VERSION ""

NS_ :

BS_:

BU_: VMM IMR BCS GSM EMS EPB SRS TEL ICM ACU VCU WCM TSCM Tester Test SCMRR SCMRL SCM SBM RCP PSDR PSDL PLGM PAS LCU IHU IBCM IAL HVSPRR HVSPRL HVSMR HVSM HVACF HUD GWM FRDCM FLDCM FCP FAPA ETC Diagnostic Messages AVAS AMP
VAL_TABLE_ VCU_VehDrvModNew 6 "reserved;" 5 "SPORT Mode;" 4 "Individual mode;" 3 "Comfort Mode;" 2 "ECO Mode;" 1 "reserved;" 0 "Invalid;" ;
VAL_TABLE_ VtSIg_VCU_EVPRepair 1 "EVP service" 0 "Normal" ;

BO_ 3221225472 VECTOR__INDEPENDENT_SIG_MSG: 0 Vector__XXX
 SG_ ACU_FCWSeatbeltPretensionWarnCfg : 0|2@0+ (1,0) [0|3] "" Vector__XXX
 SG_ ACU_FCWSeatVibrationWarnCfg : 0|2@0+ (1,0) [0|3] "" Vector__XXX
 SG_ ACU_FCWAcousticWarnCfg : 0|2@0+ (1,0) [0|3] "" Vector__XXX
 SG_ ACU_ACCStyleCfg : 0|2@0+ (1,0) [0|3] "" Vector__XXX
 SG_ ACU_BCMHornCfg : 0|2@0+ (1,0) [0|3] "" Vector__XXX
 SG_ ACU_BCMDTRLFuncCfg : 0|2@0+ (1,0) [0|3] "" Vector__XXX
 SG_ ACU_BCMRGearEnableRearWipeCfg : 0|2@0+ (1,0) [0|3] "" Vector__XXX
 SG_ ACU_BCMAutoLightSnsCfg : 0|3@0+ (1,0) [0|7] "" Vector__XXX
 SG_ ACU_BCMFollowMeHomeCfg : 0|2@0+ (1,0) [0|3] "" Vector__XXX
 SG_ ACU_BCMAutoUnlockCfg : 0|2@0+ (1,0) [0|3] "" Vector__XXX
 SG_ ACU_BCMRemoteUnlockCfg : 0|2@0+ (1,0) [0|3] "" Vector__XXX
 SG_ ACU_BCMFogLampTurnCfg : 0|2@0+ (1,0) [0|3] "" Vector__XXX
 SG_ ACU_BCMRemoteCtrlFDMRMCfg : 0|2@0+ (1,0) [0|3] "" Vector__XXX
 SG_ ACU_KickSnsCfg : 0|2@0+ (1,0) [0|3] "" Vector__XXX
 SG_ ACU_MaxTeleEngTimerCfg : 0|6@0+ (1,0) [0|30] "min" Vector__XXX
 SG_ ACU_PEPSOffCfg : 0|2@0+ (1,0) [0|3] "" Vector__XXX
 SG_ ACU_MaxTeleIGNOnTimerCfg : 0|6@0+ (1,0) [0|30] "min" Vector__XXX
 SG_ ACU_PEPSAPUCfg : 0|2@0+ (1,0) [0|3] "" Vector__XXX
 SG_ ACU_PEPSWALCfg : 0|2@0+ (1,0) [0|3] "" Vector__XXX
 SG_ ACU_ICMLanguageCfg : 0|2@0+ (1,0) [0|3] "" Vector__XXX
 SG_ ACU_ICMTimeModeCfg : 0|2@0+ (1,0) [0|3] "" Vector__XXX
 SG_ ACU_ICMWarnSoundVolCfg : 0|2@0+ (1,0) [0|3] "" Vector__XXX
 SG_ ACU_ICMSpdWarnCfg : 0|5@0+ (10,0) [0|200] "km/h" Vector__XXX
 SG_ ACU_PEPSSATOCfg : 0|2@0+ (1,0) [0|3] "" Vector__XXX
 SG_ ACU_PEPSWELCfg : 0|2@0+ (1,0) [0|3] "" Vector__XXX
 SG_ ACU_BCMOSRMAutoFoldCfg : 0|2@0+ (1,0) [0|3] "" Vector__XXX
 SG_ ACU_MSMKeyRecognitionCfg : 0|2@0+ (1,0) [0|3] "" Vector__XXX
 SG_ ACU_MSMWelcomeFuncCfg : 0|2@0+ (1,0) [0|3] "" Vector__XXX
 SG_ ACU_HVACFComfortCfg : 0|2@0+ (1,0) [0|3] "" Vector__XXX
 SG_ ACU_HVACFAirCirCfg : 0|2@0+ (1,0) [0|3] "" Vector__XXX
 SG_ ACU_HVACFACCfg : 0|2@0+ (1,0) [0|3] "" Vector__XXX
 SG_ ACU_LDW_WarnSnsCfg : 0|2@0+ (1,0) [0|3] "" Vector__XXX
 SG_ TEL_BTAvrcpPlayMode : 0|3@0+ (1,0) [0|7] "" Vector__XXX
 SG_ TEL_TelematicsRegisterSt : 0|3@0+ (1,0) [0|7] "" Vector__XXX
 SG_ TEL_BTAutoconectingSt : 0|1@0+ (1,0) [0|1] "" Vector__XXX
 SG_ TEL_BTPowerSt : 0|1@0+ (1,0) [0|1] "" Vector__XXX
 SG_ TEL_BTManualMode : 0|2@0+ (1,0) [0|3] "" Vector__XXX
 SG_ TEL_BTHisdel : 0|1@0+ (1,0) [0|1] "" Vector__XXX
 SG_ TEL_BTHandfreeSt : 0|1@0+ (1,0) [0|1] "" Vector__XXX
 SG_ TEL_BTAvrcpSt : 0|1@0+ (1,0) [0|1] "" Vector__XXX
 SG_ TEL_TelematicsModeActSt : 0|3@0+ (1,0) [0|7] "" Vector__XXX
 SG_ ACU_EVSwRq : 0|2@0+ (1,0) [0|3] "-" Vector__XXX
 SG_ BCS_2_Checksum : 0|8@0+ (1,0) [0|255] "" Vector__XXX
 SG_ BCS_2_MsgCounter : 0|4@0+ (1,0) [0|15] "" Vector__XXX
 SG_ BCM_BCAN_2_Checksum : 0|8@0+ (1,0) [0|255] "" Vector__XXX
 SG_ BCM_BCAN_2_MsgCounter : 0|4@0+ (1,0) [0|15] "" Vector__XXX
 SG_ ADAS_HWA_ILCWaitReasonLeft : 0|10@0+ (1,0) [0|1023] "" Vector__XXX
 SG_ ADAS_HWA_ILCWaitReasonRight : 0|10@0+ (1,0) [0|1023] "" Vector__XXX
 SG_ PAS_Mode : 0|3@0+ (1,0) [0|7] "-" Vector__XXX
 SG_ ICM_SetPedalLevelUp : 0|1@0+ (1,0) [0|1] "" Vector__XXX
 SG_ ICM_SetPedalLevelDown : 0|1@0+ (1,0) [0|1] "" Vector__XXX
 SG_ ACU_IFC_ZoneCode : 0|3@0+ (1,0) [0|7] "" Vector__XXX
 SG_ ACU_IFC_SpeedLimitUnit : 0|2@0+ (1,0) [0|3] "" Vector__XXX
 SG_ ACU_IFC_SpeedLimit : 0|8@0+ (1,0) [0|255] "km/h" Vector__XXX
 SG_ ACU_IFC_RoadType : 0|6@0+ (1,0) [0|63] "" Vector__XXX
 SG_ SRS_1_Checksum : 0|8@0+ (1,0) [0|255] "" Vector__XXX
 SG_ SRS_1_MsgCounter : 0|4@0+ (1,0) [0|15] "" Vector__XXX
 SG_ ICM_TripB : 0|14@0+ (0.1,0) [0|999.9] "km" Vector__XXX
 SG_ ICM_TripBVD : 0|1@0+ (1,0) [0|1] "" Vector__XXX
 SG_ ICM_TripA : 0|14@0+ (0.1,0) [0|999.9] "km" Vector__XXX
 SG_ ICM_TripAVD : 0|1@0+ (1,0) [0|1] "" Vector__XXX
 SG_ ICM_VehAverageSpd : 0|8@0+ (1,0) [0|254] "km/h" Vector__XXX
 SG_ VCU_AGSErr : 0|1@0+ (1,0) [0|1] "" Vector__XXX

BO_ 0 New_Message_209: 8 Vector__XXX
 SG_ New_Signal_2103 : 0|8@1+ (1,0) [0|0] "" Vector__XXX

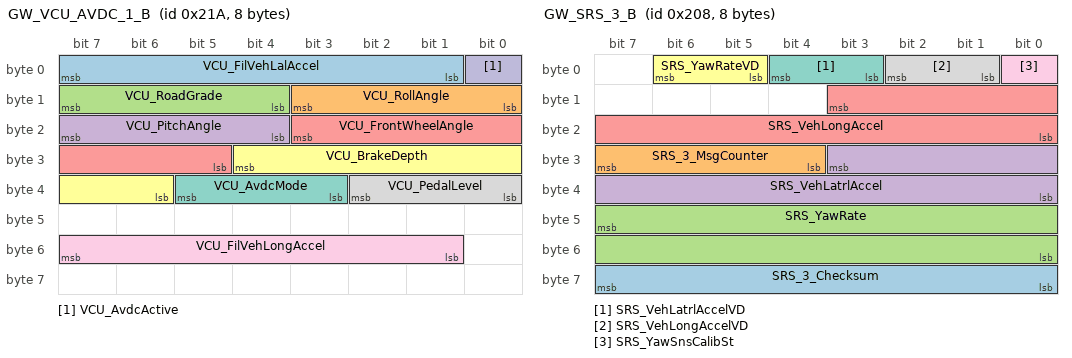
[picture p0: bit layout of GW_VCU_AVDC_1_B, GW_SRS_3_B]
BO_ 538 GW_VCU_AVDC_1_B: 8 GWM
 SG_ VCU_FilVehLalAccel : 7|7@0+ (0.15625,-10) [-10|9.84] "m/s2"  IHU
 SG_ VCU_RollAngle : 11|4@0+ (1,-8) [-5|5] "°"  IHU
 SG_ VCU_RoadGrade : 15|4@0+ (1,-8) [-8|7] "-"  IHU
 SG_ VCU_PitchAngle : 23|4@0+ (0.5,-4) [-3|3] "°"  IHU
 SG_ VCU_FrontWheelAngle : 19|7@0+ (1,-64) [-35|35] "°"  IHU
 SG_ VCU_BrakeDepth : 28|7@0+ (1,0) [0|100] ""  IHU
 SG_ VCU_AvdcMode : 37|3@0+ (1,0) [0|5] ""  IHU
 SG_ VCU_PedalLevel : 34|3@0+ (1,0) [1|5] ""  IHU
 SG_ VCU_FilVehLongAccel : 55|7@0+ (0.156,-10) [-10|9.84] ""  IHU
 SG_ VCU_AvdcActive : 0|1@0+ (1,0) [0|1] ""  IHU

BO_ 539 ICM_8_B: 8 IHU
 SG_ ICM_FuelTotalodometer : 19|20@0+ (1,0) [0|999999] ""  GWM
 SG_ ICM_EVTotalodometer : 7|20@0+ (1,0) [0|999999] ""  GWM

BO_ 880 GW_VCU_14_A_B: 8 GWM
 SG_ VCU_GasPedalActPstforMRR : 47|8@0+ (0.392,0) [0|99.96] ""  IHU
 SG_ VCU_GasPedalActPstforMRRVD : 27|1@0+ (1,0) [0|1] ""  IHU

BO_ 924 GW_IPS_OBC_1_B: 8 GWM
 SG_ IPS_OBCCC_St : 7|3@0+ (1,0) [0|7] ""  IHU

BO_ 520 GW_SRS_3_B: 8 GWM
 SG_ SRS_3_Checksum : 56|8@1- (1,0) [0|255] ""  IHU
 SG_ SRS_3_MsgCounter : 31|4@0+ (1,0) [0|15] ""  IHU
 SG_ SRS_YawRate : 47|16@0+ (0.01,-180) [-180|180] ""  IHU
 SG_ SRS_VehLatrlAccel : 27|12@0+ (0.001,-2) [-2|2] ""  IHU
 SG_ SRS_VehLongAccel : 11|12@0+ (0.001,-2) [-2|2] ""  IHU
 SG_ SRS_YawRateVD : 6|2@0+ (1,0) [0|3] ""  IHU
 SG_ SRS_VehLatrlAccelVD : 4|2@0+ (1,0) [0|3] ""  IHU
 SG_ SRS_VehLongAccelVD : 2|2@0+ (1,0) [0|3] ""  IHU
 SG_ SRS_YawSnsCalibSt : 0|1@0+ (1,0) [0|1] ""  IHU

BO_ 1536 GW_EMS_12_B: 8 GWM
 SG_ EMS_FrontWheelAngle : 19|7@0+ (1,-64) [-35|35] ""  IHU
 SG_ EMS_BrakeDepth : 28|7@0+ (1,0) [0|100] ""  IHU

BO_ 119 GW_TEL_16_B: 8 GWM
 SG_ TEL_ACU_VehSearchReq : 6|1@0+ (1,0) [0|1] ""  IHU

BO_ 1567 BCM_RLS_1_B: 8 IBCM
 SG_ RLS_RainfallLevel : 23|4@0+ (1,0) [0|15] ""  IHU

BO_ 412 GW_IFC_2_B: 8 GWM
 SG_ IFC_AssistParaSwitchReq : 54|1@0+ (1,0) [0|1] ""  IHU

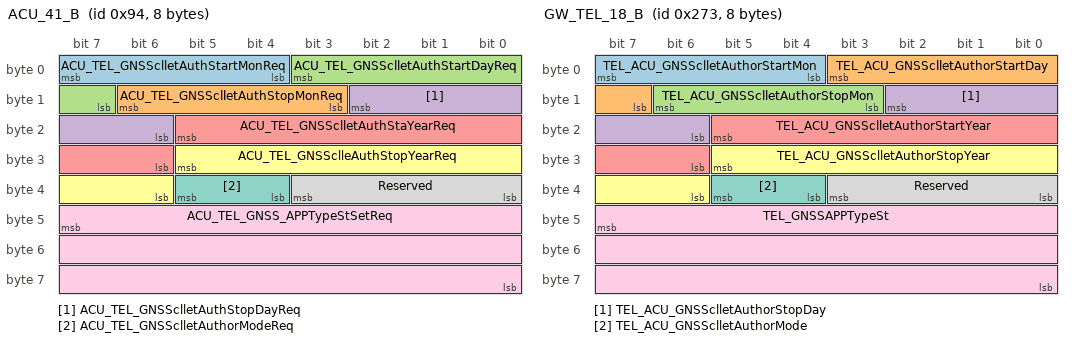
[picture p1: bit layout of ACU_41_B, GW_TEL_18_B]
BO_ 148 ACU_41_B: 8 IHU
 SG_ ACU_TEL_GNSSclletAuthStartMonReq : 7|4@0+ (1,0) [0|12] "" Vector__XXX
 SG_ ACU_TEL_GNSSclletAuthStopMonReq : 14|4@0+ (1,0) [0|12] "" Vector__XXX
 SG_ ACU_TEL_GNSSclletAuthStartDayReq : 3|5@0+ (1,0) [0|31] "" Vector__XXX
 SG_ ACU_TEL_GNSSclletAuthStopDayReq : 10|5@0+ (1,0) [0|31] "" Vector__XXX
 SG_ ACU_TEL_GNSSclletAuthStaYearReq : 21|8@0+ (1,2000) [2000|2255] "" Vector__XXX
 SG_ ACU_TEL_GNSSclleAuthStopYearReq : 29|8@0+ (1,2000) [2000|2255] "" Vector__XXX
 SG_ ACU_TEL_GNSSclletAuthorModeReq : 37|2@0+ (1,0) [0|3] "" Vector__XXX
 SG_ Reserved : 35|4@0+ (1,0) [0|15] "" Vector__XXX
 SG_ ACU_TEL_GNSS_APPTypeStSetReq : 47|24@0+ (1,0) [0|16777215] "" Vector__XXX

BO_ 627 GW_TEL_18_B: 8 GWM
 SG_ TEL_ACU_GNSSclletAuthorStartMon : 7|4@0+ (1,0) [0|12] ""  IHU
 SG_ TEL_ACU_GNSSclletAuthorStartDay : 3|5@0+ (1,0) [0|31] ""  IHU
 SG_ TEL_ACU_GNSSclletAuthorStopMon : 14|4@0+ (1,0) [0|12] ""  IHU
 SG_ TEL_ACU_GNSSclletAuthorStopDay : 10|5@0+ (1,0) [0|31] ""  IHU
 SG_ TEL_ACU_GNSSclletAuthorStartYear : 21|8@0+ (1,2000) [2000|2255] ""  IHU
 SG_ TEL_ACU_GNSSclletAuthorStopYear : 29|8@0+ (1,2000) [2000|2255] ""  IHU
 SG_ TEL_ACU_GNSSclletAuthorMode : 37|2@0+ (1,0) [0|3] ""  IHU
 SG_ Reserved : 35|4@0+ (1,0) [0|15] ""  IHU
 SG_ TEL_GNSSAPPTypeSt : 47|24@0+ (1,0) [0|16777215] ""  IHU

BO_ 886 GW_BCS_18_B: 8 GWM
 SG_ BCS_HDCFuncResp : 7|2@0+ (1,0) [0|3] ""  IHU
 SG_ BCS_ESPFuncResp : 5|2@0+ (1,0) [0|3] ""  IHU

BO_ 179 FAPA_2_B: 8 FAPA
 SG_ APA_VoiceReminder : 23|12@0+ (1,0) [0|4095] ""  IHU

BO_ 837 FAPA_PCS_1: 8 FAPA
 SG_ PCS_MirrorPageDownButton : 59|1@0+ (1,0) [0|1] ""  IHU
 SG_ PCS_ER_QuitReq : 58|1@0+ (1,0) [0|1] ""  IHU
 SG_ PCS_ER_EnterConfirm : 57|1@0+ (1,0) [0|1] ""  IHU
 SG_ PCS_ACU_DisplayReq : 56|1@0+ (1,0) [0|1] ""  IHU
 SG_ PCS_SoundReminderSt : 55|1@0+ (1,0) [0|1] ""  IHU
 SG_ PCS_HelpMenuSt : 54|1@0+ (1,0) [0|1] ""  IHU
 SG_ PCS_ReturnSt : 53|1@0+ (1,0) [0|1] ""  IHU
 SG_ PCS_RightBlindSpotViewSt : 52|1@0+ (1,0) [0|1] ""  IHU
 SG_ PCS_LeftBlindSpotViewSt : 51|1@0+ (1,0) [0|1] ""  IHU
 SG_ PCS_RVMButtonGroup : 50|3@0+ (1,0) [0|7] ""  IHU
 SG_ PCS_OperationSt : 41|2@0+ (1,0) [0|3] ""  IHU
 SG_ PCS_3DEnalbe : 39|1@0+ (1,0) [0|1] ""  IHU
 SG_ PCS_MODEnalbe : 38|1@0+ (1,0) [0|1] ""  IHU
 SG_ PCS_PASButtonPress : 37|1@0+ (1,0) [0|1] ""  IHU
 SG_ PCS_SteerIconInd : 36|3@0+ (1,0) [0|7] ""  IHU
 SG_ PCS_SteerWheelTurnDirInd : 33|2@0+ (1,0) [0|3] ""  IHU
 SG_ PCS_GuidOverlaySt : 31|2@0+ (1,0) [0|3] ""  IHU
 SG_ PCS_DriveDirInd : 29|2@0+ (1,0) [0|3] ""  IHU
 SG_ PCS_SystemType : 11|2@0+ (1,0) [0|3] ""  IHU
 SG_ PCS_VoiceReq : 27|4@0+ (1,0) [0|15] ""  IHU
 SG_ PCS_SingleViewInd : 23|4@0+ (1,0) [0|15] ""  IHU
 SG_ PCS_HMIIndex : 19|4@0+ (1,0) [0|15] ""  IHU
 SG_ PCS_EventRecordSt : 15|1@0+ (1,0) [0|1] ""  IHU
 SG_ PCS_CalibrateSt : 14|3@0+ (1,0) [0|7] ""  IHU
 SG_ PCS_VRSwitchFailSt : 1|1@0+ (1,0) [0|1] ""  IHU
 SG_ PCS_SystemSt : 0|1@0+ (1,0) [0|1] ""  IHU

BO_ 898 GW_BMS_7_B: 8 GWM
 SG_ BMS_BattSOE : 19|14@0+ (0.01,0) [0|163.83] "kWh"  IHU

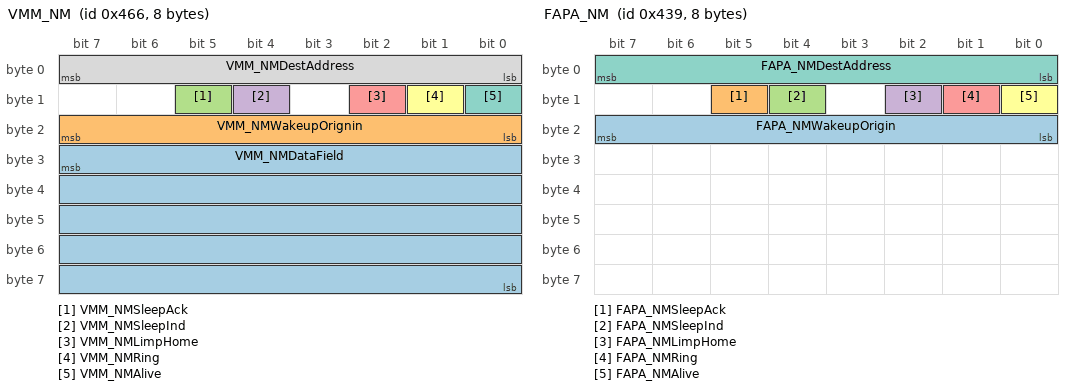
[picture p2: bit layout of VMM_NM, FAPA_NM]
BO_ 1126 VMM_NM: 8 VMM
 SG_ VMM_NMDataField : 31|40@0+ (1,0) [0|1] ""  IHU
 SG_ VMM_NMWakeupOrignin : 23|8@0+ (1,0) [0|255] ""  IHU
 SG_ VMM_NMSleepAck : 13|1@0+ (1,0) [0|1] ""  IHU
 SG_ VMM_NMSleepInd : 12|1@0+ (1,0) [0|1] ""  IHU
 SG_ VMM_NMLimpHome : 10|1@0+ (1,0) [0|1] ""  IHU
 SG_ VMM_NMRing : 9|1@0+ (1,0) [0|1] ""  IHU
 SG_ VMM_NMAlive : 8|1@0+ (1,0) [0|1] ""  IHU
 SG_ VMM_NMDestAddress : 7|8@0+ (1,0) [0|255] ""  IHU

BO_ 34 VMM_2_B: 8 VMM
 SG_ VMM_FailtureReasonSt : 2|3@0+ (1,0) [0|7] ""  IHU

BO_ 869 VMM_1_B: 8 VMM
 SG_ VMM_Crash_Flg : 53|1@0+ (1,0) [0|1] ""  IHU
 SG_ VMM_SysCfgst : 52|1@0+ (1,0) [0|1] ""  IHU
 SG_ VMM_WarningTpyCfgst : 51|1@0+ (1,0) [0|1] ""  IHU
 SG_ VMM_SnsCfgSt : 50|3@0+ (1,0) [0|7] ""  IHU
 SG_ VMM_WarningType : 17|2@0+ (1,0) [0|3] ""  IHU

BO_ 1081 FAPA_NM: 8 FAPA
 SG_ FAPA_NMWakeupOrigin : 23|8@0+ (1,0) [0|255] ""  IHU
 SG_ FAPA_NMSleepAck : 13|1@0+ (1,0) [0|1] ""  IHU
 SG_ FAPA_NMSleepInd : 12|1@0+ (1,0) [0|1] ""  IHU
 SG_ FAPA_NMLimpHome : 10|1@0+ (1,0) [0|1] ""  IHU
 SG_ FAPA_NMRing : 9|1@0+ (1,0) [0|1] ""  IHU
 SG_ FAPA_NMAlive : 8|1@0+ (1,0) [0|1] ""  IHU
 SG_ FAPA_NMDestAddress : 7|8@0+ (1,0) [0|255] ""  IHU

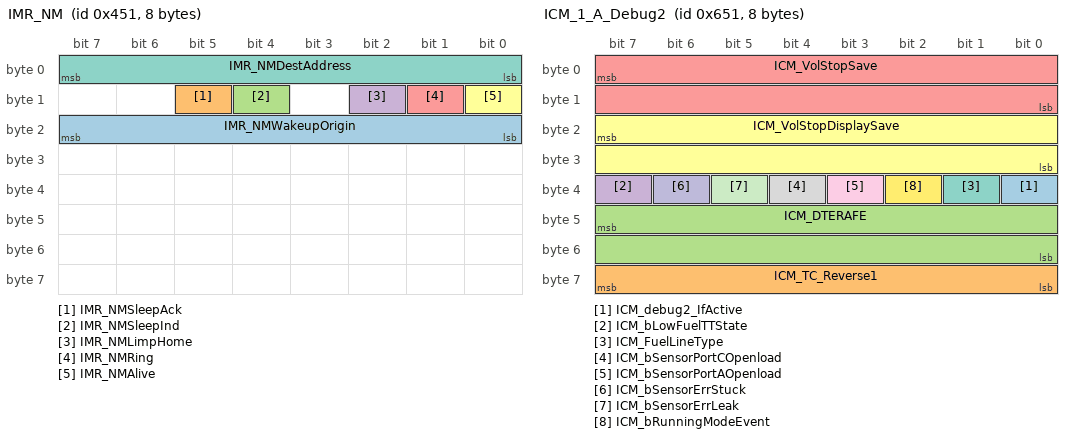
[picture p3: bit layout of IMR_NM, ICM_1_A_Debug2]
BO_ 1105 IMR_NM: 8 IMR
 SG_ IMR_NMWakeupOrigin : 23|8@0+ (1,0) [0|255] ""  IHU
 SG_ IMR_NMSleepAck : 13|1@0+ (1,0) [0|1] ""  IHU
 SG_ IMR_NMSleepInd : 12|1@0+ (1,0) [0|1] ""  IHU
 SG_ IMR_NMLimpHome : 10|1@0+ (1,0) [0|1] ""  IHU
 SG_ IMR_NMRing : 9|1@0+ (1,0) [0|1] ""  IHU
 SG_ IMR_NMAlive : 8|1@0+ (1,0) [0|1] ""  IHU
 SG_ IMR_NMDestAddress : 7|8@0+ (1,0) [0|22] ""  IHU

BO_ 648 GW_BCS_20_P_B: 8 GWM
 SG_ BCS_BrakeFluid_Warning : 45|2@0+ (1,0) [0|3] ""  IHU
 SG_ BCS_CST_Status : 40|2@0+ (1,0) [0|3] ""  IHU
 SG_ BCS_TwoFoot_DriveWarning : 41|1@0+ (1,0) [0|1] ""  IHU
 SG_ BCS_System_Status : 32|3@0+ (1,0) [0|7] ""  IHU
 SG_ BCS_FWA_warning : 34|2@0+ (1,0) [0|3] ""  IHU

BO_ 1617 ICM_1_A_Debug2: 8 IHU
 SG_ ICM_debug2_IfActive : 32|1@0+ (1,0) [0|1] "" Vector__XXX
 SG_ ICM_TC_Reverse1 : 63|8@0+ (1,0) [0|0] ""  Test,Tester
 SG_ ICM_DTERAFE : 47|16@0+ (0.1,0) [0|6553.5] "L/100km"  Test,Tester
 SG_ ICM_bLowFuelTTState : 39|1@0+ (1,0) [0|1] ""  Test,Tester
 SG_ ICM_VolStopSave : 7|16@0+ (0.001,0) [0|65.535] "L"  Test,Tester
 SG_ ICM_VolStopDisplaySave : 23|16@0+ (0.001,0) [0|65.535] "L"  Test,Tester
 SG_ ICM_FuelLineType : 33|1@0+ (1,0) [0|1] ""  Test,Tester
 SG_ ICM_bSensorPortCOpenload : 36|1@0+ (1,0) [0|1] ""  Test,Tester
 SG_ ICM_bSensorPortAOpenload : 35|1@0+ (1,0) [0|1] ""  Test,Tester
 SG_ ICM_bSensorErrStuck : 38|1@0+ (1,0) [0|1] ""  Test,Tester
 SG_ ICM_bSensorErrLeak : 37|1@0+ (1,0) [0|1] ""  Test,Tester
 SG_ ICM_bRunningModeEvent : 34|1@0+ (1,0) [0|1] ""  Test,Tester

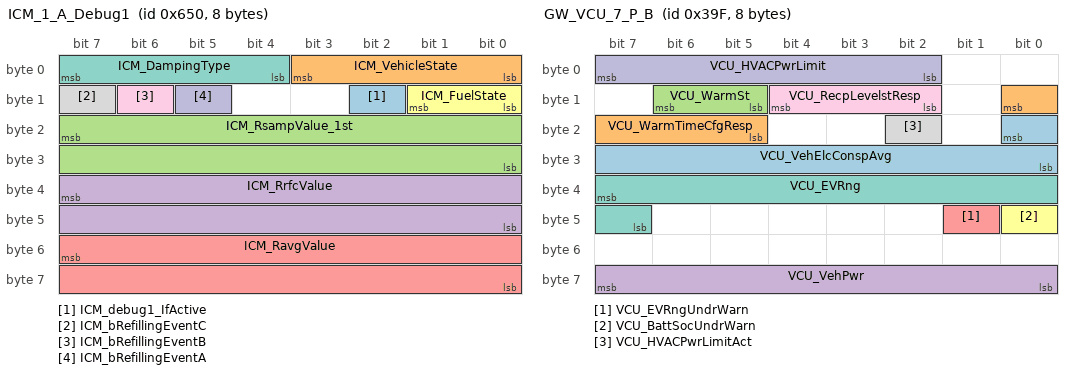
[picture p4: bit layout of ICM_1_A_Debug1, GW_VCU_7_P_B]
BO_ 1616 ICM_1_A_Debug1: 8 IHU
 SG_ ICM_debug1_IfActive : 10|1@0+ (1,0) [0|1] "" Vector__XXX
 SG_ ICM_VehicleState : 3|4@0+ (1,0) [0|15] ""  Test,Tester
 SG_ ICM_RsampValue_1st : 23|16@0+ (0.1,0) [0|6553.5] "ohm"  Test,Tester
 SG_ ICM_RrfcValue : 39|16@0+ (1,-50) [-50|65485] "ohm"  Test,Tester
 SG_ ICM_RavgValue : 55|16@0+ (0.1,0) [0|6553.5] ""  Test,Tester
 SG_ ICM_FuelState : 9|2@0+ (1,0) [0|3] ""  Test,Tester
 SG_ ICM_DampingType : 7|4@0+ (1,0) [0|15] ""  Test,Tester
 SG_ ICM_bRefillingEventC : 15|1@0+ (1,0) [0|1] ""  Test,Tester
 SG_ ICM_bRefillingEventB : 14|1@0+ (1,0) [0|1] ""  Test,Tester
 SG_ ICM_bRefillingEventA : 13|1@0+ (1,0) [0|1] ""  Test,Tester

BO_ 1733 ICM_1_A_Debug3: 8 IHU
 SG_ ICM_debug3_IfActive : 55|1@0+ (1,0) [0|1] "" Vector__XXX
 SG_ ICM_DTECalVal : 54|15@0+ (0.1,0) [0|3276.7] "km"  Test,Tester
 SG_ ICM_VolOfDisplay : 39|16@0+ (0.001,0) [0|65.535] "L"  Test,Tester
 SG_ ICM_VolOfCycleResult : 23|16@0+ (0.001,0) [0|65.535] "L"  Test,Tester
 SG_ ICM_VolOfAvgResult : 7|16@0+ (0.001,0) [0|65.535] "L"  Test,Tester

BO_ 1734 ICM_1_A_Debug4: 8 IHU
 SG_ ICM_debug4_IfActive : 55|1@0+ (1,0) [0|1] "" Vector__XXX
 SG_ ICM_TC_Reverse2 : 54|15@0+ (1,0) [0|32767] ""  Test,Tester
 SG_ ICM_FuelPulse : 23|32@0+ (0.001,0) [0|4294967.295] "ml"  Test,Tester
 SG_ ICM_DTEDispVal : 7|16@0+ (0.1,0) [0|6553.5] "km"  Test,Tester

BO_ 143 ACU_42_B: 8 IHU
 SG_ ACU_VMM_Sensitivity : 3|2@0+ (1,0) [0|3] "" Vector__XXX
 SG_ ACU_VMM_SysCfg : 1|2@0+ (1,0) [0|3] "" Vector__XXX

BO_ 1005 TEL_6: 8 TEL
 SG_ not_used : 9|50@0+ (1,0) [0|0] "" Vector__XXX
 SG_ TEL_BookChrgStartRemainingMin : 15|6@0+ (1,0) [0|59] ""  IHU
 SG_ TEL_BookChrgStartRemainingHour : 7|5@0+ (1,0) [0|23] ""  IHU
 SG_ TEL_BookChrgStartRemainingDay : 2|3@0+ (1,0) [0|6] ""  IHU

BO_ 1004 TEL_5: 8 TEL
 SG_ TBOX_ACU_BookChrgStopYear : 63|8@0+ (1,2000) [2000|2255] ""  IHU
 SG_ TBOX_ACU_BookChrgStartYear : 55|8@0+ (1,2000) [2000|2255] ""  IHU
 SG_ TBOX_ACU_RepeatBookChrgDay7 : 47|1@0+ (1,0) [0|1] ""  IHU
 SG_ TBOX_ACU_RepeatBookChrgDay6 : 46|1@0+ (1,0) [0|1] ""  IHU
 SG_ TBOX_ACU_RepeatBookChrgDay5 : 45|1@0+ (1,0) [0|1] ""  IHU
 SG_ TBOX_ACU_RepeatBookChrgDay4 : 44|1@0+ (1,0) [0|1] ""  IHU
 SG_ TBOX_ACU_RepeatBookChrgDay3 : 43|1@0+ (1,0) [0|1] ""  IHU
 SG_ TBOX_ACU_RepeatBookChrgDay2 : 42|1@0+ (1,0) [0|1] ""  IHU
 SG_ TBOX_ACU_RepeatBookChrgDay1 : 41|1@0+ (1,0) [0|1] ""  IHU
 SG_ TBOX_ACU_BookChrgMode : 40|1@0+ (1,0) [0|1] ""  IHU
 SG_ TBOX_ACU_BookChrgStopMin : 37|6@0+ (1,0) [0|59] ""  IHU
 SG_ TBOX_ACU_BookChrgStopHour : 26|5@0+ (1,0) [0|23] ""  IHU
 SG_ TBOX_ACU_BookChrgStopDay : 31|5@0+ (1,0) [0|31] ""  IHU
 SG_ TBOX_ACU_BookChrgStopMon : 19|4@0+ (1,0) [0|12] ""  IHU
 SG_ TBOX_ACU_BookChrgStartMin : 9|6@0+ (1,0) [0|59] ""  IHU
 SG_ TBOX_ACU_BookChrgStartHour : 14|5@0+ (1,0) [0|23] ""  IHU
 SG_ TBOX_ACU_BookChrgStartDay : 3|5@0+ (1,0) [0|31] ""  IHU
 SG_ TBOX_ACU_BookChrgStartMon : 7|4@0+ (1,0) [0|12] ""  IHU

BO_ 74 ACU_14_B: 8 IHU
 SG_ ACU_TBOX_BookChrgStopYear : 63|8@0+ (1,2000) [2000|2255] "" Vector__XXX
 SG_ ACU_TBOX_BookChrgStartYear : 55|8@0+ (1,2000) [2000|2255] "" Vector__XXX
 SG_ ACU_TBOX_RepeatBookChrgDay7 : 47|1@0+ (1,0) [0|1] "" Vector__XXX
 SG_ ACU_TBOX_RepeatBookChrgDay6 : 46|1@0+ (1,0) [0|1] "" Vector__XXX
 SG_ ACU_TBOX_RepeatBookChrgDay5 : 45|1@0+ (1,0) [0|1] "" Vector__XXX
 SG_ ACU_TBOX_RepeatBookChrgDay4 : 44|1@0+ (1,0) [0|1] "" Vector__XXX
 SG_ ACU_TBOX_RepeatBookChrgDay3 : 43|1@0+ (1,0) [0|1] "" Vector__XXX
 SG_ ACU_TBOX_RepeatBookChrgDay2 : 42|1@0+ (1,0) [0|1] "" Vector__XXX
 SG_ ACU_TBOX_RepeatBookChrgDay1 : 41|1@0+ (1,0) [0|1] "" Vector__XXX
 SG_ ACU_TBOX_BookChrgMode : 40|1@0+ (1,0) [0|1] "" Vector__XXX
 SG_ ACU_TBOX_BookChrgStoptMin : 37|6@0+ (1,0) [0|59] "" Vector__XXX
 SG_ ACU_TBOX_BookChrgStartHour : 14|5@0+ (1,0) [0|23] "" Vector__XXX
 SG_ ACU_TBOX_BookChrgStopHour : 26|5@0+ (1,0) [0|23] "" Vector__XXX
 SG_ ACU_TBOX_BookChrgStopDay : 31|5@0+ (1,0) [0|31] "" Vector__XXX
 SG_ ACU_TBOX_BookChrgStartMin : 9|6@0+ (1,0) [0|59] "" Vector__XXX
 SG_ ACU_TBOX_BookChrgStopMon : 19|4@0+ (1,0) [0|12] "" Vector__XXX
 SG_ ACU_TBOX_BookChrgStartDay : 3|5@0+ (1,0) [0|31] "" Vector__XXX
 SG_ ACU_TBOX_BookChrgStartMon : 7|4@0+ (1,0) [0|12] "" Vector__XXX

BO_ 832 GW_EMS_3_B: 8 GWM
 SG_ EMS_GPFLightSt : 55|2@0+ (1,0) [0|3] ""  IHU
 SG_ EMS_GasPedalActPstVD : 5|1@0+ (1,0) [0|1] ""  IHU
 SG_ EMS_GasPedalActPst : 31|8@0+ (0.392,0) [0|100] ""  IHU
 SG_ EMS_FuleCapAjarSt : 3|1@0+ (1,0) [0|1] ""  IHU
 SG_ EMS_FuelPressureReleaseStDis : 2|3@0+ (1,0) [0|7] ""  IHU

BO_ 350 IMR_1_B: 8 IMR
 SG_ IMR_screenreminder : 37|1@0+ (1,0) [0|1] ""  IHU
 SG_ IMR_WarmTimer : 21|6@0+ (1,0) [0|1] ""  IHU
 SG_ IMR_Mode : 2|2@0+ (1,0) [0|1] ""  IHU
 SG_ IMR_Error : 3|1@0+ (1,0) [0|1] ""  IHU

BO_ 927 GW_VCU_7_P_B: 8 GWM
 SG_ VCU_VehElcConspAvg : 16|9@0+ (0.2,-51) [-51|51] "kWh/100km"  IHU
 SG_ VCU_WarmTimeCfgResp : 8|4@0+ (1,0) [0|15] ""  IHU
 SG_ VCU_WarmSt : 14|2@0+ (1,0) [0|3] ""  IHU
 SG_ VCU_VehPwr : 63|8@0+ (2,-200) [-200|300] ""  ICM,IHU,HVACF
 SG_ VCU_EVRngUndrWarn : 41|1@0+ (1,0) [0|1] ""  ICM,IHU
 SG_ VCU_BattSocUndrWarn : 40|1@0+ (1,0) [0|1] ""  ICM,IHU,HVACF,TEL
 SG_ VCU_EVRng : 39|9@0+ (1,0) [0|511] ""  ICM,IHU
 SG_ VCU_HVACPwrLimitAct : 18|1@0+ (1,0) [0|1] ""  ICM,IHU,HVACF,TEL
 SG_ VCU_RecpLevelstResp : 12|3@0+ (1,0) [0|7] ""  TEL,ICM,IHU,ACU
 SG_ VCU_HVACPwrLimit : 7|6@0+ (200,0) [0|12600] ""  HVACF,TEL,ICM,IHU

BO_ 912 GW_VCU_24_P_B: 8 GWM
 SG_ VCU_VehDrvModNew : 34|3@0+ (1,0) [0|7] "-"  ICM,IHU
 SG_ VCU_PedalMapSt : 36|2@0+ (1,0) [0|3] ""  IHU,ICM
 SG_ VCU_ICM_ClntFillingFault : 37|1@0+ (1,0) [0|1] "" Vector__XXX
 SG_ VCU_DrvChgDchgDsp : 5|2@0+ (1,0) [0|3] ""  ICM,IHU

BO_ 779 GW_VCU_20_P_B: 8 GWM
 SG_ VCU_DerateFault : 51|1@0+ (1,0) [0|1] ""  IHU
 SG_ VCU_SysFault : 52|1@0+ (1,0) [0|1] ""  IHU

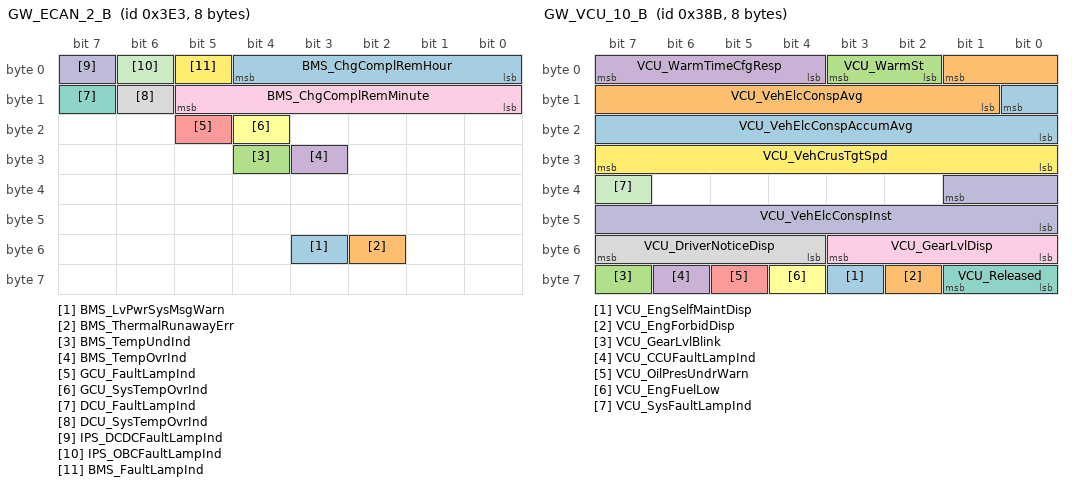
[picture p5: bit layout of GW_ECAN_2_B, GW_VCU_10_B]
BO_ 995 GW_ECAN_2_B: 8 GWM
 SG_ BMS_LvPwrSysMsgWarn : 51|1@0+ (1,0) [0|1] ""  ICM,IHU
 SG_ BMS_ThermalRunawayErr : 50|1@0+ (1,0) [0|1] ""  ICM,IHU
 SG_ BMS_TempUndInd : 28|1@0+ (1,0) [0|1] ""  ICM,IHU
 SG_ BMS_TempOvrInd : 27|1@0+ (1,0) [0|1] ""  ICM,IHU
 SG_ GCU_FaultLampInd : 21|1@0+ (1,0) [0|1] ""  ICM,IHU
 SG_ GCU_SysTempOvrInd : 20|1@0+ (1,0) [0|1] ""  ICM,IHU
 SG_ DCU_FaultLampInd : 15|1@0+ (1,0) [0|1] ""  ICM,IHU
 SG_ DCU_SysTempOvrInd : 14|1@0+ (1,0) [0|1] ""  IHU,ICM
 SG_ BMS_ChgComplRemMinute : 13|6@0+ (1,0) [0|59] ""  ICM,IHU
 SG_ IPS_DCDCFaultLampInd : 7|1@0+ (1,0) [0|1] ""  ICM,IHU
 SG_ IPS_OBCFaultLampInd : 6|1@0+ (1,0) [0|1] ""  ICM,IHU
 SG_ BMS_FaultLampInd : 5|1@0+ (1,0) [0|1] ""  ICM,IHU
 SG_ BMS_ChgComplRemHour : 4|5@0+ (1,0) [0|23] ""  ICM,IHU

BO_ 811 GW_VCU_41_E_B: 8 GWM
 SG_ VCU_DischgSetInfo : 19|2@0+ (1,0) [0|3] ""  ICM,IHU
 SG_ VCU_ChgSetInfo : 12|3@0+ (1,0) [0|7] ""  ICM,IHU
 SG_ VCU_VehChgDischgSt : 7|8@0+ (1,0) [0|255] ""  ICM,IHU

BO_ 907 GW_VCU_10_B: 8 GWM
 SG_ VCU_EngSelfMaintDisp : 59|1@0+ (1,0) [0|1] ""  IHU
 SG_ VCU_EngForbidDisp : 58|1@0+ (1,0) [0|1] ""  IHU
 SG_ VCU_GearLvlBlink : 63|1@0+ (1,0) [0|1] ""  GSM,ICM,IHU
 SG_ VCU_CCUFaultLampInd : 62|1@0+ (1,0) [0|1] ""  ICM,IHU
 SG_ VCU_OilPresUndrWarn : 61|1@0+ (1,0) [0|1] ""  ICM,IHU
 SG_ VCU_EngFuelLow : 60|1@0+ (1,0) [0|1] ""  ICM,IHU,EMS
 SG_ VCU_Released : 57|2@0+ (1,0) [0|3] ""  EMS,ICM,IHU,IBCM,TEL
 SG_ VCU_DriverNoticeDisp : 55|4@0+ (1,0) [0|15] ""  ICM,IHU
 SG_ VCU_GearLvlDisp : 51|4@0+ (1,0) [0|15] ""  GSM,ICM,IHU,HVACF,FLDCM,FRDCM,PLGM,TEL
 SG_ VCU_VehElcConspInst : 33|10@0+ (0.1,0) [0|102.3] ""  ICM,IHU
 SG_ VCU_SysFaultLampInd : 39|1@0+ (1,0) [0|1] ""  ICM,IHU
 SG_ VCU_VehCrusTgtSpd : 31|8@0+ (1,0) [0|255] ""  ICM,IHU
 SG_ VCU_VehElcConspAccumAvg : 8|9@0+ (0.2,-51) [-51|51] ""  ICM,IHU
 SG_ VCU_VehElcConspAvg : 1|9@0+ (0.2,-51) [-51|51.1] ""  ICM,IHU
 SG_ VCU_WarmSt : 3|2@0+ (1,0) [0|3] ""  IHU,ACU
 SG_ VCU_WarmTimeCfgResp : 7|4@0+ (1,0) [0|15] ""  IHU,ACU

BO_ 848 GW_VCU_1_B: 8 GWM
 SG_ VCU_WarmEngStartDisp : 23|1@0+ (1,0) [0|1] ""  IHU
 SG_ VCU_PrecResHotMsg : 53|2@0+ (1,0) [0|3] ""  IHU
 SG_ VCU_ChgTimeDspType : 58|3@0+ (1,0) [0|7] ""  IHU
 SG_ VCU_PlgConnSt : 63|1@0+ (1,0) [0|1] ""  IHU
 SG_ VCU_EVPRepair : 37|1@0+ (1,0) [0|1] ""  IHU
 SG_ VCU_ARBWarnNotice : 20|1@0+ (1,0) [0|1] ""  IHU
 SG_ VCU_EVButtonNoticeDisp : 34|1@0+ (1,0) [0|1] ""  IHU
 SG_ VCU_PGearErrNotice : 5|2@0+ (1,0) [0|3] ""  IHU
 SG_ VCU_BuzReq : 21|1@0+ (1,0) [0|1] ""  IHU
 SG_ VCU_DerateLampSt : 62|2@0+ (1,0) [0|3] ""  IHU
 SG_ VCU_EVSt : 51|1@0+ (1,0) [0|1] ""  IHU
 SG_ VCU_VehAvailDriveStMsgWarn : 60|1@0+ (1,0) [0|1] ""  IHU
 SG_ VCU_ThermalMsgWarn : 59|1@0+ (1,0) [0|1] ""  ICM,IHU,ACU,TEL
 SG_ VCU_VehRdySt_Rddy : 38|1@0+ (1,0) [0|1] ""  ACU,ICM,IHU,AVAS
 SG_ VCU_VehRdySt : 22|1@0+ (1,0) [0|1] ""  GSM,EMS,BCS,EPB,ICM,IHU,AVAS,ACU,TEL
 SG_ VCU_ElcVcuuPumpErr : 15|1@0+ (1,0) [0|1] ""  ICM,IHU,AVAS,ACU,TEL
 SG_ VCU_FaultLampInd : 14|2@0+ (1,0) [0|3] ""  ICM,IHU,AVAS,ACU,TEL
 SG_ VCU_VehCrusSt : 7|2@0+ (1,0) [0|3] ""  SRS,AVAS,TEL,ICM,IHU,ACU,GWM
 SG_ VCU_ElcSysFault : 3|4@0+ (1,0) [0|15] ""  AVAS,TEL,HVACF,ICM,IHU,ACU
 SG_ VCU_OperatingMode : 50|3@0+ (1,0) [0|7] ""  IHU
 SG_ VCU_BMS_BattSocDisp : 31|8@0+ (0.3937,0) [0|100] ""  IHU,ACU
 SG_ VCU_VehDrvMod : 18|3@0+ (1,0) [0|7] ""  IHU,ACU
 SG_ VCU_PwrFlowMode : 12|5@0+ (1,0) [0|31] ""  IHU,ACU

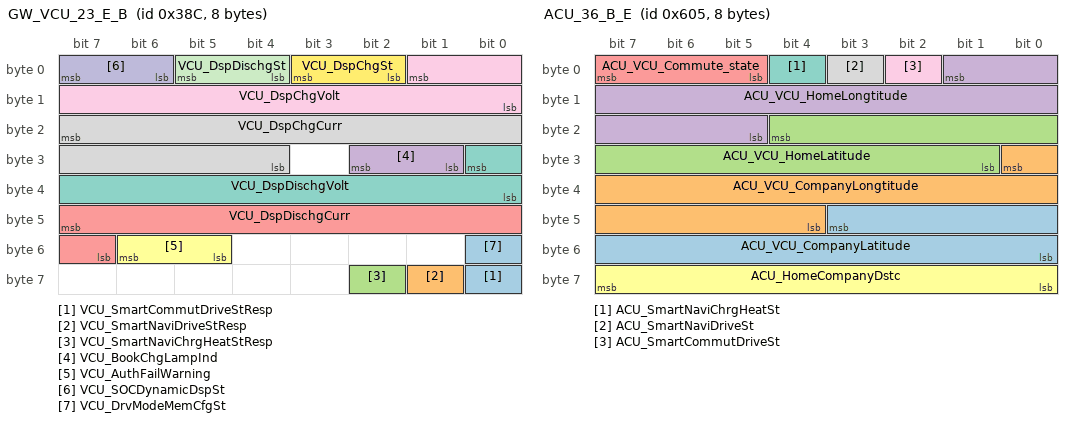
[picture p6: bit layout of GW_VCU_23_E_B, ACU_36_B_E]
BO_ 908 GW_VCU_23_E_B: 8 GWM
 SG_ VCU_SmartCommutDriveStResp : 56|1@0+ (1,0) [0|1] ""  IHU
 SG_ VCU_SmartNaviDriveStResp : 57|1@0+ (1,0) [0|1] ""  IHU
 SG_ VCU_SmartNaviChrgHeatStResp : 58|1@0+ (1,0) [0|1] ""  IHU
 SG_ VCU_BookChgLampInd : 26|2@0+ (1,0) [0|3] ""  IHU
 SG_ VCU_DspDischgCurr : 47|9@0+ (0.1,0) [0|51.1] ""  IHU,ICM
 SG_ VCU_AuthFailWarning : 54|2@0+ (1,0) [0|3] ""  TEL,ICM,IHU
 SG_ VCU_DspDischgVolt : 24|9@0+ (1,0) [0|511] ""  IHU,ICM
 SG_ VCU_DspChgCurr : 23|12@0+ (0.1,0) [0|409.5] ""  IHU,ICM
 SG_ VCU_DspChgVolt : 1|10@0+ (1,0) [0|1023] ""  IHU,ICM
 SG_ VCU_SOCDynamicDspSt : 7|2@0+ (1,0) [0|3] ""  ICM,IHU
 SG_ VCU_DspDischgSt : 5|2@0+ (1,0) [0|3] ""  ICM,IHU
 SG_ VCU_DspChgSt : 3|2@0+ (1,0) [0|3] ""  ICM,IHU
 SG_ VCU_DrvModeMemCfgSt : 48|1@0+ (1,0) [0|1] ""  IHU,ACU

BO_ 1541 ACU_36_B_E: 8 IHU
 SG_ ACU_VCU_CompanyLatitude : 43|12@0+ (0.015,0) [0|61.425] ""  GWM
 SG_ ACU_VCU_CompanyLongtitude : 24|13@0+ (0.015,20) [20|142.865] ""  GWM
 SG_ ACU_VCU_HomeLatitude : 20|12@0+ (0.015,0) [0|61.425] ""  GWM
 SG_ ACU_VCU_HomeLongtitude : 1|13@0+ (0.015,20) [20|142.865] ""  GWM
 SG_ ACU_VCU_Commute_state : 7|3@0+ (1,0) [0|7] ""  GWM
 SG_ ACU_HomeCompanyDstc : 63|8@0+ (1,0) [0|255] ""  GWM
 SG_ ACU_SmartNaviChrgHeatSt : 4|1@0+ (1,0) [0|1] ""  GWM
 SG_ ACU_SmartNaviDriveSt : 3|1@0+ (1,0) [0|1] ""  GWM
 SG_ ACU_SmartCommutDriveSt : 2|1@0+ (1,0) [0|1] ""  GWM

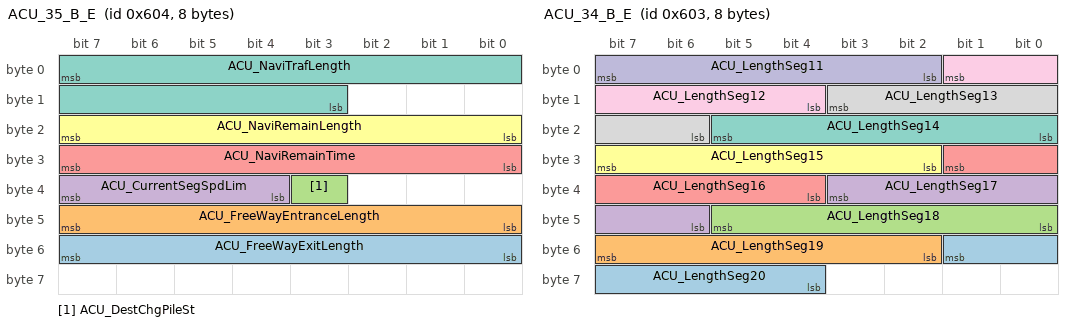
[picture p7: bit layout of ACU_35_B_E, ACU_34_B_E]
BO_ 1540 ACU_35_B_E: 8 IHU
 SG_ ACU_FreeWayExitLength : 55|8@0+ (1,0) [0|25.5] "" Vector__XXX
 SG_ ACU_FreeWayEntranceLength : 47|8@0+ (1,0) [0|25.5] ""  VCU,GWM
 SG_ ACU_DestChgPileSt : 35|1@0+ (1,0) [0|1] ""  VCU,GWM
 SG_ ACU_CurrentSegSpdLim : 39|4@0+ (1,0) [0|12] ""  GWM,VCU
 SG_ ACU_NaviRemainTime : 31|8@0+ (1,0) [0|255] ""  GWM,VCU
 SG_ ACU_NaviRemainLength : 23|8@0+ (1,0) [0|255] ""  VCU,GWM
 SG_ ACU_NaviTrafLength : 7|13@0+ (1,0) [0|8000] ""  GWM,VCU

BO_ 1539 ACU_34_B_E: 8 IHU
 SG_ ACU_LengthSeg20 : 49|6@0+ (0.5,0) [0|31.5] ""  VCU,GWM
 SG_ ACU_LengthSeg19 : 55|6@0+ (0.5,0) [0|31.5] ""  VCU,GWM
 SG_ ACU_LengthSeg18 : 45|6@0+ (0.5,0) [0|31.5] ""  GWM,VCU
 SG_ ACU_LengthSeg17 : 35|6@0+ (0.5,0) [0|31.5] ""  VCU,GWM
 SG_ ACU_LengthSeg16 : 25|6@0+ (0.5,0) [0|31.5] ""  VCU,GWM
 SG_ ACU_LengthSeg15 : 31|6@0+ (0.5,0) [0|31.5] ""  GWM,VCU
 SG_ ACU_LengthSeg14 : 21|6@0+ (0.5,0) [0|31.5] ""  VCU,GWM
 SG_ ACU_LengthSeg13 : 11|6@0+ (0.5,0) [0|31.5] ""  VCU,GWM
 SG_ ACU_LengthSeg12 : 1|6@0+ (0.5,0) [0|31.5] ""  VCU,GWM
 SG_ ACU_LengthSeg11 : 7|6@0+ (0.5,0) [0|31.5] ""  VCU,GWM

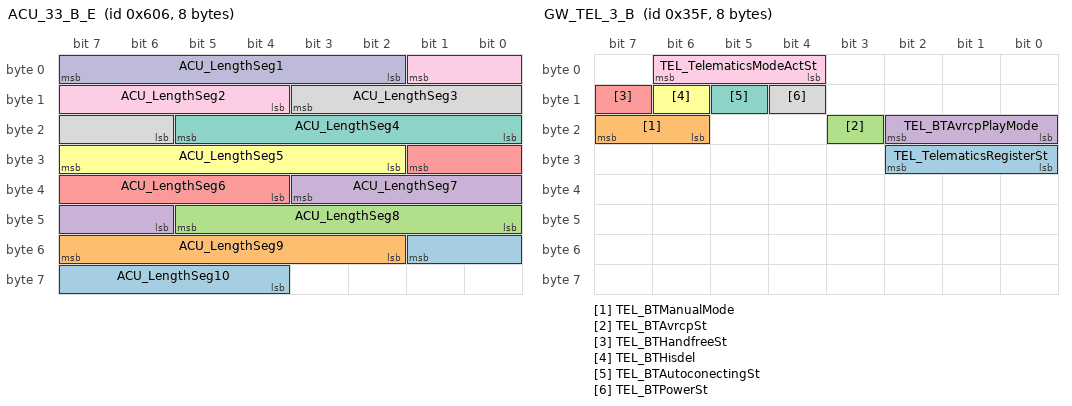
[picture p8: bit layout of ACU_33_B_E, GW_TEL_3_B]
BO_ 1542 ACU_33_B_E: 8 IHU
 SG_ ACU_LengthSeg10 : 49|6@0+ (0.5,0) [0|31.5] ""  VCU,GWM
 SG_ ACU_LengthSeg9 : 55|6@0+ (0.5,0) [0|31.5] ""  VCU,GWM
 SG_ ACU_LengthSeg8 : 45|6@0+ (0.5,0) [0|31.5] ""  GWM,VCU
 SG_ ACU_LengthSeg7 : 35|6@0+ (0.5,0) [0|31.5] ""  VCU,GWM
 SG_ ACU_LengthSeg6 : 25|6@0+ (0.5,0) [0|31.5] ""  VCU,GWM
 SG_ ACU_LengthSeg5 : 31|6@0+ (0.5,0) [0|31.5] ""  VCU,GWM
 SG_ ACU_LengthSeg4 : 21|6@0+ (0.5,0) [0|31.5] ""  VCU,GWM
 SG_ ACU_LengthSeg3 : 11|6@0+ (0.5,0) [0|31.5] ""  GWM,VCU
 SG_ ACU_LengthSeg2 : 1|6@0+ (0.5,0) [0|31.5] ""  GWM,VCU
 SG_ ACU_LengthSeg1 : 7|6@0+ (0.5,0) [0|31.5] ""  VCU,GWM

BO_ 1537 ACU_32_B_E: 8 IHU
 SG_ ACU_TrafficSeg20 : 62|3@0+ (1,0) [0|7] ""  VCU,GWM
 SG_ ACU_TrafficSeg19 : 49|3@0+ (1,0) [0|7] ""  VCU,GWM
 SG_ ACU_TrafficSeg18 : 52|3@0+ (1,0) [0|7] ""  VCU,GWM
 SG_ ACU_TrafficSeg17 : 55|3@0+ (1,0) [0|7] ""  VCU,GWM
 SG_ ACU_TrafficSeg16 : 42|3@0+ (1,0) [0|7] ""  VCU,GWM
 SG_ ACU_TrafficSeg15 : 45|3@0+ (1,0) [0|7] ""  VCU,GWM
 SG_ ACU_TrafficSeg14 : 32|3@0+ (1,0) [0|7] ""  VCU,GWM
 SG_ ACU_TrafficSeg13 : 35|3@0+ (1,0) [0|7] ""  VCU,GWM
 SG_ ACU_TrafficSeg12 : 38|3@0+ (1,0) [0|7] ""  VCU,GWM
 SG_ ACU_TrafficSeg11 : 25|3@0+ (1,0) [0|7] ""  VCU,GWM
 SG_ ACU_TrafficSeg10 : 28|3@0+ (1,0) [0|7] ""  VCU,GWM
 SG_ ACU_TrafficSeg9 : 31|3@0+ (1,0) [0|7] ""  VCU,GWM
 SG_ ACU_TrafficSeg8 : 18|3@0+ (1,0) [0|7] ""  VCU,GWM
 SG_ ACU_TrafficSeg7 : 21|3@0+ (1,0) [0|7] ""  VCU,GWM
 SG_ ACU_TrafficSeg6 : 8|3@0+ (1,0) [0|7] ""  VCU,GWM
 SG_ ACU_TrafficSeg5 : 11|3@0+ (1,0) [0|7] ""  VCU,GWM
 SG_ ACU_TrafficSeg4 : 14|3@0+ (1,0) [0|7] ""  VCU,GWM
 SG_ ACU_TrafficSeg3 : 1|3@0+ (1,0) [0|7] ""  VCU,GWM
 SG_ ACU_TrafficSeg2 : 4|3@0+ (1,0) [0|7] ""  VCU,GWM
 SG_ ACU_TrafficSeg1 : 7|3@0+ (1,0) [0|7] ""  VCU,GWM

BO_ 863 GW_TEL_3_B: 8 GWM
 SG_ TEL_TelematicsRegisterSt : 26|3@0+ (1,0) [0|7] ""  IHU
 SG_ TEL_BTManualMode : 23|2@0+ (1,0) [0|3] ""  IHU
 SG_ TEL_BTAvrcpSt : 19|1@0+ (1,0) [0|1] ""  IHU
 SG_ TEL_BTAvrcpPlayMode : 18|3@0+ (1,0) [0|7] ""  IHU
 SG_ TEL_BTHandfreeSt : 15|1@0+ (1,0) [0|1] ""  IHU
 SG_ TEL_BTHisdel : 14|1@0+ (1,0) [0|1] ""  IHU
 SG_ TEL_BTAutoconectingSt : 13|1@0+ (1,0) [0|1] ""  IHU
 SG_ TEL_BTPowerSt : 12|1@0+ (1,0) [0|1] ""  IHU
 SG_ TEL_TelematicsModeActSt : 6|3@0+ (1,0) [0|7] ""  IHU

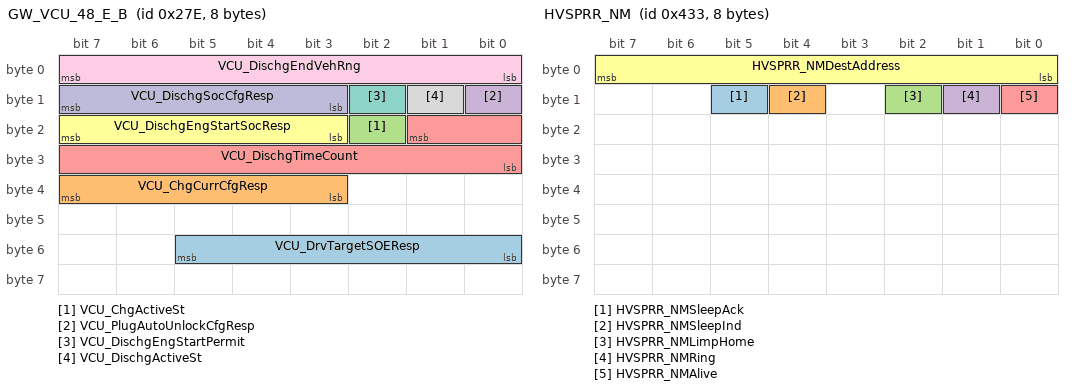
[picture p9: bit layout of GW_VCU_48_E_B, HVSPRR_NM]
BO_ 638 GW_VCU_48_E_B: 8 GWM
 SG_ VCU_DrvTargetSOEResp : 53|6@0+ (1,0) [0|63] ""  IHU,ACU
 SG_ VCU_ChgCurrCfgResp : 39|5@0+ (2,0) [0|32] "A"  IHU,GWM
 SG_ VCU_ChgActiveSt : 18|1@0+ (1,0) [0|1] ""  IHU,GWM
 SG_ VCU_PlugAutoUnlockCfgResp : 8|1@0+ (1,0) [0|1] ""  IHU,GWM
 SG_ VCU_DischgTimeCount : 17|10@0+ (1,0) [0|720] "min"  IHU,GWM
 SG_ VCU_DischgEngStartSocResp : 23|5@0+ (5,0) [0|100] "%"  IHU,GWM
 SG_ VCU_DischgEngStartPermit : 10|1@0+ (1,0) [0|1] ""  IHU,GWM
 SG_ VCU_DischgActiveSt : 9|1@0+ (1,0) [0|1] ""  IHU,GWM
 SG_ VCU_DischgEndVehRng : 7|8@0+ (1,0) [0|200] "km"  IHU,GWM
 SG_ VCU_DischgSocCfgResp : 15|5@0+ (5,0) [0|100] "%"  IHU,GWM

BO_ 1075 HVSPRR_NM: 8 HVSPRR
 SG_ HVSPRR_NMSleepAck : 13|1@0+ (1,0) [0|1] ""  Tester,PSDR,PSDL,AMP,HUD,PLGM,TSCM,IBCM,HVACF,IAL,RCP,FCP,HVSM,IHU,SBM,ETC
 SG_ HVSPRR_NMSleepInd : 12|1@0+ (1,0) [0|1] ""  Tester,PSDR,PSDL,AMP,HUD,PLGM,TSCM,IBCM,HVACF,IAL,RCP,FCP,HVSM,IHU,SBM,ETC
 SG_ HVSPRR_NMLimpHome : 10|1@0+ (1,0) [0|1] ""  Tester,PSDR,PSDL,AMP,HUD,PLGM,TSCM,IBCM,HVACF,IAL,RCP,FCP,HVSM,IHU,SBM,ETC
 SG_ HVSPRR_NMRing : 9|1@0+ (1,0) [0|1] ""  Tester,PSDR,PSDL,AMP,HUD,PLGM,TSCM,IBCM,HVACF,IAL,RCP,FCP,HVSM,IHU,SBM,ETC
 SG_ HVSPRR_NMAlive : 8|1@0+ (1,0) [0|1] ""  Tester,PSDR,PSDL,AMP,HUD,PLGM,TSCM,IBCM,HVACF,IAL,RCP,FCP,HVSM,IHU,SBM,ETC
 SG_ HVSPRR_NMDestAddress : 7|8@0+ (1,0) [0|255] ""  Tester,PSDR,PSDL,AMP,HUD,PLGM,TSCM,IBCM,HVACF,IAL,RCP,FCP,HVSM,IHU,SBM,ETC

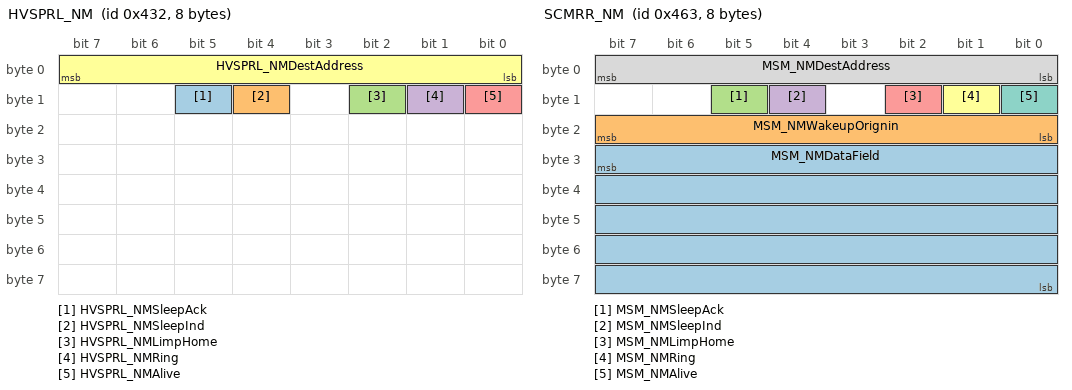
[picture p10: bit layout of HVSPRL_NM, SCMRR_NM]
BO_ 1074 HVSPRL_NM: 8 HVSPRL
 SG_ HVSPRL_NMSleepAck : 13|1@0+ (1,0) [0|1] ""  Tester,PSDR,PSDL,AMP,HUD,PLGM,TSCM,IBCM,HVACF,IAL,RCP,FCP,HVSM,IHU,SBM,ETC
 SG_ HVSPRL_NMSleepInd : 12|1@0+ (1,0) [0|1] ""  Tester,PSDR,PSDL,AMP,HUD,PLGM,TSCM,IBCM,HVACF,IAL,RCP,FCP,HVSM,IHU,SBM,ETC
 SG_ HVSPRL_NMLimpHome : 10|1@0+ (1,0) [0|1] ""  Tester,PSDR,PSDL,AMP,HUD,PLGM,TSCM,IBCM,HVACF,IAL,RCP,FCP,HVSM,IHU,SBM,ETC
 SG_ HVSPRL_NMRing : 9|1@0+ (1,0) [0|1] ""  Tester,PSDR,PSDL,AMP,HUD,PLGM,TSCM,IBCM,HVACF,IAL,RCP,FCP,HVSM,IHU,SBM,ETC
 SG_ HVSPRL_NMAlive : 8|1@0+ (1,0) [0|1] ""  Tester,PSDR,PSDL,AMP,HUD,PLGM,TSCM,IBCM,HVACF,IAL,RCP,FCP,HVSM,IHU,SBM,ETC
 SG_ HVSPRL_NMDestAddress : 7|8@0+ (1,0) [0|255] ""  Tester,PSDR,PSDL,AMP,HUD,PLGM,TSCM,IBCM,HVACF,IAL,RCP,FCP,HVSM,IHU,SBM,ETC

BO_ 558 HVSPRR_1: 8 HVSPRR
 SG_ HVSPRR_RR_Freezepemissions_FuncC : 33|2@0+ (1,0) [0|3] ""  SCMRR,IBCM,IHU
 SG_ HVSPRR_RRSPABUttonSt : 23|2@0+ (1,0) [0|1] ""  SCMRR,IBCM,IHU

BO_ 557 HVSPRL_1: 8 HVSPRL
 SG_ HVSPRL_RL_Freezepemissions_FuncC : 33|2@0+ (1,0) [0|3] ""  SCMRL,IBCM,IHU
 SG_ HVSPRL_RLSPABUttonSt : 23|2@0+ (1,0) [0|1] ""  SCMRL,IBCM,IHU

BO_ 1123 SCMRR_NM: 8 SCMRR
 SG_ MSM_NMDataField : 31|40@0+ (1,0) [0|0] ""  Tester,PSDR,PSDL,AMP,LCU,HUD,PLGM,FLDCM,FRDCM,SCM,TSCM,IBCM,HVACF,IAL,FCP,HVSM,IHU,SBM,WCM,ETC
 SG_ MSM_NMWakeupOrignin : 23|8@0+ (1,0) [0|255] ""  Tester,PSDR,PSDL,AMP,LCU,HUD,PLGM,FLDCM,FRDCM,SCM,TSCM,IBCM,HVACF,IAL,FCP,HVSM,IHU,SBM,WCM,ETC
 SG_ MSM_NMSleepAck : 13|1@0+ (1,0) [0|1] ""  Tester,PSDR,PSDL,AMP,LCU,HUD,PLGM,FLDCM,FRDCM,SCM,TSCM,IBCM,HVACF,IAL,FCP,HVSM,IHU,SBM,WCM,ETC
 SG_ MSM_NMSleepInd : 12|1@0+ (1,0) [0|1] ""  Tester,PSDR,PSDL,AMP,LCU,HUD,PLGM,FLDCM,FRDCM,SCM,TSCM,IBCM,HVACF,IAL,FCP,HVSM,IHU,SBM,WCM,ETC
 SG_ MSM_NMLimpHome : 10|1@0+ (1,0) [0|1] ""  Tester,PSDR,PSDL,AMP,LCU,HUD,PLGM,FLDCM,FRDCM,SCM,TSCM,IBCM,HVACF,IAL,FCP,HVSM,IHU,SBM,WCM,ETC
 SG_ MSM_NMRing : 9|1@0+ (1,0) [0|1] ""  Tester,PSDR,PSDL,AMP,LCU,HUD,PLGM,FLDCM,FRDCM,SCM,TSCM,IBCM,HVACF,IAL,FCP,HVSM,IHU,SBM,WCM,ETC
 SG_ MSM_NMAlive : 8|1@0+ (1,0) [0|1] ""  Tester,PSDR,PSDL,AMP,LCU,HUD,PLGM,FLDCM,FRDCM,SCM,TSCM,IBCM,HVACF,IAL,FCP,HVSM,IHU,SBM,WCM,ETC
 SG_ MSM_NMDestAddress : 7|8@0+ (1,0) [0|255] ""  Tester,PSDR,PSDL,AMP,LCU,HUD,PLGM,FLDCM,FRDCM,SCM,TSCM,IBCM,HVACF,IAL,FCP,HVSM,IHU,SBM,WCM,ETC

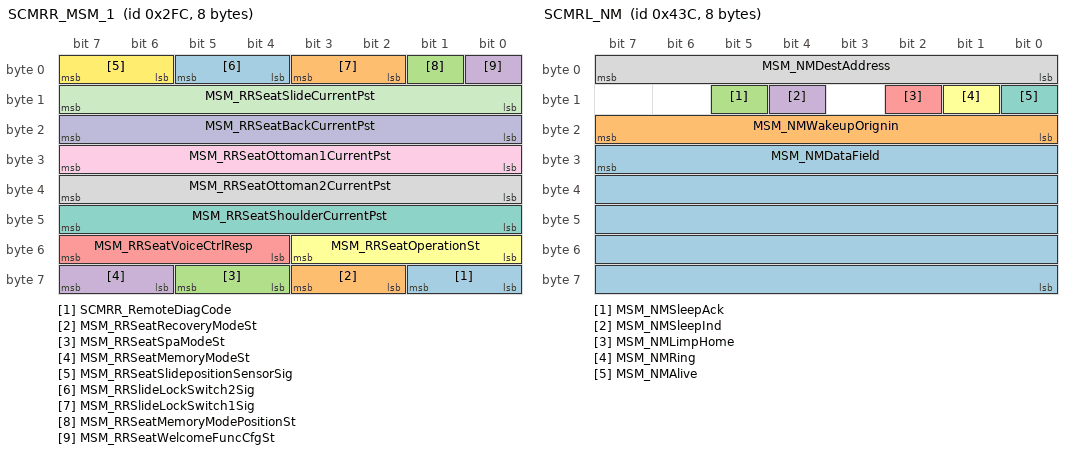
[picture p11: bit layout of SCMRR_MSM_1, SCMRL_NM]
BO_ 764 SCMRR_MSM_1: 8 SCMRR
 SG_ SCMRR_RemoteDiagCode : 57|2@0+ (1,0) [0|3] ""  IHU
 SG_ MSM_RRSeatRecoveryModeSt : 59|2@0+ (1,0) [0|3] ""  HVSPRR,IHU
 SG_ MSM_RRSeatSpaModeSt : 61|2@0+ (1,0) [0|3] ""  IHU
 SG_ MSM_RRSeatMemoryModeSt : 63|2@0+ (1,0) [0|3] ""  HVSPRR,IHU
 SG_ MSM_RRSeatVoiceCtrlResp : 55|4@0+ (1,0) [0|15] ""  IHU
 SG_ MSM_RRSeatOperationSt : 51|4@0+ (1,0) [0|15] ""  IHU
 SG_ MSM_RRSeatShoulderCurrentPst : 47|8@0+ (1,0) [0|0] "%"  IHU
 SG_ MSM_RRSeatOttoman2CurrentPst : 39|8@0+ (1,0) [0|0] "%"  IHU
 SG_ MSM_RRSeatOttoman1CurrentPst : 31|8@0+ (1,0) [0|0] "%"  IHU
 SG_ MSM_RRSeatBackCurrentPst : 23|8@0+ (1,0) [0|0] "%"  IHU
 SG_ MSM_RRSeatSlideCurrentPst : 15|8@0+ (1,0) [0|0] "%"  IHU
 SG_ MSM_RRSeatSlidepositionSensorSig : 7|2@0+ (1,0) [0|3] ""  IHU
 SG_ MSM_RRSlideLockSwitch2Sig : 5|2@0+ (1,0) [0|3] ""  IHU
 SG_ MSM_RRSlideLockSwitch1Sig : 3|2@0+ (1,0) [0|3] ""  IHU
 SG_ MSM_RRSeatMemoryModePositionSt : 1|1@0+ (1,0) [0|1] ""  HVSPRR,IHU
 SG_ MSM_RRSeatWelcomeFuncCfgSt : 0|1@0+ (1,0) [0|1] ""  IHU

BO_ 1084 SCMRL_NM: 8 SCMRL
 SG_ MSM_NMDataField : 31|40@0+ (1,0) [0|0] ""  Tester,PSDR,PSDL,AMP,LCU,HUD,PLGM,FLDCM,FRDCM,SCM,TSCM,IBCM,HVACF,IAL,FCP,HVSM,IHU,SBM,WCM,ETC
 SG_ MSM_NMWakeupOrignin : 23|8@0+ (1,0) [0|255] ""  Tester,PSDR,PSDL,AMP,LCU,HUD,PLGM,FLDCM,FRDCM,SCM,TSCM,IBCM,HVACF,IAL,FCP,HVSM,IHU,SBM,WCM,ETC
 SG_ MSM_NMSleepAck : 13|1@0+ (1,0) [0|1] ""  Tester,PSDR,PSDL,AMP,LCU,HUD,PLGM,FLDCM,FRDCM,SCM,TSCM,IBCM,HVACF,IAL,FCP,HVSM,IHU,SBM,WCM,ETC
 SG_ MSM_NMSleepInd : 12|1@0+ (1,0) [0|1] ""  Tester,PSDR,PSDL,AMP,LCU,HUD,PLGM,FLDCM,FRDCM,SCM,TSCM,IBCM,HVACF,IAL,FCP,HVSM,IHU,SBM,WCM,ETC
 SG_ MSM_NMLimpHome : 10|1@0+ (1,0) [0|1] ""  Tester,PSDR,PSDL,AMP,LCU,HUD,PLGM,FLDCM,FRDCM,SCM,TSCM,IBCM,HVACF,IAL,FCP,HVSM,IHU,SBM,WCM,ETC
 SG_ MSM_NMRing : 9|1@0+ (1,0) [0|1] ""  Tester,PSDR,PSDL,AMP,LCU,HUD,PLGM,FLDCM,FRDCM,SCM,TSCM,IBCM,HVACF,IAL,FCP,HVSM,IHU,SBM,WCM,ETC
 SG_ MSM_NMAlive : 8|1@0+ (1,0) [0|1] ""  Tester,PSDR,PSDL,AMP,LCU,HUD,PLGM,FLDCM,FRDCM,SCM,TSCM,IBCM,HVACF,IAL,FCP,HVSM,IHU,SBM,WCM,ETC
 SG_ MSM_NMDestAddress : 7|8@0+ (1,0) [0|255] ""  Tester,PSDR,PSDL,AMP,LCU,HUD,PLGM,FLDCM,FRDCM,SCM,TSCM,IBCM,HVACF,IAL,FCP,HVSM,IHU,SBM,WCM,ETC

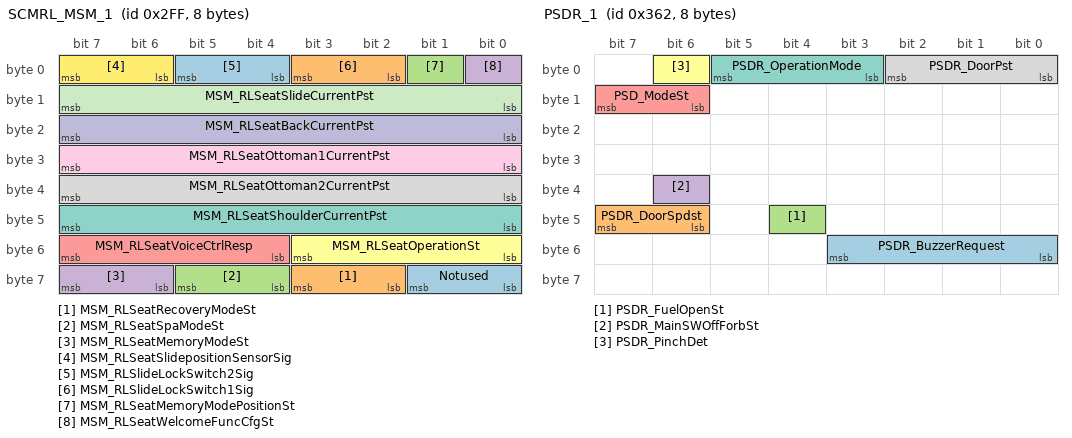
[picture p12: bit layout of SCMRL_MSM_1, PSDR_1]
BO_ 767 SCMRL_MSM_1: 8 SCMRL
 SG_ Notused : 57|2@0+ (1,0) [0|0] ""  IHU
 SG_ MSM_RLSeatRecoveryModeSt : 59|2@0+ (1,0) [0|3] ""  HVSPRL,IHU
 SG_ MSM_RLSeatSpaModeSt : 61|2@0+ (1,0) [0|3] ""  IHU
 SG_ MSM_RLSeatMemoryModeSt : 63|2@0+ (1,0) [0|3] ""  HVSPRL,IHU
 SG_ MSM_RLSeatVoiceCtrlResp : 55|4@0+ (1,0) [0|15] ""  IHU
 SG_ MSM_RLSeatOperationSt : 51|4@0+ (1,0) [0|15] ""  IHU
 SG_ MSM_RLSeatShoulderCurrentPst : 47|8@0+ (1,0) [0|255] "%"  IHU
 SG_ MSM_RLSeatOttoman2CurrentPst : 39|8@0+ (1,0) [0|255] "%"  IHU
 SG_ MSM_RLSeatOttoman1CurrentPst : 31|8@0+ (1,0) [0|255] "%"  IHU
 SG_ MSM_RLSeatBackCurrentPst : 23|8@0+ (1,0) [0|255] "%"  IHU
 SG_ MSM_RLSeatSlideCurrentPst : 15|8@0+ (1,0) [0|255] "%"  IHU
 SG_ MSM_RLSeatSlidepositionSensorSig : 7|2@0+ (1,0) [0|3] ""  IHU
 SG_ MSM_RLSlideLockSwitch2Sig : 5|2@0+ (1,0) [0|3] ""  IHU
 SG_ MSM_RLSlideLockSwitch1Sig : 3|2@0+ (1,0) [0|3] ""  IHU
 SG_ MSM_RLSeatMemoryModePositionSt : 1|1@0+ (1,0) [0|1] ""  HVSPRL,IHU
 SG_ MSM_RLSeatWelcomeFuncCfgSt : 0|1@0+ (1,0) [0|1] ""  IHU

BO_ 866 PSDR_1: 8 PSDR
 SG_ PSDR_BuzzerRequest : 51|4@0+ (1,0) [0|15] ""  IHU
 SG_ PSDR_DoorSpdst : 47|2@0+ (1,0) [0|3] ""  IHU
 SG_ PSDR_FuelOpenSt : 44|1@0+ (1,0) [0|1] ""  IHU
 SG_ PSDR_MainSWOffForbSt : 38|1@0+ (1,0) [0|1] ""  IHU
 SG_ PSD_ModeSt : 15|2@0+ (1,0) [0|3] ""  IHU
 SG_ PSDR_PinchDet : 6|1@0+ (1,0) [0|1] ""  IHU
 SG_ PSDR_OperationMode : 5|3@0+ (1,0) [0|7] ""  IHU
 SG_ PSDR_DoorPst : 2|3@0+ (1,0) [0|7] ""  IHU

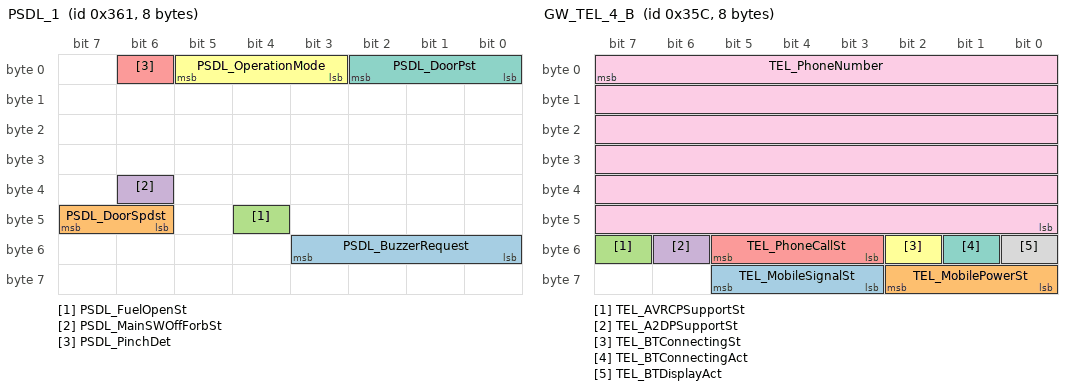
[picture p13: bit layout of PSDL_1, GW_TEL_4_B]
BO_ 865 PSDL_1: 8 PSDL
 SG_ PSDL_BuzzerRequest : 51|4@0+ (1,0) [0|15] ""  IHU
 SG_ PSDL_DoorSpdst : 47|2@0+ (1,0) [0|3] ""  IHU
 SG_ PSDL_FuelOpenSt : 44|1@0+ (1,0) [0|1] ""  IHU
 SG_ PSDL_MainSWOffForbSt : 38|1@0+ (1,0) [0|1] ""  IHU
 SG_ PSDL_PinchDet : 6|1@0+ (1,0) [0|1] ""  IHU
 SG_ PSDL_OperationMode : 5|3@0+ (1,0) [0|7] ""  IHU
 SG_ PSDL_DoorPst : 2|3@0+ (1,0) [0|7] ""  IHU

BO_ 1003 AVAS_2: 8 AVAS
 SG_ AVAS_ActivatedSt : 6|1@0+ (1,0) [0|1] ""  IHU

BO_ 118 GW_TEL_10_B: 8 GWM
 SG_ TEL_ModuleResetSt : 9|2@0+ (1,0) [0|3] ""  IHU
 SG_ TEL_ResetFailReason : 7|8@0+ (1,0) [0|255] ""  IHU

BO_ 860 GW_TEL_4_B: 8 GWM
 SG_ TEL_MobileSignalSt : 61|3@0+ (1,0) [0|7] ""  IHU
 SG_ TEL_MobilePowerSt : 58|3@0+ (1,0) [0|7] ""  IHU
 SG_ TEL_AVRCPSupportSt : 55|1@0+ (1,0) [0|1] ""  IHU
 SG_ TEL_A2DPSupportSt : 54|1@0+ (1,0) [0|1] ""  IHU
 SG_ TEL_PhoneCallSt : 53|3@0+ (1,0) [0|7] ""  IHU
 SG_ TEL_BTConnectingSt : 50|1@0+ (1,0) [0|1] ""  IHU
 SG_ TEL_BTConnectingAct : 49|1@0+ (1,0) [0|1] ""  IHU
 SG_ TEL_BTDisplayAct : 48|1@0+ (1,0) [0|1] ""  IHU
 SG_ TEL_PhoneNumber : 7|48@0+ (1,0) [0|0] ""  IHU

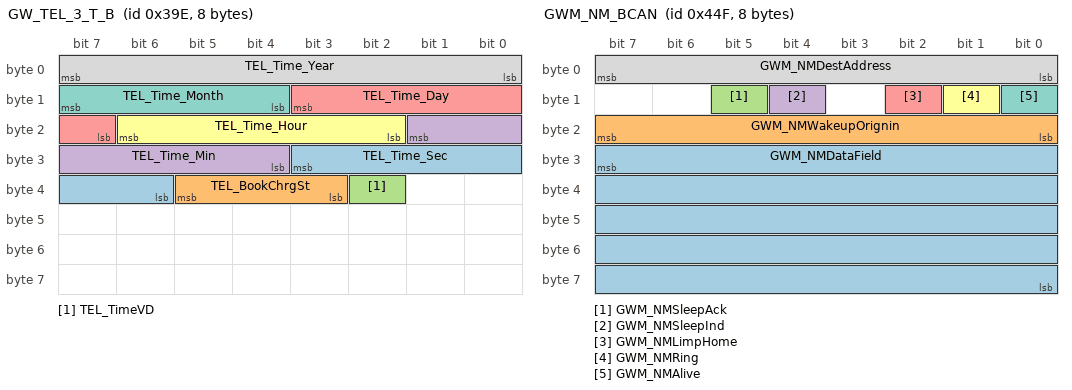
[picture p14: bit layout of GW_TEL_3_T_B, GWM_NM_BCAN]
BO_ 926 GW_TEL_3_T_B: 8 GWM
 SG_ TEL_Time_Sec : 27|6@0+ (1,0) [0|59] "s"  IHU
 SG_ TEL_BookChrgSt : 37|3@0+ (1,0) [0|7] "-"  IHU
 SG_ TEL_TimeVD : 34|1@0+ (1,0) [0|1] ""  IHU
 SG_ TEL_Time_Min : 17|6@0+ (1,0) [0|59] "min"  IHU
 SG_ TEL_Time_Day : 11|5@0+ (1,0) [1|31] "d"  IHU
 SG_ TEL_Time_Hour : 22|5@0+ (1,0) [0|23] "h"  IHU
 SG_ TEL_Time_Month : 15|4@0+ (1,0) [1|12] "m"  IHU
 SG_ TEL_Time_Year : 7|8@0+ (1,2000) [2000|2255] "y"  IHU

BO_ 160 GW_TEL_1_A_B: 8 GWM
 SG_ TEL_PCS_EventRecordCtrlReq : 3|2@0+ (1,0) [0|3] ""  IHU
 SG_ TEL_PCS_CtrlReq : 1|2@0+ (1,0) [0|3] ""  IHU

BO_ 1103 GWM_NM_BCAN: 8 GWM
 SG_ GWM_NMDataField : 31|40@0+ (1,0) [0|0] ""  PSDR,PSDL,AMP,LCU,HUD,PLGM,FLDCM,FRDCM,SCM,TSCM,IBCM,HVACF,IAL,RCP,FCP,HVSM,IHU,SBM,WCM,ETC,GWM
 SG_ GWM_NMWakeupOrignin : 23|8@0+ (1,0) [0|255] ""  PSDR,PSDL,AMP,LCU,HUD,PLGM,FLDCM,FRDCM,SCM,TSCM,IBCM,HVACF,IAL,RCP,FCP,HVSM,IHU,SBM,WCM,ETC,GWM
 SG_ GWM_NMSleepAck : 13|1@0+ (1,0) [0|1] ""  PSDR,PSDL,AMP,LCU,HUD,PLGM,FLDCM,FRDCM,SCM,TSCM,IBCM,HVACF,IAL,RCP,FCP,HVSM,IHU,SBM,WCM,ETC,GWM
 SG_ GWM_NMSleepInd : 12|1@0+ (1,0) [0|1] ""  PSDR,PSDL,AMP,LCU,HUD,PLGM,FLDCM,FRDCM,SCM,TSCM,IBCM,HVACF,IAL,RCP,FCP,HVSM,IHU,SBM,WCM,ETC,GWM
 SG_ GWM_NMLimpHome : 10|1@0+ (1,0) [0|1] ""  PSDR,PSDL,AMP,LCU,HUD,PLGM,FLDCM,FRDCM,SCM,TSCM,IBCM,HVACF,IAL,RCP,FCP,HVSM,IHU,SBM,WCM,ETC,GWM
 SG_ GWM_NMRing : 9|1@0+ (1,0) [0|1] ""  PSDR,PSDL,AMP,LCU,HUD,PLGM,FLDCM,FRDCM,SCM,TSCM,IBCM,HVACF,IAL,RCP,FCP,HVSM,IHU,SBM,WCM,ETC,GWM
 SG_ GWM_NMAlive : 8|1@0+ (1,0) [0|1] ""  PSDR,PSDL,AMP,LCU,HUD,PLGM,FLDCM,FRDCM,SCM,TSCM,IBCM,HVACF,IAL,RCP,FCP,HVSM,IHU,SBM,WCM,ETC,GWM
 SG_ GWM_NMDestAddress : 7|8@0+ (1,0) [0|255] ""  PSDR,PSDL,AMP,LCU,HUD,PLGM,FLDCM,FRDCM,SCM,TSCM,IBCM,HVACF,IAL,RCP,FCP,HVSM,IHU,SBM,WCM,ETC,GWM

BO_ 802 GW_3_B: 8 GWM
 SG_ GW_VehicleModeBroadcast : 13|4@0+ (1,0) [0|15] ""  IHU

BO_ 968 GW_1_B: 8 GWM
 SG_ GW_TransportationMode : 63|1@0+ (1,0) [0|1] ""  IBCM,IHU
 SG_ GW_LowBatPreWarning : 7|3@0+ (1,0) [0|7] ""  IBCM,HVACF,IHU

BO_ 854 GW_GSM_1_B: 4 GWM
 SG_ GSM_WarnInfo : 15|4@0+ (1,0) [0|15] ""  IHU
 SG_ GSM_GearShiftLeverPstReq : 11|4@0+ (1,0) [0|15] ""  HUD,IBCM,IHU,PAS,FAPA
 SG_ GSM_DriveModeRespFail : 3|4@0+ (1,0) [0|15] ""  IHU

BO_ 786 GW_IFC_MRR_1_B: 8 GWM
 SG_ ADAS_AcceComfUpperValue : 63|8@0+ (0.05,-7) [-7|5.75] "m/s2"  IHU,PAS
 SG_ MRR_PEBSObjType : 55|4@0+ (1,0) [0|15] ""  IHU,PAS
 SG_ MRR_ACCQuitSound : 46|1@0+ (1,0) [0|1] ""  IHU,PAS
 SG_ MRR_ISLACC_St : 45|1@0+ (1,0) [0|1] ""  IHU,PAS
 SG_ MRR_FCWWarnDistance : 44|2@0+ (1,0) [0|3] ""  IHU
 SG_ MRR_AEBInterventionSt : 42|1@0+ (1,0) [0|1] ""  IHU,PAS
 SG_ MRR_AEBOffSt : 41|1@0+ (1,0) [0|1] ""  IHU,PAS
 SG_ MRR_AEBFaultSt : 40|1@0+ (1,0) [0|1] ""  IHU,PAS
 SG_ MRR_AEB_PEDPFaultSt : 39|1@0+ (1,0) [0|1] ""  IHU
 SG_ MRR_FCWLatentWarn : 38|2@0+ (1,0) [0|3] ""  HUD,IHU
 SG_ MRR_FCWPreWarn : 36|2@0+ (1,0) [0|3] ""  HUD,IHU
 SG_ MRR_FCWInterventionSt : 34|1@0+ (1,0) [0|1] ""  IHU,PAS
 SG_ MRR_FCWFaultSt : 33|1@0+ (1,0) [0|1] ""  HUD,IHU,PAS
 SG_ MRR_FCWOffSt : 32|1@0+ (1,0) [0|1] ""  HUD,IHU,PAS
 SG_ MRR_TargetSpd : 16|9@0+ (0.5,0) [0|255.5] "km/h"  HUD,IHU,PAS
 SG_ MRR_TauGapSet : 22|3@0+ (1,0) [0|7] ""  HUD,IHU,PAS
 SG_ MRR_TargetDistanceSt : 19|3@0+ (1,0) [0|7] ""  IHU,PAS
 SG_ MRR_ObjectCapturedSt : 15|1@0+ (1,0) [0|1] ""  HUD,IHU,PAS
 SG_ MRR_ACCTakeOverReq : 14|1@0+ (1,0) [0|1] ""  HUD,IHU,PAS
 SG_ MRR_ACCFuncCancel : 13|2@0+ (1,0) [0|3] ""  IHU,PAS
 SG_ MRR_ACCGoNotifier : 11|1@0+ (1,0) [0|1] ""  IHU,PAS
 SG_ MRR_ACCActiveSt : 10|1@0+ (1,0) [0|1] ""  IHU,PAS
 SG_ MRR_ACCFaultSt : 9|2@0+ (1,0) [0|3] ""  IHU,PAS
 SG_ MRR_ACCTextInfo : 7|5@0+ (1,0) [0|31] ""  HUD,IHU,PAS
 SG_ MRR_ACCMode : 2|3@0+ (1,0) [0|7] ""  HUD,IHU,PAS

BO_ 861 GW_TMM_1_B: 8 GWM
 SG_ TMM_ThermalWarning : 16|1@0+ (1,0) [0|1] ""  IHU
 SG_ TMM_CouplingThermalFailSafe : 5|1@0+ (1,0) [0|1] ""  IHU
 SG_ TMM_DiagnosticLampReq : 4|1@0+ (1,0) [0|1] ""  IHU
 SG_ TMM_SysOperatingMode : 3|4@0+ (1,0) [0|15] ""  IHU

BO_ 840 GW_EPS_1_B: 2 GWM
 SG_ EPS_FunctionStyleSt : 2|2@0+ (1,0) [0|3] ""  IHU
 SG_ EPS_WarnLamp : 0|1@0+ (1,0) [0|1] ""  IHU

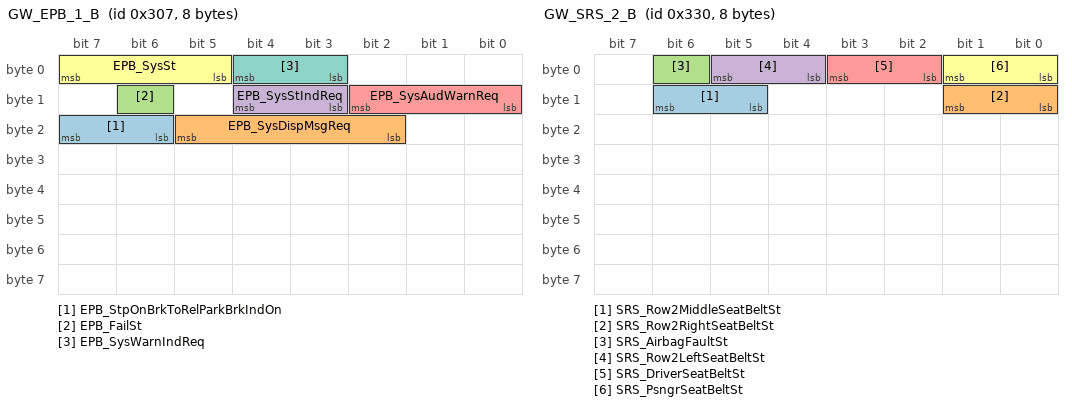
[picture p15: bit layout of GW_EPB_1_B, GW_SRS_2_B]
BO_ 775 GW_EPB_1_B: 8 GWM
 SG_ EPB_StpOnBrkToRelParkBrkIndOn : 23|2@0+ (1,0) [0|2] "-"  IHU
 SG_ EPB_SysDispMsgReq : 21|4@0+ (1,0) [0|15] ""  IHU
 SG_ EPB_FailSt : 14|1@0+ (1,0) [0|1] ""  IHU
 SG_ EPB_SysStIndReq : 12|2@0+ (1,0) [0|3] ""  IHU,SBM
 SG_ EPB_SysAudWarnReq : 10|3@0+ (1,0) [0|7] ""  IHU,PAS,FAPA
 SG_ EPB_SysSt : 7|3@0+ (1,0) [0|2] ""  IHU,SBM
 SG_ EPB_SysWarnIndReq : 4|2@0+ (1,0) [0|3] ""  IHU

BO_ 816 GW_SRS_2_B: 8 GWM
 SG_ SRS_Row2MiddleSeatBeltSt : 14|2@0+ (1,0) [0|3] ""  IHU
 SG_ SRS_Row2RightSeatBeltSt : 9|2@0+ (1,0) [0|3] ""  IHU
 SG_ SRS_AirbagFaultSt : 6|1@0+ (1,0) [0|1] ""  IHU
 SG_ SRS_Row2LeftSeatBeltSt : 5|2@0+ (1,0) [0|3] ""  IHU
 SG_ SRS_DriverSeatBeltSt : 3|2@0+ (1,0) [0|3] ""  IHU,PAS,FAPA
 SG_ SRS_PsngrSeatBeltSt : 1|2@0+ (1,0) [0|3] ""  IHU

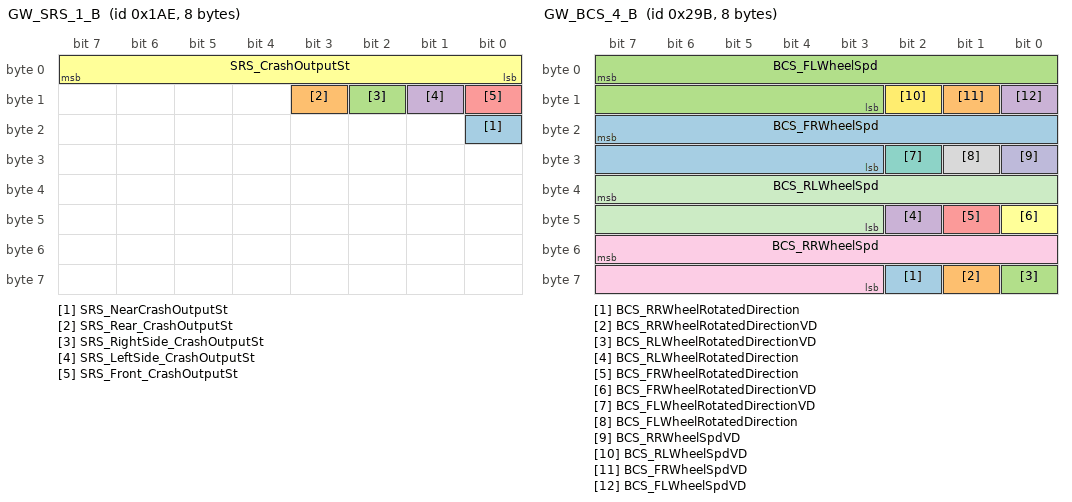
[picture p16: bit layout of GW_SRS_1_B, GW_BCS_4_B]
BO_ 430 GW_SRS_1_B: 8 GWM
 SG_ SRS_NearCrashOutputSt : 16|1@0+ (1,0) [0|1] ""  IHU
 SG_ SRS_Rear_CrashOutputSt : 11|1@0+ (1,0) [0|1] ""  IHU
 SG_ SRS_RightSide_CrashOutputSt : 10|1@0+ (1,0) [0|1] ""  IHU
 SG_ SRS_LeftSide_CrashOutputSt : 9|1@0+ (1,0) [0|1] ""  IHU
 SG_ SRS_Front_CrashOutputSt : 8|1@0+ (1,0) [0|1] ""  IHU
 SG_ SRS_CrashOutputSt : 7|8@0+ (1,0) [0|160] ""  SCMRR,SCMRL,FLDCM,FRDCM,SCM,IBCM,IHU

BO_ 829 GW_SAS_1_B: 8 GWM
 SG_ SAS_SteeringAngle : 31|16@0+ (0.1,-780) [-780|779.9] "deg"  LCU,HUD,IBCM,IAL,IHU,PAS,FAPA
 SG_ SAS_SteeringAngleSpd : 23|8@0+ (4,0) [0|1016] "deg/sec"  HUD,IHU
 SG_ SAS_TrimmingStatus : 10|1@0+ (1,0) [0|1] ""  IHU
 SG_ SAS_CalibratedSt : 9|1@0+ (1,0) [0|1] ""  IHU,PAS,FAPA
 SG_ SAS_SteeringAngleVD : 8|1@0+ (1,0) [0|1] ""  LCU,HUD,IBCM,IAL,IHU,PAS,FAPA

BO_ 667 GW_BCS_4_B: 8 GWM
 SG_ BCS_RRWheelRotatedDirection : 58|1@0+ (1,0) [0|1] ""  IHU
 SG_ BCS_RRWheelRotatedDirectionVD : 57|1@0+ (1,0) [0|1] ""  IHU
 SG_ BCS_RLWheelRotatedDirectionVD : 56|1@0+ (1,0) [0|1] ""  IHU
 SG_ BCS_RLWheelRotatedDirection : 42|1@0+ (1,0) [0|1] ""  IHU
 SG_ BCS_FRWheelRotatedDirection : 41|1@0+ (1,0) [0|1] ""  IHU
 SG_ BCS_FRWheelRotatedDirectionVD : 40|1@0+ (1,0) [0|1] ""  IHU
 SG_ BCS_FLWheelRotatedDirectionVD : 26|1@0+ (1,0) [0|1] ""  IHU
 SG_ BCS_FLWheelRotatedDirection : 25|1@0+ (1,0) [0|1] ""  IHU
 SG_ BCS_RRWheelSpd : 55|13@0+ (0.05625,0) [0|240] "km/h"  IHU
 SG_ BCS_RRWheelSpdVD : 24|1@0+ (1,0) [0|1] ""  IHU
 SG_ BCS_RLWheelSpd : 39|13@0+ (0.05625,0) [0|240] "km/h"  IHU
 SG_ BCS_RLWheelSpdVD : 10|1@0+ (1,0) [0|1] ""  IHU
 SG_ BCS_FRWheelSpd : 23|13@0+ (0.05625,0) [0|240] "km/h"  IHU
 SG_ BCS_FRWheelSpdVD : 9|1@0+ (1,0) [0|1] ""  IHU
 SG_ BCS_FLWheelSpd : 7|13@0+ (0.05625,0) [0|240] "km/h"  IHU
 SG_ BCS_FLWheelSpdVD : 8|1@0+ (1,0) [0|1] ""  IHU

BO_ 838 GW_BCS_3_B: 8 GWM
 SG_ BCS_HBBSt : 58|2@0+ (1,0) [0|3] ""  IHU
 SG_ BCS_CDDAvailable : 47|1@0+ (1,0) [0|1] ""  IHU
 SG_ BCS_CDDActive : 46|1@0+ (1,0) [0|1] ""  IHU
 SG_ BCS_AWBAvailable : 45|1@0+ (1,0) [0|1] ""  IHU
 SG_ BCS_AWBActive : 44|1@0+ (1,0) [0|1] ""  IHU
 SG_ BCS_AEBAvailable : 43|1@0+ (1,0) [0|1] ""  IHU
 SG_ BCS_AEBActive : 42|1@0+ (1,0) [0|1] ""  IHU
 SG_ BCS_ABPAvailable : 41|1@0+ (1,0) [0|1] ""  IHU
 SG_ BCS_ABPActive : 40|1@0+ (1,0) [0|1] ""  IHU
 SG_ BCS_AVHAvailable : 15|1@0+ (1,0) [0|1] ""  IHU
 SG_ BCS_AVHStandby : 14|1@0+ (1,0) [0|1] ""  IHU
 SG_ BCS_AVHSt : 13|1@0+ (1,0) [0|1] ""  IHU
 SG_ BCS_HDCErrSt : 11|1@0+ (1,0) [0|1] ""  IHU
 SG_ BCS_HHCErrSt : 10|1@0+ (1,0) [0|1] ""  IHU
 SG_ BCS_ABAavailable : 9|1@0+ (1,0) [0|1] ""  IHU
 SG_ BCS_ABAactive : 8|1@0+ (1,0) [0|1] ""  IHU
 SG_ BCS_HDCCtrlSt : 7|2@0+ (1,0) [0|3] ""  IHU
 SG_ BCS_VDCOff : 5|1@0+ (1,0) [0|1] ""  IHU
 SG_ BCS_TCSOff : 4|1@0+ (1,0) [0|1] ""  IHU
 SG_ BCS_BrakeOverHeat : 1|1@0+ (1,0) [0|1] ""  IHU

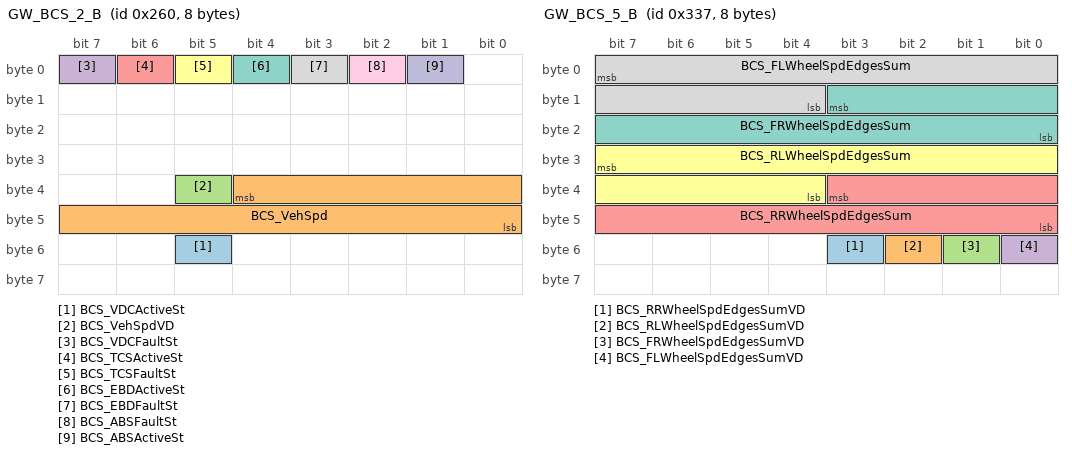
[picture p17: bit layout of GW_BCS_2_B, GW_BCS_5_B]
BO_ 608 GW_BCS_2_B: 8 GWM
 SG_ BCS_VDCActiveSt : 53|1@0+ (1,0) [0|1] ""  IHU,PAS,FAPA
 SG_ BCS_VehSpd : 36|13@0+ (0.05625,0) [0|240] "km/h"  PSDR,PSDL,AMP,LCU,HUD,PLGM,FLDCM,FRDCM,SCM,TSCM,IBCM,HVACF,IAL,FCP,IHU,SBM,ETC,PAS,FAPA
 SG_ BCS_VehSpdVD : 37|1@0+ (1,0) [0|1] ""  PSDR,PSDL,AMP,LCU,HUD,PLGM,FLDCM,FRDCM,SCM,TSCM,IBCM,HVACF,IAL,FCP,IHU,SBM,ETC,PAS,FAPA
 SG_ BCS_VDCFaultSt : 7|1@0+ (1,0) [0|1] ""  IHU,PAS,FAPA
 SG_ BCS_TCSActiveSt : 6|1@0+ (1,0) [0|1] ""  IHU,PAS,FAPA
 SG_ BCS_TCSFaultSt : 5|1@0+ (1,0) [0|1] ""  IHU,PAS,FAPA
 SG_ BCS_EBDActiveSt : 4|1@0+ (1,0) [0|1] ""  IHU,PAS,FAPA
 SG_ BCS_EBDFaultSt : 3|1@0+ (1,0) [0|1] ""  IHU,PAS,FAPA
 SG_ BCS_ABSFaultSt : 2|1@0+ (1,0) [0|1] ""  IHU,PAS,FAPA
 SG_ BCS_ABSActiveSt : 1|1@0+ (1,0) [0|1] ""  IHU,PAS,FAPA

BO_ 823 GW_BCS_5_B: 8 GWM
 SG_ BCS_RRWheelSpdEdgesSumVD : 51|1@0+ (1,0) [0|1] ""  HUD,IBCM,IHU,PAS,FAPA
 SG_ BCS_RLWheelSpdEdgesSumVD : 50|1@0+ (1,0) [0|1] ""  HUD,IBCM,IHU,PAS,FAPA
 SG_ BCS_FRWheelSpdEdgesSumVD : 49|1@0+ (1,0) [0|1] ""  HUD,IBCM,IHU,PAS,FAPA
 SG_ BCS_FLWheelSpdEdgesSumVD : 48|1@0+ (1,0) [0|1] ""  HUD,IBCM,IHU,PAS,FAPA
 SG_ BCS_RRWheelSpdEdgesSum : 35|12@0+ (1,0) [0|4095] ""  HUD,IBCM,IHU,PAS,FAPA
 SG_ BCS_RLWheelSpdEdgesSum : 31|12@0+ (1,0) [0|4095] ""  HUD,IBCM,IHU,PAS,FAPA
 SG_ BCS_FRWheelSpdEdgesSum : 11|12@0+ (1,0) [0|4095] ""  HUD,IBCM,IHU,PAS,FAPA
 SG_ BCS_FLWheelSpdEdgesSum : 7|12@0+ (1,0) [0|4095] ""  HUD,IBCM,IHU,PAS,FAPA

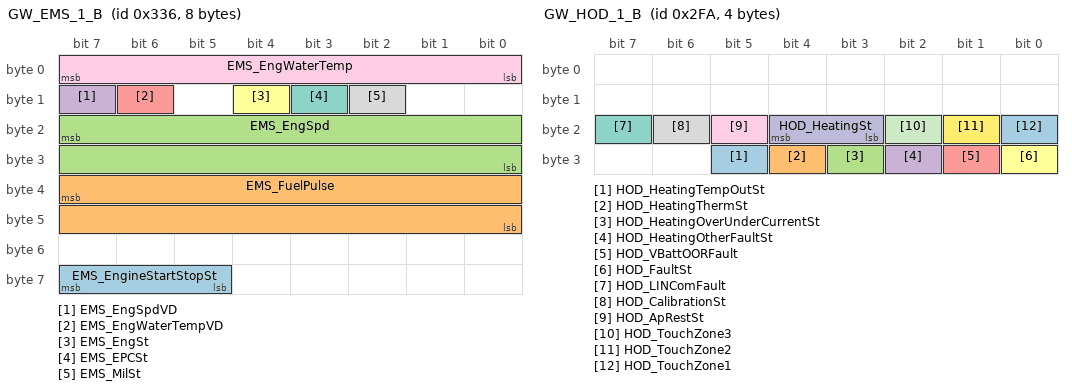
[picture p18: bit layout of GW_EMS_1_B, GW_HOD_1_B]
BO_ 822 GW_EMS_1_B: 8 GWM
 SG_ EMS_EngineStartStopSt : 63|3@0+ (1,0) [0|7] ""  IHU
 SG_ EMS_FuelPulse : 39|16@0+ (1,0) [0|65535] "μl"  IHU
 SG_ EMS_EngSpd : 23|16@0+ (1,0) [0|10240] "rpm"  IBCM,HVACF,IHU
 SG_ EMS_EngSpdVD : 15|1@0+ (1,0) [0|1] ""  IBCM,HVACF,IHU
 SG_ EMS_EngWaterTempVD : 14|1@0+ (1,0) [0|1] ""  HVACF,IHU
 SG_ EMS_EngSt : 12|1@0+ (1,0) [0|1] ""  LCU,IBCM,IHU,PAS,FAPA
 SG_ EMS_EPCSt : 11|1@0+ (1,0) [0|1] ""  IHU
 SG_ EMS_MilSt : 10|1@0+ (1,0) [0|1] ""  IHU
 SG_ EMS_EngWaterTemp : 7|8@0+ (1,-40) [-40|214] "°C"  HVACF,IHU

BO_ 785 GW_BSD_1_B: 8 GWM
 SG_ RRR_RCWWarnType : 4|2@0+ (1,0) [0|3] ""  IHU
 SG_ RLR_AudioWarnRL : 63|2@0+ (1,0) [0|3] ""  IHU
 SG_ RLR_AudioWarnFL : 61|2@0+ (1,0) [0|3] ""  IHU
 SG_ RRR_RCTAAssistType : 59|2@0+ (1,0) [0|3] ""  IHU
 SG_ RLR_RCTAWarnLeft : 55|2@0+ (1,0) [0|3] ""  IHU,FAPA
 SG_ RLR_LCAWarnLeft : 53|2@0+ (1,0) [0|3] ""  IHU
 SG_ RRR_AudioWarnRR : 51|2@0+ (1,0) [0|3] ""  IHU
 SG_ RRR_AudioWarnFR : 49|2@0+ (1,0) [0|3] ""  IHU
 SG_ RRR_RCWWarn : 47|2@0+ (1,0) [0|3] ""  IBCM,IHU
 SG_ RRR_RCWSt : 45|2@0+ (1,0) [0|3] ""  IHU
 SG_ RRR_RCTAWarnRight : 43|2@0+ (1,0) [0|3] ""  IHU,FAPA
 SG_ RRR_LCAWarnRight : 41|2@0+ (1,0) [0|3] ""  IHU
 SG_ RLR_VibrWarnL : 39|1@0+ (1,0) [0|1] ""  SCM,IHU
 SG_ RRR_LCASt : 38|2@0+ (1,0) [0|3] ""  FLDCM,FRDCM,IHU
 SG_ RRR_RCTASt : 36|2@0+ (1,0) [0|3] ""  IHU
 SG_ RRR_DOWSt : 34|2@0+ (1,0) [0|3] ""  IHU
 SG_ RLR_ExMirLedWarnL : 31|2@0+ (1,0) [0|3] ""  FLDCM,FRDCM,IBCM,IAL,IHU
 SG_ RLR_IALWarnRL : 29|2@0+ (1,0) [0|3] ""  IBCM,IAL,IHU
 SG_ RLR_IALWarnFL : 27|2@0+ (1,0) [0|3] ""  IBCM,IAL,IHU
 SG_ RRR_ExMirLedWarnR : 25|2@0+ (1,0) [0|3] ""  IBCM,IAL,IHU
 SG_ RRR_VibrWarnR : 23|1@0+ (1,0) [0|1] ""  SCM,IHU
 SG_ RRR_IALWarnRR : 22|2@0+ (1,0) [0|3] ""  IBCM,IAL,IHU
 SG_ RRR_IALWarnFR : 20|2@0+ (1,0) [0|3] ""  IBCM,IAL,IHU
 SG_ RRR_MRRSt : 18|3@0+ (1,0) [0|7] ""  IBCM,IAL,IHU
 SG_ RRR_ClusterLamp : 2|3@0+ (1,0) [0|7] ""  IHU

BO_ 439 GW_PCU_1_B: 8 GWM
 SG_ PCU_RejectHeatProtectINH_OH : 26|1@0+ (1,0) [0|1] "-"  IHU
 SG_ PCU_UnlockFault : 12|1@0+ (1,0) [0|1] ""  IHU
 SG_ PCU_LockFault : 11|1@0+ (1,0) [0|1] ""  IHU
 SG_ PCU_LampRequest : 3|1@0+ (1,0) [0|1] ""  IHU

BO_ 762 GW_HOD_1_B: 4 GWM
 SG_ HOD_HeatingTempOutSt : 29|1@0+ (1,0) [0|1] ""  IHU
 SG_ HOD_HeatingThermSt : 28|1@0+ (1,0) [0|1] ""  IHU
 SG_ HOD_HeatingOverUnderCurrentSt : 27|1@0+ (1,0) [0|1] ""  IHU
 SG_ HOD_HeatingOtherFaultSt : 26|1@0+ (1,0) [0|1] ""  IHU
 SG_ HOD_VBattOORFault : 25|1@0+ (1,0) [0|1] ""  IHU
 SG_ HOD_FaultSt : 24|1@0+ (1,0) [0|1] ""  IHU
 SG_ HOD_LINComFault : 23|1@0+ (1,0) [0|1] ""  IHU
 SG_ HOD_CalibrationSt : 22|1@0+ (1,0) [0|1] ""  IHU
 SG_ HOD_ApRestSt : 21|1@0+ (1,0) [0|1] ""  IHU
 SG_ HOD_HeatingSt : 20|2@0+ (1,0) [0|3] ""  IHU
 SG_ HOD_TouchZone3 : 18|1@0+ (1,0) [0|1] ""  IHU
 SG_ HOD_TouchZone2 : 17|1@0+ (1,0) [0|1] ""  IHU
 SG_ HOD_TouchZone1 : 16|1@0+ (1,0) [0|1] ""  IHU

BO_ 728 GW_CDC_1_B: 8 GWM
 SG_ CDC_ProhibitChangingMode : 4|1@0+ (1,0) [0|1] ""  IHU
 SG_ CDC_WarningLampReq : 3|1@0+ (1,0) [0|1] ""  IHU
 SG_ CDC_CurrentDamperMode : 2|3@0+ (1,0) [0|7] ""  IHU

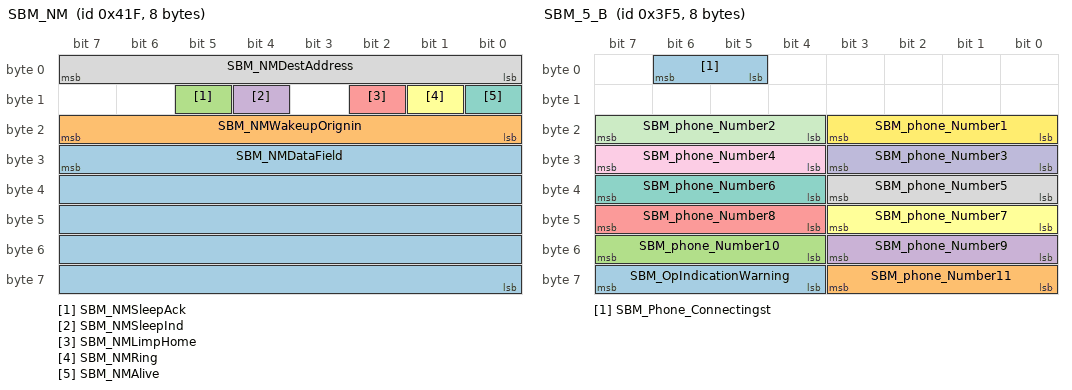
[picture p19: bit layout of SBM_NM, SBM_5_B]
BO_ 1055 SBM_NM: 8 SBM
 SG_ SBM_NMDataField : 31|40@0+ (1,0) [0|0] ""  Tester,PSDR,PSDL,AMP,LCU,HUD,PLGM,FLDCM,FRDCM,SCM,TSCM,IBCM,HVACF,IAL,RCP,FCP,HVSM,IHU,WCM,ETC,GWM
 SG_ SBM_NMWakeupOrignin : 23|8@0+ (1,0) [0|255] ""  Tester,PSDR,PSDL,AMP,LCU,HUD,PLGM,FLDCM,FRDCM,SCM,TSCM,IBCM,HVACF,IAL,RCP,FCP,HVSM,IHU,WCM,ETC,GWM
 SG_ SBM_NMSleepAck : 13|1@0+ (1,0) [0|1] ""  Tester,PSDR,PSDL,AMP,LCU,HUD,PLGM,FLDCM,FRDCM,SCM,TSCM,IBCM,HVACF,IAL,RCP,FCP,HVSM,IHU,WCM,ETC,GWM
 SG_ SBM_NMSleepInd : 12|1@0+ (1,0) [0|1] ""  Tester,PSDR,PSDL,AMP,LCU,HUD,PLGM,FLDCM,FRDCM,SCM,TSCM,IBCM,HVACF,IAL,RCP,FCP,HVSM,IHU,WCM,ETC,GWM
 SG_ SBM_NMLimpHome : 10|1@0+ (1,0) [0|1] ""  Tester,PSDR,PSDL,AMP,LCU,HUD,PLGM,FLDCM,FRDCM,SCM,TSCM,IBCM,HVACF,IAL,RCP,FCP,HVSM,IHU,WCM,ETC,GWM
 SG_ SBM_NMRing : 9|1@0+ (1,0) [0|1] ""  Tester,PSDR,PSDL,AMP,LCU,HUD,PLGM,FLDCM,FRDCM,SCM,TSCM,IBCM,HVACF,IAL,RCP,FCP,HVSM,IHU,WCM,ETC,GWM
 SG_ SBM_NMAlive : 8|1@0+ (1,0) [0|1] ""  Tester,PSDR,PSDL,AMP,LCU,HUD,PLGM,FLDCM,FRDCM,SCM,TSCM,IBCM,HVACF,IAL,RCP,FCP,HVSM,IHU,WCM,ETC,GWM
 SG_ SBM_NMDestAddress : 7|8@0+ (1,0) [0|255] ""  Tester,PSDR,PSDL,AMP,LCU,HUD,PLGM,FLDCM,FRDCM,SCM,TSCM,IBCM,HVACF,IAL,RCP,FCP,HVSM,IHU,WCM,ETC,GWM

BO_ 781 SBM_9_B: 8 SBM
 SG_ SBM_WelcomeToken4 : 31|8@0+ (1,0) [0|255] ""  IHU
 SG_ SBM_WelcomeToken3 : 23|8@0+ (1,0) [0|255] ""  IHU
 SG_ SBM_WelcomeToken2 : 15|8@0+ (1,0) [0|255] ""  IHU
 SG_ SBM_WelcomeToken1 : 7|8@0+ (1,0) [0|255] ""  IHU

BO_ 1013 SBM_5_B: 8 SBM
 SG_ SBM_OpIndicationWarning : 63|4@0+ (1,0) [0|1] ""  IBCM,IHU,GWM
 SG_ SBM_phone_Number11 : 59|4@0+ (1,0) [0|15] ""  IHU,GWM
 SG_ SBM_phone_Number10 : 55|4@0+ (1,0) [0|15] ""  IHU,GWM
 SG_ SBM_phone_Number9 : 51|4@0+ (1,0) [0|15] ""  IHU,GWM
 SG_ SBM_phone_Number8 : 47|4@0+ (1,0) [0|15] ""  IHU,GWM
 SG_ SBM_phone_Number7 : 43|4@0+ (1,0) [0|15] ""  IHU,GWM
 SG_ SBM_phone_Number6 : 39|4@0+ (1,0) [0|15] ""  IHU,GWM
 SG_ SBM_phone_Number5 : 35|4@0+ (1,0) [0|15] ""  IHU,GWM
 SG_ SBM_phone_Number4 : 31|4@0+ (1,0) [0|15] ""  IHU,GWM
 SG_ SBM_phone_Number3 : 27|4@0+ (1,0) [0|15] ""  IHU,GWM
 SG_ SBM_phone_Number2 : 23|4@0+ (1,0) [0|15] ""  IHU,GWM
 SG_ SBM_phone_Number1 : 19|4@0+ (1,0) [0|15] ""  IHU,GWM
 SG_ SBM_Phone_Connectingst : 6|2@0+ (1,0) [0|3] ""  IBCM,IHU,FAPA,GWM

BO_ 1001 SBM_2_B: 8 SBM
 SG_ SBM_fatigueDringWarning : 23|2@0+ (1,0) [0|3] ""  IHU

CM_ BO_ 3221225472 "This is a message for not used signals, created by Vector CANdb++ DBC OLE DB Provider.";
CM_ SG_ 3221225472 ACU_FCWSeatbeltPretensionWarnCfg "Configurates FCW(Front Collision Warning) seatbelt pretension warning";
CM_ SG_ 3221225472 ACU_FCWSeatVibrationWarnCfg "Configurates FCW(Front Collision Warning) seat vibration warning";
CM_ SG_ 3221225472 ACU_FCWAcousticWarnCfg "Configurates FCW(Front Collision Warning) acoustic warning";
CM_ SG_ 3221225472 ACU_ACCStyleCfg "Configurates ACC(Adapt Crusie Control) style";
CM_ SG_ 3221225472 ACU_BCMHornCfg "Configurates BCM horn active on lock and unlock";
CM_ SG_ 3221225472 ACU_BCMDTRLFuncCfg "Configurates BCM day time running lamp function";
CM_ SG_ 3221225472 ACU_BCMRGearEnableRearWipeCfg "Configurates reverse gear enable rear wiping";
CM_ SG_ 3221225472 ACU_BCMAutoLightSnsCfg "Configurates sensibility of auto light";
CM_ SG_ 3221225472 ACU_BCMFollowMeHomeCfg "Configurates follow me home function";
CM_ SG_ 3221225472 ACU_BCMAutoUnlockCfg "Configurates auto unlock doors";
CM_ SG_ 3221225472 ACU_BCMRemoteUnlockCfg "Configurates remote unlock doors";
CM_ SG_ 3221225472 ACU_BCMFogLampTurnCfg "Configurates fog lamp auxiliary lighting when turning";
CM_ SG_ 3221225472 ACU_BCMRemoteCtrlFDMRMCfg "Configurates remote control driver door window and sun roof";
CM_ SG_ 3221225472 ACU_KickSnsCfg "Configurates kick sensor (sensor to open trunk)";
CM_ SG_ 3221225472 ACU_MaxTeleEngTimerCfg "Configurates max telematics engine running time";
CM_ SG_ 3221225472 ACU_PEPSOffCfg "Configurates PEPS Off function";
CM_ SG_ 3221225472 ACU_MaxTeleIGNOnTimerCfg "Configurates max telematics IGN ON time";
CM_ SG_ 3221225472 ACU_PEPSAPUCfg "Configurates PEPS APU(APU(approach unlock)function";
CM_ SG_ 3221225472 ACU_PEPSWALCfg "Configurates PEPS WAL((Walk Away Lock) function";
CM_ SG_ 3221225472 ACU_ICMLanguageCfg "Configurates ICM language";
CM_ SG_ 3221225472 ACU_ICMTimeModeCfg "Configurates ICM time mode";
CM_ SG_ 3221225472 ACU_ICMWarnSoundVolCfg "Configurates warning sound volume";
CM_ SG_ 3221225472 ACU_ICMSpdWarnCfg "Configurates speed warning";
CM_ SG_ 3221225472 ACU_PEPSSATOCfg "Configurates PEPS SATO(Sensorless Automatic Trunk Open) function";
CM_ SG_ 3221225472 ACU_PEPSWELCfg "Configurates PEPS WEL(Welcome light) Automatic Trunk Open) function";
CM_ SG_ 3221225472 ACU_BCMOSRMAutoFoldCfg "Configurates BCM outside rear view mirror auto folding function";
CM_ SG_ 3221225472 ACU_MSMKeyRecognitionCfg "Configurates MSM key recognition";
CM_ SG_ 3221225472 ACU_MSMWelcomeFuncCfg "Configurates MSM welcome function";
CM_ SG_ 3221225472 ACU_HVACFComfortCfg "Configurates Comfort curve";
CM_ SG_ 3221225472 ACU_HVACFAirCirCfg "Configurates the air circulation control mode when HVACF  in auto mode";
CM_ SG_ 3221225472 ACU_HVACFACCfg "Configurates the compressor control mode when HVACF in auto mode";
CM_ SG_ 3221225472 ACU_LDW_WarnSnsCfg "Configurates LDW warning sensibility";
CM_ SG_ 3221225472 TEL_BTAvrcpPlayMode "Bluetooth AVRCP playing mode";
CM_ SG_ 3221225472 TEL_TelematicsRegisterSt "Telematics register status";
CM_ SG_ 3221225472 TEL_BTAutoconectingSt "Bluetooth autoconnecting active state";
CM_ SG_ 3221225472 TEL_BTPowerSt "Bluetooth power state";
CM_ SG_ 3221225472 TEL_BTManualMode "Bluetooth manual mode";
CM_ SG_ 3221225472 TEL_BTHisdel "Delete Bluetooth pairing record";
CM_ SG_ 3221225472 TEL_BTHandfreeSt "Bluetooth handfree state";
CM_ SG_ 3221225472 TEL_BTAvrcpSt "Bluetooth AVRCP state";
CM_ SG_ 3221225472 TEL_TelematicsModeActSt "Telematics mode active status";
CM_ SG_ 3221225472 ACU_EVSwRq "EV Switch request";
CM_ SG_ 3221225472 BCS_2_MsgCounter "The MessageCounter is a 0 ~ 15 counter, increased of one unit on every message transmission";
CM_ SG_ 3221225472 BCM_BCAN_2_Checksum "Checksum = (byte0 +byte1 …+ byte6) XOR 0xFF";
CM_ SG_ 3221225472 BCM_BCAN_2_MsgCounter "The message counter is a 0-15 counter, increased of one unit on every message transmission";
CM_ SG_ 3221225472 ADAS_HWA_ILCWaitReasonLeft "left ILC lane change waiting reason";
CM_ SG_ 3221225472 ADAS_HWA_ILCWaitReasonRight "right ILC lane change waiting reason";
CM_ SG_ 3221225472 PAS_Mode "Mode";
CM_ SG_ 3221225472 ICM_SetPedalLevelUp "Set Pedal Level up";
CM_ SG_ 3221225472 ICM_SetPedalLevelDown "Set Pedal Level down";
CM_ SG_ 3221225472 ACU_IFC_ZoneCode "Zone code";
CM_ SG_ 3221225472 ACU_IFC_SpeedLimitUnit "Speed limit unit";
CM_ SG_ 3221225472 ACU_IFC_SpeedLimit "Limit speed";
CM_ SG_ 3221225472 ACU_IFC_RoadType "Road type";
CM_ SG_ 3221225472 SRS_1_Checksum "Checksum of the crash output status";
CM_ SG_ 3221225472 SRS_1_MsgCounter "Message counter";
CM_ SG_ 3221225472 ICM_TripB "Trip odometer second";
CM_ SG_ 3221225472 ICM_TripBVD "ICM_TripB valid value";
CM_ SG_ 3221225472 ICM_TripA "Trip odometer one";
CM_ SG_ 3221225472 ICM_TripAVD "ICM_TripA valid value";
CM_ SG_ 3221225472 ICM_VehAverageSpd "Vehicle average speed";
CM_ SG_ 863 TEL_TelematicsRegisterSt "Telematics register status";
CM_ SG_ 863 TEL_BTManualMode "Bluetooth manual mode";
CM_ SG_ 863 TEL_BTAvrcpSt "Bluetooth AVRCP state";
CM_ SG_ 863 TEL_BTAvrcpPlayMode "Bluetooth AVRCP playing mode";
CM_ SG_ 863 TEL_BTHandfreeSt "Bluetooth handfree state";
CM_ SG_ 863 TEL_BTHisdel "Delete Bluetooth pairing record";
CM_ SG_ 863 TEL_BTAutoconectingSt "Bluetooth autoconnecting active state";
CM_ SG_ 863 TEL_BTPowerSt "Bluetooth power state";
CM_ SG_ 863 TEL_TelematicsModeActSt "Telematics mode active status";
CM_ BO_ 638 "新增";
CM_ SG_ 638 VCU_DischgTimeCount "discharge once time count";
CM_ SG_ 638 VCU_DischgEngStartSocResp "Engine start SOC point configuration response in discharge";
CM_ SG_ 638 VCU_DischgEngStartPermit "Engine start permission state in discharge";
CM_ SG_ 638 VCU_DischgActiveSt "Discharge active status";
CM_ SG_ 638 VCU_DischgEndVehRng "equivalent vehicle drive range of the set discharge ending SOC";
CM_ SG_ 638 VCU_DischgSocCfgResp "discharge ending SOC point configuration response";
CM_ SG_ 558 HVSPRR_RR_Freezepemissions_FuncC "HVSPR_RL Function configuration command Freeze";
CM_ SG_ 558 HVSPRR_RRSPABUttonSt "Right SPA";
CM_ SG_ 557 HVSPRL_RL_Freezepemissions_FuncC "HVSPRL_RL Function configuration command Freeze";
CM_ SG_ 557 HVSPRL_RLSPABUttonSt "Left SPA";
CM_ SG_ 1123 MSM_NMWakeupOrignin "Origin of the wake up";
CM_ SG_ 1123 MSM_NMDestAddress "NM destination address";
CM_ SG_ 764 MSM_RRSeatRecoveryModeSt "Rear Right Seat Recovery mode Status";
CM_ SG_ 764 MSM_RRSeatSpaModeSt "Rear Right Seat SPA mode Status";
CM_ SG_ 764 MSM_RRSeatMemoryModeSt "Rear Right Seat Memory mode Status";
CM_ SG_ 764 MSM_RRSeatVoiceCtrlResp "Rear Right Seat Voice control response";
CM_ SG_ 764 MSM_RRSeatOperationSt "Rear Right Seat Operation status";
CM_ SG_ 764 MSM_RRSeatShoulderCurrentPst "Rear Right Seat Shoulder Current  Position Percentage";
CM_ SG_ 764 MSM_RRSeatOttoman2CurrentPst "Rear Right Seat Ottoman2 Current  Position Percentage";
CM_ SG_ 764 MSM_RRSeatOttoman1CurrentPst "Rear Right Seat Ottoman1 Current  Position Percentage";
CM_ SG_ 764 MSM_RRSeatBackCurrentPst "Rear Right Seat Back Current  Position Percentage";
CM_ SG_ 764 MSM_RRSeatSlideCurrentPst "Rear Right Seat Slide Current  Position Percentage";
CM_ SG_ 764 MSM_RRSeatSlidepositionSensorSig "Rear Right Seat Slide Position Sensor Switch SIgnal";
CM_ SG_ 764 MSM_RRSlideLockSwitch2Sig "Rear Right Seat slide Lock Switch2 signal";
CM_ SG_ 764 MSM_RRSlideLockSwitch1Sig "Rear Right Seat slide Lock Switch1 signal";
CM_ SG_ 764 MSM_RRSeatMemoryModePositionSt "Rear Right Seat Momery mode position stored status feedback to ACU";
CM_ SG_ 764 MSM_RRSeatWelcomeFuncCfgSt "Rear Right Seat Welcome Function Configuration Status";
CM_ SG_ 1084 MSM_NMWakeupOrignin "Origin of the wake up";
CM_ SG_ 1084 MSM_NMDestAddress "NM destination address";
CM_ SG_ 767 MSM_RLSeatRecoveryModeSt "Rear Left Seat Recovery mode Status";
CM_ SG_ 767 MSM_RLSeatSpaModeSt "Rear Left Seat SPA mode Status";
CM_ SG_ 767 MSM_RLSeatMemoryModeSt "Rear Left Seat Memory mode Status";
CM_ SG_ 767 MSM_RLSeatVoiceCtrlResp "Rear Right Seat Voice control response";
CM_ SG_ 767 MSM_RLSeatOperationSt "Rear Left Seat Operation status";
CM_ SG_ 767 MSM_RLSeatShoulderCurrentPst "Rear Left Seat Shoulder Current  Position Percentage";
CM_ SG_ 767 MSM_RLSeatOttoman2CurrentPst "Rear Left Seat Ottoman2 Current  Position Percentage";
CM_ SG_ 767 MSM_RLSeatOttoman1CurrentPst "Rear Left Seat Ottoman1 Current  Position Percentage";
CM_ SG_ 767 MSM_RLSeatBackCurrentPst "Rear Left Seat Back Current  Position Percentage";
CM_ SG_ 767 MSM_RLSeatSlideCurrentPst "Rear Left Seat Slide Current  Position Percentage";
CM_ SG_ 767 MSM_RLSeatSlidepositionSensorSig "Rear Left Seat Slide Position Sensor Switch SIgnal";
CM_ SG_ 767 MSM_RLSlideLockSwitch2Sig "Rear Left Seat slide Lock Switch2 signal";
CM_ SG_ 767 MSM_RLSlideLockSwitch1Sig "Rear Left Seat slide Lock Switch1 signal";
CM_ SG_ 767 MSM_RLSeatMemoryModePositionSt "Rear Left Seat Momery mode position stored status feedback to ACU";
CM_ SG_ 767 MSM_RLSeatWelcomeFuncCfgSt "Rear Left Seat Welcome Function Configuration Status";
CM_ SG_ 866 PSDR_BuzzerRequest "Buzzer Request";
CM_ SG_ 866 PSDR_DoorSpdst "Power Sliding Door Speed state";
CM_ SG_ 866 PSDR_FuelOpenSt "Fuel Open forbidden Open/Close.";
CM_ SG_ 866 PSDR_MainSWOffForbSt "Main SW OFF forbidden Open/Close.";
CM_ SG_ 866 PSD_ModeSt "Mode state of PSD";
CM_ SG_ 866 PSDR_PinchDet "Right Power Sliding Door pinch detect";
CM_ SG_ 866 PSDR_OperationMode "Right Power Sliding Door Operation Mode";
CM_ SG_ 866 PSDR_DoorPst "Right Power Sliding Door  position";
CM_ SG_ 865 PSDL_BuzzerRequest "Buzzer Request";
CM_ SG_ 865 PSDL_DoorSpdst "Power Sliding Door Speed state";
CM_ SG_ 865 PSDL_FuelOpenSt "Fuel Open forbidden Open/Close.";
CM_ SG_ 865 PSDL_MainSWOffForbSt "Main SW OFF forbidden Open/Close.";
CM_ SG_ 865 PSDL_PinchDet "Left Power Sliding Door pinch detect";
CM_ SG_ 865 PSDL_OperationMode "Left Power Sliding Door Operation Mode";
CM_ SG_ 865 PSDL_DoorPst "Left Power Sliding Door  position";
CM_ SG_ 1003 AVAS_ActivatedSt "AVAS activated status";
CM_ SG_ 118 TEL_ModuleResetSt "TBOX Module Reset Status";
CM_ SG_ 118 TEL_ResetFailReason "TBOX  Reset Fail Reason";
CM_ SG_ 860 TEL_MobileSignalSt "Mobile signal state";
CM_ SG_ 860 TEL_MobilePowerSt "Mobile power state";
CM_ SG_ 860 TEL_AVRCPSupportSt "BT AVRCP protocol support status of mobile";
CM_ SG_ 860 TEL_A2DPSupportSt "BT A2DP protocol support status of mobile";
CM_ SG_ 860 TEL_PhoneCallSt "The phone call status of Ecall or Bcall or bluetooth";
CM_ SG_ 860 TEL_BTConnectingSt "Bluetooth connect status";
CM_ SG_ 860 TEL_BTConnectingAct "Bluetooth conneting active state";
CM_ SG_ 860 TEL_BTDisplayAct "Bluetooth icon display active";
CM_ SG_ 860 TEL_PhoneNumber "Phone number";
CM_ SG_ 926 TEL_Time_Sec "Second number";
CM_ SG_ 926 TEL_BookChrgSt "Book charge state";
CM_ SG_ 926 TEL_TimeVD "TEL time valid value";
CM_ SG_ 926 TEL_Time_Min "Minute number";
CM_ SG_ 926 TEL_Time_Day "Day number";
CM_ SG_ 926 TEL_Time_Hour "Hour number";
CM_ SG_ 926 TEL_Time_Month "Month number";
CM_ SG_ 926 TEL_Time_Year "Year number";
CM_ SG_ 160 TEL_PCS_EventRecordCtrlReq "Remote wakeup PCS's event record function";
CM_ SG_ 160 TEL_PCS_CtrlReq "Remote wakeup PCS";
CM_ SG_ 1103 GWM_NMWakeupOrignin "Origin of the wake up";
CM_ SG_ 1103 GWM_NMDestAddress "NM Destination Address";
CM_ SG_ 802 GW_VehicleModeBroadcast "Broadcast Vehicle Mode";
CM_ SG_ 968 GW_LowBatPreWarning "Low battery warning level";
CM_ SG_ 854 GSM_WarnInfo "GSM warn information to ICM";
CM_ SG_ 854 GSM_GearShiftLeverPstReq "Gear shift lever postion request";
CM_ SG_ 854 GSM_DriveModeRespFail "Indicaties the GSM can not response to the selected dive mode";
CM_ SG_ 786 ADAS_AcceComfUpperValue "this signal indicates the upper taget acceleration";
CM_ SG_ 786 MRR_PEBSObjType "The type of SDF target object when PEBS(includled FCW/FCW-Peds or AEB/AEB-Peds )is active.";
CM_ SG_ 786 MRR_ACCQuitSound "ACC  quit sound remind";
CM_ SG_ 786 MRR_ISLACC_St "This signal indicates if the ISLACC is enable";
CM_ SG_ 786 MRR_FCWWarnDistance "FCW Warning distance";
CM_ SG_ 786 MRR_AEBInterventionSt "This signal indicates if the AEB(Auto Emerrgency Braking) intervents";
CM_ SG_ 786 MRR_AEBOffSt "This signal indicates if the AEB(Auto Emerrgency Braking) is deactivated";
CM_ SG_ 786 MRR_AEBFaultSt "This signal indicates the AEB(Auto Emerrgency Braking) fault status";
CM_ SG_ 786 MRR_AEB_PEDPFaultSt "This signal indicates the AEB_PEDP(AEB_Pedestrian Protection) fault status";
CM_ SG_ 786 MRR_FCWLatentWarn "Visual warning. used with signal MRR_ FCWActiveSt";
CM_ SG_ 786 MRR_FCWPreWarn "Acoustic pre warning.Used with  signal MRR_ FCWActiveSt";
CM_ SG_ 786 MRR_FCWInterventionSt "This signal indicates if the FCW(Front Collision Warning) intervents";
CM_ SG_ 786 MRR_FCWFaultSt "This signal indicates the FCW (Front Collision Warning) fault status";
CM_ SG_ 786 MRR_FCWOffSt "This signal indicates if the FCW (Front Collision Warning) is deactivated";
CM_ SG_ 786 MRR_TargetSpd "Desired target speed from the driver";
CM_ SG_ 786 MRR_TauGapSet "The set timeGap from driver, should be displayed to driver and if the set value changes";
CM_ SG_ 786 MRR_TargetDistanceSt "Desired distance stage for the display, distance stage 4 indicates the furthest distance";
CM_ SG_ 786 MRR_ObjectCapturedSt "Status of object capturing";
CM_ SG_ 786 MRR_ACCTakeOverReq "ACC(Adaptive Cruise Control) request for driver take over";
CM_ SG_ 786 MRR_ACCFuncCancel "Alert signal to inform of ACC(Adaptive Cruise Control) function cancel";
CM_ SG_ 786 MRR_ACCGoNotifier "ACC(Adaptive Cruise Control) go notifier signal for indication";
CM_ SG_ 786 MRR_ACCActiveSt "This signal indicates if the ACC(Adaptive Cruise Control)) is actived";
CM_ SG_ 786 MRR_ACCFaultSt "Error indication of the ACC(Adaptive Cruise Control) system";
CM_ SG_ 786 MRR_ACCTextInfo "ACC text infor for driver";
CM_ SG_ 786 MRR_ACCMode "This signal indicates ACC(Adaptive cruise control )status";
CM_ SG_ 861 TMM_ThermalWarning "Warning before thermal fail safe";
CM_ SG_ 861 TMM_CouplingThermalFailSafe "Coupling thermal failsafe";
CM_ SG_ 861 TMM_DiagnosticLampReq "Diagnostic lamp request";
CM_ SG_ 861 TMM_SysOperatingMode "System operating mode";
CM_ SG_ 840 EPS_FunctionStyleSt "EPS function style state";
CM_ SG_ 840 EPS_WarnLamp "Streering Warning Lamp";
CM_ SG_ 775 EPB_StpOnBrkToRelParkBrkIndOn "Brake Pedal feeling Mode configuration status";
CM_ SG_ 775 EPB_SysDispMsgReq "EPB system display message request";
CM_ SG_ 775 EPB_FailSt "EPB fail status,to indicate wether EPB can response to external apply  request or not";
CM_ SG_ 775 EPB_SysStIndReq "EPB system status indication request";
CM_ SG_ 775 EPB_SysAudWarnReq "EPB system audible warning request";
CM_ SG_ 775 EPB_SysSt "EPB system status";
CM_ SG_ 775 EPB_SysWarnIndReq "EPB system warning indication request";
CM_ SG_ 816 SRS_Row2MiddleSeatBeltSt "To identify whetherRow2 MiddleSeatBelt is buckled";
CM_ SG_ 816 SRS_Row2RightSeatBeltSt "To identify whetherRow2 RightSeatBelt is buckled";
CM_ SG_ 816 SRS_AirbagFaultSt "To illuminate or turn off airbag warning indicator";
CM_ SG_ 816 SRS_Row2LeftSeatBeltSt "To identify whetherRow2 LeftSeatBelt? is buckled";
CM_ SG_ 816 SRS_DriverSeatBeltSt "To identify whether Driver Seat Belt is buckled";
CM_ SG_ 816 SRS_PsngrSeatBeltSt "To identify whether Passenger Seat Belt is buckled";
CM_ SG_ 430 SRS_CrashOutputSt "To inform there's crash event happen in last 2sec.
After 2 sec, the signal will turn to 0
（crash here means any one of the 4 status defined above）(总的碰撞事件)";
CM_ BO_ 829 "the signal position will change after PT0";
CM_ SG_ 829 SAS_SteeringAngle "Steering wheel angle";
CM_ SG_ 829 SAS_SteeringAngleSpd "Steering wheel angle speed";
CM_ SG_ 829 SAS_TrimmingStatus "Indicates the trimming status of the steering angle sensor";
CM_ SG_ 829 SAS_CalibratedSt "The calibration information of steering angle sensor";
CM_ SG_ 829 SAS_SteeringAngleVD "SAS_SteeringAngle validity";
CM_ SG_ 667 BCS_RRWheelRotatedDirection "RR wheel rotate direction";
CM_ SG_ 667 BCS_RRWheelRotatedDirectionVD "RR wheel rotate direction validity";
CM_ SG_ 667 BCS_RLWheelRotatedDirectionVD "RL wheel rotate direction validity";
CM_ SG_ 667 BCS_RLWheelRotatedDirection "RL wheel rotate direction";
CM_ SG_ 667 BCS_FRWheelRotatedDirection "FR wheel rotate direction";
CM_ SG_ 667 BCS_FRWheelRotatedDirectionVD "FR wheel rotate direction validity";
CM_ SG_ 667 BCS_FLWheelRotatedDirectionVD "FL wheel rotate direction validity";
CM_ SG_ 667 BCS_FLWheelRotatedDirection "FL wheel rotate direction";
CM_ SG_ 667 BCS_RRWheelSpd "Current wheel speed information of rear right wheel";
CM_ SG_ 667 BCS_RRWheelSpdVD "Quality/fault information to current wheel speed of RRont left wheel,be used for validity of BCS_RRWheelSpd and BCS_RRWheelSpdEdgesSum signal";
CM_ SG_ 667 BCS_RLWheelSpd "Current wheel speed information of rear left wheel";
CM_ SG_ 667 BCS_RLWheelSpdVD "Quality/fault information to current wheel speed of front left wheel,be used for validity of BCS_RLWheelSpd and BCS_RLWheelSpdEdgesSum signal";
CM_ SG_ 667 BCS_FRWheelSpd "Current wheel speed information of front right wheel";
CM_ SG_ 667 BCS_FRWheelSpdVD "Quality/fault information to current wheel speed of front left wheel,be used for validity of BCS_FRWheelSpd and BCS_FRWheelSpdEdgesSum signal";
CM_ SG_ 667 BCS_FLWheelSpd "Current wheel speed information of front left wheel";
CM_ SG_ 667 BCS_FLWheelSpdVD "Quality/fault information to current wheel speed of front left wheel,be used for validity of BCS_FLWheelSpd and BCS_FLWheelSpdEdgesSum signal";
CM_ SG_ 838 BCS_HBBSt "Indicates the status of HBB";
CM_ SG_ 838 BCS_CDDAvailable "CDD(Controlled Deceleration for Driver) is available";
CM_ SG_ 838 BCS_CDDActive "CDD(Controlled Deceleration for Driver) is active";
CM_ SG_ 838 BCS_AWBAvailable "AWB(Automatic Warning Brake) is available";
CM_ SG_ 838 BCS_AWBActive "AWB(Automatic Warning Brake) is active";
CM_ SG_ 838 BCS_AEBAvailable "AEB(Automatic Emergency
Braking) is available";
CM_ SG_ 838 BCS_AEBActive "AEB(Automatic Emergency
Braking) is active (in deceleration)";
CM_ SG_ 838 BCS_ABPAvailable "ABP(Automatic brake Pre-fill) is available";
CM_ SG_ 838 BCS_ABPActive "ABP(Automatic brake Pre-fill) is active";
CM_ SG_ 838 BCS_AVHAvailable "HMI responsible, can get degrate AVH(Auto Vehicle Hold) statement from DSW and send out";
CM_ SG_ 838 BCS_AVHStandby "Indicates AVH(Auto Vehicle Hold)in standby mode or not";
CM_ SG_ 838 BCS_AVHSt "Indicates AVH(Auto Vehicle Hold)in active or not";
CM_ SG_ 838 BCS_HDCErrSt "HDC error Status";
CM_ SG_ 838 BCS_HHCErrSt "HHC error status";
CM_ SG_ 838 BCS_ABAavailable "The ABA(Adaptive Brake Assistance)  function is available";
CM_ SG_ 838 BCS_ABAactive "ABA(Adaptive Brake Assistance) is active";
CM_ SG_ 838 BCS_HDCCtrlSt "HDC(Hill Descent Control) Control status";
CM_ SG_ 838 BCS_VDCOff "VDC is switched off";
CM_ SG_ 838 BCS_TCSOff "TCS is switched off";
CM_ SG_ 838 BCS_BrakeOverHeat "Indicating brake temperature too high or not";
CM_ SG_ 608 BCS_VDCActiveSt "Indication that VDC system currently performs a brake/engine intervention when ESP adjust the posture of vehicle";
CM_ SG_ 608 BCS_VehSpd "Vehicle speed";
CM_ SG_ 608 BCS_VehSpdVD "Quality/fault information to vehicle speed";
CM_ SG_ 608 BCS_VDCFaultSt "VDC is switched off due to detected failure";
CM_ SG_ 608 BCS_TCSActiveSt "Indication that TCS system currently performs a brake/engine intervention";
CM_ SG_ 608 BCS_TCSFaultSt "TCS is switched off due to detected failure";
CM_ SG_ 608 BCS_EBDActiveSt "Indication that EBD system currently performs a brake/engine intervention";
CM_ SG_ 608 BCS_EBDFaultSt "ABS system has detected a heavy fault, which does not even allow a reliable electronic brake distribution and is therefore completely shut down";
CM_ SG_ 608 BCS_ABSFaultSt "ABS system has detected a failure which does no allow a reliable ABS regulation and is therefore switched off";
CM_ SG_ 608 BCS_ABSActiveSt "Indication that ABS system currently performs a brake intervention";
CM_ SG_ 823 BCS_RRWheelSpdEdgesSumVD "Quality/fault information to current wheel speed edges sum of rear right wheel";
CM_ SG_ 823 BCS_RLWheelSpdEdgesSumVD "Quality/fault information to current wheel speed edges sum of rear left wheel";
CM_ SG_ 823 BCS_FRWheelSpdEdgesSumVD "Quality/fault information to current wheel speed edges sum of front right wheel";
CM_ SG_ 823 BCS_FLWheelSpdEdgesSumVD "Quality/fault information to current wheel speed edges sum of front left wheel";
CM_ SG_ 823 BCS_RRWheelSpdEdgesSum "Accumulated sum of rising and falling edges of  rear right wheel speed sensor output·since IGN ON( the wheel plate have 48 teeth/cycle,the edge is 96)";
CM_ SG_ 823 BCS_RLWheelSpdEdgesSum "Accumulated sum of rising and falling edges of rear left wheel speed sensor output·since IGN ON( the wheel plate have 48 teeth/cycle,the edge is 96)";
CM_ SG_ 823 BCS_FRWheelSpdEdgesSum "Accumulated sum of rising and falling edges of front right wheel speed sensor output·since IGN ON( the wheel plate have 48 teeth/cycle,the edge is 96)";
CM_ SG_ 823 BCS_FLWheelSpdEdgesSum "Accumulated sum of rising and falling edges of front left wheel speed sensor output·since IGN ON( the wheel plate have 48 teeth/cycle,the edge is 96)";
CM_ SG_ 822 EMS_FuelPulse "Fuel consumption pulse";
CM_ SG_ 822 EMS_EngSpd "Engine speed";
CM_ SG_ 822 EMS_EngSpdVD "_EMS_EngSpd_ validity";
CM_ SG_ 822 EMS_EngWaterTempVD "_EMS_EngWaterTemp_ validity";
CM_ SG_ 822 EMS_EngSt "Engine running status";
CM_ SG_ 822 EMS_EPCSt "Engine usual mulfunction";
CM_ SG_ 822 EMS_MilSt "Emission malfunction indication";
CM_ SG_ 822 EMS_EngWaterTemp "Engine water temperature";
CM_ SG_ 785 RLR_AudioWarnRL "Rear left door speaker warning";
CM_ SG_ 785 RLR_AudioWarnFL "Front left door speaker warning";
CM_ SG_ 785 RRR_RCTAAssistType "RCTA assist type request";
CM_ SG_ 785 RLR_RCTAWarnLeft "the vehicle left warning in the RCTA feature";
CM_ SG_ 785 RLR_LCAWarnLeft "the vehicle left warning level in the LCA feature";
CM_ SG_ 785 RRR_AudioWarnRR "Rear right door speaker warning";
CM_ SG_ 785 RRR_AudioWarnFR "Front right door speaker warning";
CM_ SG_ 785 RRR_RCWWarn "the vehicle warning  level in the RCW feature";
CM_ SG_ 785 RRR_RCWSt "RCW(rear collision warning ) feature status";
CM_ SG_ 785 RRR_RCTAWarnRight "the vehicle right warning in the RCTA feature";
CM_ SG_ 785 RRR_LCAWarnRight "the vehicle right warning level in the LCA feature";
CM_ SG_ 785 RLR_VibrWarnL "Driver seat vibration warning left";
CM_ SG_ 785 RRR_LCASt "BSD-LCA Function status";
CM_ SG_ 785 RRR_RCTASt "RCTA Function status";
CM_ SG_ 785 RRR_DOWSt "DOW Function state";
CM_ SG_ 785 RLR_ExMirLedWarnL "Exterior mirror LED warning left";
CM_ SG_ 785 RLR_IALWarnRL "Rear left door light warning";
CM_ SG_ 785 RLR_IALWarnFL "Front left door light warning";
CM_ SG_ 785 RRR_ExMirLedWarnR "Exterior mirror LED warning right";
CM_ SG_ 785 RRR_VibrWarnR "Driver seat vibration warning right";
CM_ SG_ 785 RRR_IALWarnRR "Rear right door light warning";
CM_ SG_ 785 RRR_IALWarnFR "Front right door light warning";
CM_ SG_ 785 RRR_MRRSt "MRR systems ON OFF andError Status";
CM_ SG_ 785 RRR_ClusterLamp "Cluster lamp color status";
CM_ SG_ 439 PCU_RejectHeatProtectINH_OH "Reject lock/unlock request for p -motor hot
ICM receive 【PCU_Motor High failure
MOTH_FAIL】=2：failure，replay";
CM_ SG_ 439 PCU_UnlockFault "for system diagnosis";
CM_ SG_ 439 PCU_LockFault "for system diagnosis";
CM_ SG_ 439 PCU_LampRequest "Active in case of E_Park system fault occurred, reuqest for light up the diagnostic lamp on ICM.";
CM_ SG_ 762 HOD_HeatingTempOutSt "indaicating the set temperature is not reached within the specified time";
CM_ SG_ 762 HOD_HeatingThermSt "Indicating Heating thermistor fault";
CM_ SG_ 762 HOD_HeatingOverUnderCurrentSt "Indicating Heating over current or under current fault status";
CM_ SG_ 762 HOD_HeatingOtherFaultSt "Indicating  other Heating  Fault status";
CM_ SG_ 762 HOD_VBattOORFault "Indicating Battery Voltage Out of Range Fault";
CM_ SG_ 762 HOD_FaultSt "Indicating ECU SW or HW fault or Capacity sensor Fault status";
CM_ SG_ 762 HOD_LINComFault "J2602 LIN Communication Status";
CM_ SG_ 762 HOD_CalibrationSt "Open Wheel Recalibration Status";
CM_ SG_ 762 HOD_ApRestSt "Indicating HOD slave application reset status";
CM_ SG_ 762 HOD_HeatingSt "Indicating the working status of steering heating function.";
CM_ SG_ 762 HOD_TouchZone3 "Indicating Zone 3 touch status";
CM_ SG_ 762 HOD_TouchZone2 "Indicating Zone 2 touch status";
CM_ SG_ 762 HOD_TouchZone1 "Indicating Zone 1 touch status";
CM_ SG_ 728 CDC_ProhibitChangingMode "Electronic control suspension mode change is prohibited";
CM_ SG_ 728 CDC_WarningLampReq "Electronic control suspension warning lamp request";
CM_ SG_ 728 CDC_CurrentDamperMode "CDC Current damper Mode";
CM_ SG_ 1055 SBM_NMWakeupOrignin "Origin of the wake up";
CM_ SG_ 1055 SBM_NMDestAddress "NM Destination Address";
CM_ SG_ 781 SBM_WelcomeToken4 "Token 4th code for welcome account";
CM_ SG_ 781 SBM_WelcomeToken3 "Token 3rd code for welcome account";
CM_ SG_ 781 SBM_WelcomeToken2 "Token 2nd code for welcome account";
CM_ SG_ 781 SBM_WelcomeToken1 "Token 1st code for welcome account";
CM_ SG_ 1013 SBM_OpIndicationWarning "Operation indication warning";
CM_ SG_ 1013 SBM_phone_Number11 "SBM phone Number 11";
CM_ SG_ 1013 SBM_phone_Number10 "SBM phone Number 10";
CM_ SG_ 1013 SBM_phone_Number9 "SBM phone Number 9";
CM_ SG_ 1013 SBM_phone_Number8 "SBM phone Number 8";
CM_ SG_ 1013 SBM_phone_Number7 "SBM phone Number 7";
CM_ SG_ 1013 SBM_phone_Number6 "SBM phone Number 6";
CM_ SG_ 1013 SBM_phone_Number5 "SBM phone Number 5";
CM_ SG_ 1013 SBM_phone_Number4 "SBM phone Number 4";
CM_ SG_ 1013 SBM_phone_Number3 "SBM phone Number 3";
CM_ SG_ 1013 SBM_phone_Number2 "SBM phone Number 2";
CM_ SG_ 1013 SBM_phone_Number1 "SBM phone Number 1";
CM_ SG_ 1013 SBM_Phone_Connectingst "SBM  and Pohne connecting   satus";
CM_ SG_ 1001 SBM_fatigueDringWarning "SBM judge driver whether fatigue driving";
BA_DEF_ SG_  "Remark" STRING ;
BA_DEF_ SG_  "EventCommandSignal" ENUM  "No","Yes";
BA_DEF_ SG_  "GatewayedSignals" ENUM  "No","Yes";
BA_DEF_ SG_  "GenSigTimeoutValue" INT 0 0;
BA_DEF_ SG_  "GenSigStartValue" INT 0 0;
BA_DEF_ SG_  "GenSigInvalidValue" INT 0 0;
BA_DEF_ SG_  "GenSigInactiveValue" INT 0 0;
BA_DEF_ BO_  "GenMsgCycleTimeFast" INT 0 0;
BA_DEF_ BO_  "GenMsgCycleTime" INT 0 0;
BA_DEF_ SG_  "GenSigSendType" ENUM  "Trigger","Passive";
BA_DEF_ BO_  "GenMsgSendType" ENUM  "Periodic","Event","IfActive","POE","PA";
BA_DEF_ SG_  "SystemSignalLongSymbol" STRING ;
BA_DEF_DEF_  "Remark" "*";
BA_DEF_DEF_  "EventCommandSignal" "No";
BA_DEF_DEF_  "GatewayedSignals" "No";
BA_DEF_DEF_  "GenSigTimeoutValue" 0;
BA_DEF_DEF_  "GenSigStartValue" 0;
BA_DEF_DEF_  "GenSigInvalidValue" 0;
BA_DEF_DEF_  "GenSigInactiveValue" 0;
BA_DEF_DEF_  "GenMsgCycleTimeFast" 0;
BA_DEF_DEF_  "GenMsgCycleTime" 0;
BA_DEF_DEF_  "GenSigSendType" "Trigger";
BA_DEF_DEF_  "GenMsgSendType" "Periodic";
BA_DEF_DEF_  "SystemSignalLongSymbol" "";
BA_ "GenMsgCycleTime" BO_ 538 200;
BA_ "GenMsgCycleTime" BO_ 539 30000;
BA_ "GenMsgCycleTime" BO_ 880 100;
BA_ "GenMsgCycleTime" BO_ 924 20;
BA_ "GenMsgCycleTime" BO_ 520 100;
BA_ "GenMsgCycleTime" BO_ 1536 200;
BA_ "GenMsgSendType" BO_ 119 1;
BA_ "GenMsgCycleTime" BO_ 1567 500;
BA_ "GenMsgCycleTime" BO_ 412 100;
BA_ "GenMsgSendType" BO_ 148 1;
BA_ "GenMsgCycleTime" BO_ 627 500;
BA_ "GenMsgCycleTime" BO_ 886 200;
BA_ "GenMsgSendType" BO_ 179 1;
BA_ "GenMsgCycleTime" BO_ 837 100;
BA_ "GenMsgCycleTime" BO_ 898 200;
BA_ "GenMsgSendType" BO_ 1126 1;
BA_ "GenMsgSendType" BO_ 34 1;
BA_ "GenMsgCycleTime" BO_ 869 100;
BA_ "GenMsgSendType" BO_ 1105 1;
BA_ "GenMsgCycleTime" BO_ 648 100;
BA_ "GenMsgSendType" BO_ 1617 2;
BA_ "GenMsgCycleTime" BO_ 1617 200;
BA_ "GenMsgCycleTimeFast" BO_ 1617 100;
BA_ "GenMsgSendType" BO_ 1616 2;
BA_ "GenMsgCycleTime" BO_ 1616 200;
BA_ "GenMsgCycleTimeFast" BO_ 1616 100;
BA_ "GenMsgSendType" BO_ 1733 2;
BA_ "GenMsgCycleTime" BO_ 1733 200;
BA_ "GenMsgCycleTimeFast" BO_ 1733 100;
BA_ "GenMsgSendType" BO_ 1734 2;
BA_ "GenMsgCycleTime" BO_ 1734 200;
BA_ "GenMsgCycleTimeFast" BO_ 1734 100;
BA_ "GenMsgSendType" BO_ 143 1;
BA_ "GenMsgCycleTime" BO_ 1005 500;
BA_ "GenMsgCycleTime" BO_ 1004 500;
BA_ "GenMsgSendType" BO_ 74 1;
BA_ "GenMsgCycleTime" BO_ 832 100;
BA_ "GenMsgSendType" BO_ 350 3;
BA_ "GenMsgCycleTime" BO_ 350 1000;
BA_ "GenMsgCycleTimeFast" BO_ 350 100;
BA_ "GenMsgCycleTime" BO_ 927 100;
BA_ "GenMsgCycleTime" BO_ 912 100;
BA_ "GenMsgCycleTime" BO_ 779 100;
BA_ "GenMsgCycleTime" BO_ 995 200;
BA_ "GenMsgCycleTime" BO_ 811 100;
BA_ "GenMsgCycleTime" BO_ 907 100;
BA_ "GenMsgCycleTime" BO_ 848 100;
BA_ "GenMsgCycleTime" BO_ 908 200;
BA_ "GenMsgCycleTime" BO_ 1541 1000;
BA_ "GenMsgCycleTime" BO_ 1540 1000;
BA_ "GenMsgCycleTime" BO_ 1539 1000;
BA_ "GenMsgCycleTime" BO_ 1542 1000;
BA_ "GenMsgCycleTime" BO_ 1537 1000;
BA_ "GenMsgCycleTime" BO_ 863 100;
BA_ "GenMsgCycleTime" BO_ 638 100;
BA_ "GenMsgSendType" BO_ 558 3;
BA_ "GenMsgCycleTimeFast" BO_ 558 40;
BA_ "GenMsgCycleTime" BO_ 558 500;
BA_ "GenMsgSendType" BO_ 557 3;
BA_ "GenMsgCycleTimeFast" BO_ 557 40;
BA_ "GenMsgCycleTime" BO_ 557 500;
BA_ "GenMsgCycleTime" BO_ 764 100;
BA_ "GenMsgCycleTime" BO_ 767 100;
BA_ "GenMsgCycleTime" BO_ 866 100;
BA_ "GenMsgCycleTime" BO_ 865 100;
BA_ "GenMsgCycleTime" BO_ 1003 200;
BA_ "GenMsgSendType" BO_ 118 1;
BA_ "GenMsgCycleTime" BO_ 860 200;
BA_ "GenMsgCycleTime" BO_ 926 500;
BA_ "GenMsgSendType" BO_ 160 1;
BA_ "GenMsgCycleTimeFast" BO_ 802 100;
BA_ "GenMsgCycleTime" BO_ 802 1000;
BA_ "GenMsgCycleTime" BO_ 968 100;
BA_ "GenMsgCycleTime" BO_ 854 100;
BA_ "GenMsgCycleTime" BO_ 786 100;
BA_ "GenMsgCycleTime" BO_ 861 100;
BA_ "GenMsgCycleTime" BO_ 840 100;
BA_ "GenMsgCycleTime" BO_ 775 100;
BA_ "GenMsgCycleTime" BO_ 816 100;
BA_ "GenMsgCycleTime" BO_ 430 20;
BA_ "GenMsgCycleTime" BO_ 829 100;
BA_ "GenMsgCycleTime" BO_ 667 50;
BA_ "GenMsgCycleTime" BO_ 838 100;
BA_ "GenMsgCycleTime" BO_ 608 10;
BA_ "GenMsgCycleTime" BO_ 823 20;
BA_ "GenMsgCycleTime" BO_ 822 100;
BA_ "GenMsgCycleTime" BO_ 785 50;
BA_ "GenMsgCycleTime" BO_ 439 500;
BA_ "GenMsgCycleTime" BO_ 762 150;
BA_ "GenMsgCycleTime" BO_ 728 100;
BA_ "GenMsgSendType" BO_ 781 4;
BA_ "GenMsgCycleTimeFast" BO_ 781 100;
BA_ "GenMsgCycleTime" BO_ 781 1000;
BA_ "GenMsgCycleTime" BO_ 1013 100;
BA_ "GenMsgCycleTime" BO_ 1001 100;
BA_ "Remark" SG_ 3221225472 ACU_FCWSeatbeltPretensionWarnCfg "";
BA_ "EventCommandSignal" SG_ 3221225472 ACU_FCWSeatbeltPretensionWarnCfg 1;
BA_ "GenSigSendType" SG_ 3221225472 ACU_FCWSeatbeltPretensionWarnCfg 1;
BA_ "Remark" SG_ 3221225472 ACU_FCWSeatVibrationWarnCfg "";
BA_ "EventCommandSignal" SG_ 3221225472 ACU_FCWSeatVibrationWarnCfg 1;
BA_ "GenSigSendType" SG_ 3221225472 ACU_FCWSeatVibrationWarnCfg 1;
BA_ "Remark" SG_ 3221225472 ACU_FCWAcousticWarnCfg "";
BA_ "EventCommandSignal" SG_ 3221225472 ACU_FCWAcousticWarnCfg 1;
BA_ "GenSigSendType" SG_ 3221225472 ACU_FCWAcousticWarnCfg 1;
BA_ "Remark" SG_ 3221225472 ACU_ACCStyleCfg "";
BA_ "EventCommandSignal" SG_ 3221225472 ACU_ACCStyleCfg 1;
BA_ "GenSigSendType" SG_ 3221225472 ACU_ACCStyleCfg 1;
BA_ "Remark" SG_ 3221225472 ACU_BCMHornCfg "";
BA_ "EventCommandSignal" SG_ 3221225472 ACU_BCMHornCfg 1;
BA_ "GenSigSendType" SG_ 3221225472 ACU_BCMHornCfg 1;
BA_ "Remark" SG_ 3221225472 ACU_BCMDTRLFuncCfg "";
BA_ "EventCommandSignal" SG_ 3221225472 ACU_BCMDTRLFuncCfg 1;
BA_ "GenSigSendType" SG_ 3221225472 ACU_BCMDTRLFuncCfg 1;
BA_ "Remark" SG_ 3221225472 ACU_BCMRGearEnableRearWipeCfg "";
BA_ "EventCommandSignal" SG_ 3221225472 ACU_BCMRGearEnableRearWipeCfg 1;
BA_ "GenSigSendType" SG_ 3221225472 ACU_BCMRGearEnableRearWipeCfg 1;
BA_ "Remark" SG_ 3221225472 ACU_BCMAutoLightSnsCfg "";
BA_ "EventCommandSignal" SG_ 3221225472 ACU_BCMAutoLightSnsCfg 1;
BA_ "GenSigSendType" SG_ 3221225472 ACU_BCMAutoLightSnsCfg 1;
BA_ "Remark" SG_ 3221225472 ACU_BCMFollowMeHomeCfg "";
BA_ "EventCommandSignal" SG_ 3221225472 ACU_BCMFollowMeHomeCfg 1;
BA_ "GenSigSendType" SG_ 3221225472 ACU_BCMFollowMeHomeCfg 1;
BA_ "Remark" SG_ 3221225472 ACU_BCMAutoUnlockCfg "";
BA_ "EventCommandSignal" SG_ 3221225472 ACU_BCMAutoUnlockCfg 1;
BA_ "GenSigSendType" SG_ 3221225472 ACU_BCMAutoUnlockCfg 1;
BA_ "Remark" SG_ 3221225472 ACU_BCMRemoteUnlockCfg "";
BA_ "EventCommandSignal" SG_ 3221225472 ACU_BCMRemoteUnlockCfg 1;
BA_ "GenSigSendType" SG_ 3221225472 ACU_BCMRemoteUnlockCfg 1;
BA_ "Remark" SG_ 3221225472 ACU_BCMFogLampTurnCfg "";
BA_ "EventCommandSignal" SG_ 3221225472 ACU_BCMFogLampTurnCfg 1;
BA_ "GenSigSendType" SG_ 3221225472 ACU_BCMFogLampTurnCfg 1;
BA_ "Remark" SG_ 3221225472 ACU_BCMRemoteCtrlFDMRMCfg "";
BA_ "EventCommandSignal" SG_ 3221225472 ACU_BCMRemoteCtrlFDMRMCfg 1;
BA_ "GenSigSendType" SG_ 3221225472 ACU_BCMRemoteCtrlFDMRMCfg 1;
BA_ "Remark" SG_ 3221225472 ACU_KickSnsCfg "";
BA_ "EventCommandSignal" SG_ 3221225472 ACU_KickSnsCfg 1;
BA_ "GenSigSendType" SG_ 3221225472 ACU_KickSnsCfg 1;
BA_ "Remark" SG_ 3221225472 ACU_MaxTeleEngTimerCfg "";
BA_ "EventCommandSignal" SG_ 3221225472 ACU_MaxTeleEngTimerCfg 1;
BA_ "GenSigSendType" SG_ 3221225472 ACU_MaxTeleEngTimerCfg 1;
BA_ "GenSigStartValue" SG_ 3221225472 ACU_MaxTeleEngTimerCfg 63;
BA_ "Remark" SG_ 3221225472 ACU_PEPSOffCfg "";
BA_ "EventCommandSignal" SG_ 3221225472 ACU_PEPSOffCfg 1;
BA_ "GenSigSendType" SG_ 3221225472 ACU_PEPSOffCfg 1;
BA_ "Remark" SG_ 3221225472 ACU_MaxTeleIGNOnTimerCfg "";
BA_ "EventCommandSignal" SG_ 3221225472 ACU_MaxTeleIGNOnTimerCfg 1;
BA_ "GenSigSendType" SG_ 3221225472 ACU_MaxTeleIGNOnTimerCfg 1;
BA_ "GenSigStartValue" SG_ 3221225472 ACU_MaxTeleIGNOnTimerCfg 63;
BA_ "Remark" SG_ 3221225472 ACU_PEPSAPUCfg "";
BA_ "EventCommandSignal" SG_ 3221225472 ACU_PEPSAPUCfg 1;
BA_ "GenSigSendType" SG_ 3221225472 ACU_PEPSAPUCfg 1;
BA_ "Remark" SG_ 3221225472 ACU_PEPSWALCfg "";
BA_ "EventCommandSignal" SG_ 3221225472 ACU_PEPSWALCfg 1;
BA_ "GenSigSendType" SG_ 3221225472 ACU_PEPSWALCfg 1;
BA_ "Remark" SG_ 3221225472 ACU_ICMLanguageCfg "";
BA_ "EventCommandSignal" SG_ 3221225472 ACU_ICMLanguageCfg 1;
BA_ "GenSigSendType" SG_ 3221225472 ACU_ICMLanguageCfg 1;
BA_ "Remark" SG_ 3221225472 ACU_ICMTimeModeCfg "";
BA_ "EventCommandSignal" SG_ 3221225472 ACU_ICMTimeModeCfg 1;
BA_ "GenSigSendType" SG_ 3221225472 ACU_ICMTimeModeCfg 1;
BA_ "Remark" SG_ 3221225472 ACU_ICMWarnSoundVolCfg "";
BA_ "EventCommandSignal" SG_ 3221225472 ACU_ICMWarnSoundVolCfg 1;
BA_ "GenSigSendType" SG_ 3221225472 ACU_ICMWarnSoundVolCfg 1;
BA_ "Remark" SG_ 3221225472 ACU_ICMSpdWarnCfg "";
BA_ "EventCommandSignal" SG_ 3221225472 ACU_ICMSpdWarnCfg 1;
BA_ "GenSigSendType" SG_ 3221225472 ACU_ICMSpdWarnCfg 1;
BA_ "GenSigStartValue" SG_ 3221225472 ACU_ICMSpdWarnCfg 31;
BA_ "Remark" SG_ 3221225472 ACU_PEPSSATOCfg "";
BA_ "EventCommandSignal" SG_ 3221225472 ACU_PEPSSATOCfg 1;
BA_ "GenSigSendType" SG_ 3221225472 ACU_PEPSSATOCfg 1;
BA_ "Remark" SG_ 3221225472 ACU_PEPSWELCfg "";
BA_ "EventCommandSignal" SG_ 3221225472 ACU_PEPSWELCfg 1;
BA_ "GenSigSendType" SG_ 3221225472 ACU_PEPSWELCfg 1;
BA_ "Remark" SG_ 3221225472 ACU_BCMOSRMAutoFoldCfg "";
BA_ "EventCommandSignal" SG_ 3221225472 ACU_BCMOSRMAutoFoldCfg 1;
BA_ "GenSigSendType" SG_ 3221225472 ACU_BCMOSRMAutoFoldCfg 1;
BA_ "Remark" SG_ 3221225472 ACU_MSMKeyRecognitionCfg "";
BA_ "EventCommandSignal" SG_ 3221225472 ACU_MSMKeyRecognitionCfg 1;
BA_ "GenSigSendType" SG_ 3221225472 ACU_MSMKeyRecognitionCfg 1;
BA_ "Remark" SG_ 3221225472 ACU_MSMWelcomeFuncCfg "";
BA_ "EventCommandSignal" SG_ 3221225472 ACU_MSMWelcomeFuncCfg 1;
BA_ "GenSigSendType" SG_ 3221225472 ACU_MSMWelcomeFuncCfg 1;
BA_ "Remark" SG_ 3221225472 ACU_HVACFComfortCfg "";
BA_ "EventCommandSignal" SG_ 3221225472 ACU_HVACFComfortCfg 1;
BA_ "GenSigSendType" SG_ 3221225472 ACU_HVACFComfortCfg 1;
BA_ "Remark" SG_ 3221225472 ACU_HVACFAirCirCfg "";
BA_ "EventCommandSignal" SG_ 3221225472 ACU_HVACFAirCirCfg 1;
BA_ "GenSigSendType" SG_ 3221225472 ACU_HVACFAirCirCfg 1;
BA_ "Remark" SG_ 3221225472 ACU_HVACFACCfg "";
BA_ "EventCommandSignal" SG_ 3221225472 ACU_HVACFACCfg 1;
BA_ "GenSigSendType" SG_ 3221225472 ACU_HVACFACCfg 1;
BA_ "Remark" SG_ 3221225472 ACU_LDW_WarnSnsCfg "";
BA_ "EventCommandSignal" SG_ 3221225472 ACU_LDW_WarnSnsCfg 1;
BA_ "GenSigSendType" SG_ 3221225472 ACU_LDW_WarnSnsCfg 1;
BA_ "Remark" SG_ 3221225472 TEL_BTAvrcpPlayMode "";
BA_ "GenSigSendType" SG_ 3221225472 TEL_BTAvrcpPlayMode 1;
BA_ "GenSigStartValue" SG_ 3221225472 TEL_BTAvrcpPlayMode 3;
BA_ "Remark" SG_ 3221225472 TEL_TelematicsRegisterSt "";
BA_ "GenSigSendType" SG_ 3221225472 TEL_TelematicsRegisterSt 1;
BA_ "Remark" SG_ 3221225472 TEL_BTAutoconectingSt "";
BA_ "GenSigSendType" SG_ 3221225472 TEL_BTAutoconectingSt 1;
BA_ "Remark" SG_ 3221225472 TEL_BTPowerSt "";
BA_ "GenSigSendType" SG_ 3221225472 TEL_BTPowerSt 1;
BA_ "Remark" SG_ 3221225472 TEL_BTManualMode "";
BA_ "GenSigSendType" SG_ 3221225472 TEL_BTManualMode 1;
BA_ "Remark" SG_ 3221225472 TEL_BTHisdel "";
BA_ "GenSigSendType" SG_ 3221225472 TEL_BTHisdel 1;
BA_ "Remark" SG_ 3221225472 TEL_BTHandfreeSt "";
BA_ "GenSigSendType" SG_ 3221225472 TEL_BTHandfreeSt 1;
BA_ "Remark" SG_ 3221225472 TEL_BTAvrcpSt "";
BA_ "GenSigSendType" SG_ 3221225472 TEL_BTAvrcpSt 1;
BA_ "Remark" SG_ 3221225472 TEL_TelematicsModeActSt "";
BA_ "GenSigSendType" SG_ 3221225472 TEL_TelematicsModeActSt 1;
BA_ "Remark" SG_ 3221225472 ACU_EVSwRq "";
BA_ "EventCommandSignal" SG_ 3221225472 ACU_EVSwRq 1;
BA_ "Remark" SG_ 3221225472 BCS_2_Checksum "";
BA_ "GenSigSendType" SG_ 3221225472 BCS_2_Checksum 1;
BA_ "Remark" SG_ 3221225472 BCS_2_MsgCounter "";
BA_ "GenSigSendType" SG_ 3221225472 BCS_2_MsgCounter 1;
BA_ "Remark" SG_ 3221225472 BCM_BCAN_2_Checksum "";
BA_ "GatewayedSignals" SG_ 3221225472 BCM_BCAN_2_Checksum 1;
BA_ "GenSigSendType" SG_ 3221225472 BCM_BCAN_2_Checksum 1;
BA_ "GenSigStartValue" SG_ 3221225472 BCM_BCAN_2_Checksum 126;
BA_ "Remark" SG_ 3221225472 BCM_BCAN_2_MsgCounter "";
BA_ "GatewayedSignals" SG_ 3221225472 BCM_BCAN_2_MsgCounter 1;
BA_ "GenSigSendType" SG_ 3221225472 BCM_BCAN_2_MsgCounter 1;
BA_ "Remark" SG_ 3221225472 ADAS_HWA_ILCWaitReasonLeft "";
BA_ "GenSigSendType" SG_ 3221225472 ADAS_HWA_ILCWaitReasonLeft 1;
BA_ "Remark" SG_ 3221225472 ADAS_HWA_ILCWaitReasonRight "";
BA_ "GatewayedSignals" SG_ 3221225472 ADAS_HWA_ILCWaitReasonRight 1;
BA_ "GenSigSendType" SG_ 3221225472 ADAS_HWA_ILCWaitReasonRight 1;
BA_ "Remark" SG_ 3221225472 PAS_Mode "";
BA_ "GenSigSendType" SG_ 3221225472 PAS_Mode 1;
BA_ "Remark" SG_ 3221225472 ICM_SetPedalLevelUp "";
BA_ "GenSigSendType" SG_ 3221225472 ICM_SetPedalLevelUp 1;
BA_ "Remark" SG_ 3221225472 ICM_SetPedalLevelDown "";
BA_ "GenSigSendType" SG_ 3221225472 ICM_SetPedalLevelDown 1;
BA_ "Remark" SG_ 3221225472 ACU_IFC_ZoneCode "";
BA_ "EventCommandSignal" SG_ 3221225472 ACU_IFC_ZoneCode 1;
BA_ "GenSigSendType" SG_ 3221225472 ACU_IFC_ZoneCode 1;
BA_ "Remark" SG_ 3221225472 ACU_IFC_SpeedLimitUnit "";
BA_ "EventCommandSignal" SG_ 3221225472 ACU_IFC_SpeedLimitUnit 1;
BA_ "GenSigSendType" SG_ 3221225472 ACU_IFC_SpeedLimitUnit 1;
BA_ "Remark" SG_ 3221225472 ACU_IFC_SpeedLimit "";
BA_ "EventCommandSignal" SG_ 3221225472 ACU_IFC_SpeedLimit 1;
BA_ "GenSigSendType" SG_ 3221225472 ACU_IFC_SpeedLimit 1;
BA_ "Remark" SG_ 3221225472 ACU_IFC_RoadType "";
BA_ "EventCommandSignal" SG_ 3221225472 ACU_IFC_RoadType 1;
BA_ "GenSigSendType" SG_ 3221225472 ACU_IFC_RoadType 1;
BA_ "GenSigTimeoutValue" SG_ 3221225472 SRS_1_Checksum 255;
BA_ "Remark" SG_ 3221225472 SRS_1_Checksum "";
BA_ "GenSigSendType" SG_ 3221225472 SRS_1_Checksum 1;
BA_ "Remark" SG_ 3221225472 SRS_1_MsgCounter "";
BA_ "GenSigSendType" SG_ 3221225472 SRS_1_MsgCounter 1;
BA_ "Remark" SG_ 3221225472 ICM_TripB "";
BA_ "GenSigSendType" SG_ 3221225472 ICM_TripB 1;
BA_ "Remark" SG_ 3221225472 ICM_TripBVD "";
BA_ "GenSigSendType" SG_ 3221225472 ICM_TripBVD 1;
BA_ "Remark" SG_ 3221225472 ICM_TripA "";
BA_ "GenSigSendType" SG_ 3221225472 ICM_TripA 1;
BA_ "Remark" SG_ 3221225472 ICM_TripAVD "";
BA_ "GenSigSendType" SG_ 3221225472 ICM_TripAVD 1;
BA_ "Remark" SG_ 3221225472 ICM_VehAverageSpd "";
BA_ "GenSigSendType" SG_ 3221225472 ICM_VehAverageSpd 1;
BA_ "GenSigInvalidValue" SG_ 3221225472 ICM_VehAverageSpd 255;
BA_ "GenSigSendType" SG_ 3221225472 VCU_AGSErr 1;
BA_ "GenSigStartValue" SG_ 538 VCU_FilVehLalAccel 320;
BA_ "GenSigStartValue" SG_ 538 VCU_RollAngle 16;
BA_ "GenSigStartValue" SG_ 538 VCU_RoadGrade 16;
BA_ "GenSigStartValue" SG_ 538 VCU_PitchAngle 24;
BA_ "GenSigStartValue" SG_ 538 VCU_FrontWheelAngle 104;
BA_ "GenSigStartValue" SG_ 538 VCU_AvdcMode 1;
BA_ "GenSigStartValue" SG_ 538 VCU_FilVehLongAccel 320.512820512821;
BA_ "GatewayedSignals" SG_ 880 VCU_GasPedalActPstforMRR 1;
BA_ "GenSigSendType" SG_ 880 VCU_GasPedalActPstforMRR 1;
BA_ "GatewayedSignals" SG_ 880 VCU_GasPedalActPstforMRRVD 1;
BA_ "GenSigSendType" SG_ 880 VCU_GasPedalActPstforMRRVD 1;
BA_ "GenSigSendType" SG_ 924 IPS_OBCCC_St 1;
BA_ "GenSigInvalidValue" SG_ 520 SRS_YawRate 36001;
BA_ "GenSigTimeoutValue" SG_ 520 SRS_YawRate 18000;
BA_ "GenSigSendType" SG_ 520 SRS_YawRate 1;
BA_ "GenSigStartValue" SG_ 520 SRS_YawRate 18000;
BA_ "GenSigInvalidValue" SG_ 520 SRS_VehLatrlAccel 4001;
BA_ "GenSigTimeoutValue" SG_ 520 SRS_VehLatrlAccel 2000;
BA_ "GenSigSendType" SG_ 520 SRS_VehLatrlAccel 1;
BA_ "GenSigStartValue" SG_ 520 SRS_VehLatrlAccel 2000;
BA_ "GenSigInvalidValue" SG_ 520 SRS_VehLongAccel 4001;
BA_ "GenSigTimeoutValue" SG_ 520 SRS_VehLongAccel 2000;
BA_ "GenSigSendType" SG_ 520 SRS_VehLongAccel 1;
BA_ "GenSigStartValue" SG_ 520 SRS_VehLongAccel 2000;
BA_ "GenSigTimeoutValue" SG_ 520 SRS_YawRateVD 2;
BA_ "GenSigStartValue" SG_ 520 SRS_YawRateVD 2;
BA_ "GenSigSendType" SG_ 520 SRS_YawRateVD 1;
BA_ "GenSigTimeoutValue" SG_ 520 SRS_VehLatrlAccelVD 2;
BA_ "GenSigStartValue" SG_ 520 SRS_VehLatrlAccelVD 2;
BA_ "GenSigSendType" SG_ 520 SRS_VehLatrlAccelVD 1;
BA_ "GenSigTimeoutValue" SG_ 520 SRS_VehLongAccelVD 2;
BA_ "GenSigStartValue" SG_ 520 SRS_VehLongAccelVD 2;
BA_ "GenSigSendType" SG_ 520 SRS_VehLongAccelVD 1;
BA_ "GenSigSendType" SG_ 520 SRS_YawSnsCalibSt 1;
BA_ "GenSigStartValue" SG_ 1536 EMS_FrontWheelAngle 64;
BA_ "GenSigTimeoutValue" SG_ 1536 EMS_FrontWheelAngle 64;
BA_ "GenSigSendType" SG_ 1536 EMS_FrontWheelAngle 1;
BA_ "GenSigSendType" SG_ 1536 EMS_BrakeDepth 1;
BA_ "GenSigStartValue" SG_ 1567 RLS_RainfallLevel 14;
BA_ "GenSigSendType" SG_ 412 IFC_AssistParaSwitchReq 1;
BA_ "GenSigSendType" SG_ 627 TEL_ACU_GNSSclletAuthorStartMon 1;
BA_ "GenSigSendType" SG_ 627 TEL_ACU_GNSSclletAuthorStartDay 1;
BA_ "GenSigSendType" SG_ 627 TEL_ACU_GNSSclletAuthorStopMon 1;
BA_ "GenSigSendType" SG_ 627 TEL_ACU_GNSSclletAuthorStopDay 1;
BA_ "GenSigSendType" SG_ 627 TEL_ACU_GNSSclletAuthorStartYear 1;
BA_ "GenSigSendType" SG_ 627 TEL_ACU_GNSSclletAuthorStopYear 1;
BA_ "GenSigSendType" SG_ 627 TEL_ACU_GNSSclletAuthorMode 1;
BA_ "GenSigSendType" SG_ 627 Reserved 1;
BA_ "GenSigSendType" SG_ 627 TEL_GNSSAPPTypeSt 1;
BA_ "GenSigTimeoutValue" SG_ 886 BCS_HDCFuncResp 2;
BA_ "GenSigInvalidValue" SG_ 886 BCS_HDCFuncResp 2;
BA_ "GenSigSendType" SG_ 886 BCS_HDCFuncResp 1;
BA_ "GenSigTimeoutValue" SG_ 886 BCS_ESPFuncResp 3;
BA_ "GenSigInvalidValue" SG_ 886 BCS_ESPFuncResp 3;
BA_ "GatewayedSignals" SG_ 886 BCS_ESPFuncResp 1;
BA_ "GenSigSendType" SG_ 886 BCS_ESPFuncResp 1;
BA_ "EventCommandSignal" SG_ 179 APA_VoiceReminder 1;
BA_ "GenSigSendType" SG_ 837 PCS_MirrorPageDownButton 1;
BA_ "GenSigSendType" SG_ 837 PCS_ER_QuitReq 1;
BA_ "GenSigSendType" SG_ 837 PCS_ER_EnterConfirm 1;
BA_ "GenSigSendType" SG_ 837 PCS_ACU_DisplayReq 1;
BA_ "GenSigSendType" SG_ 837 PCS_SoundReminderSt 1;
BA_ "GenSigSendType" SG_ 837 PCS_HelpMenuSt 1;
BA_ "GenSigSendType" SG_ 837 PCS_ReturnSt 1;
BA_ "GenSigSendType" SG_ 837 PCS_RightBlindSpotViewSt 1;
BA_ "GenSigSendType" SG_ 837 PCS_LeftBlindSpotViewSt 1;
BA_ "GenSigSendType" SG_ 837 PCS_RVMButtonGroup 1;
BA_ "GenSigSendType" SG_ 837 PCS_OperationSt 1;
BA_ "GenSigSendType" SG_ 837 PCS_3DEnalbe 1;
BA_ "GenSigSendType" SG_ 837 PCS_MODEnalbe 1;
BA_ "GenSigSendType" SG_ 837 PCS_PASButtonPress 1;
BA_ "GenSigSendType" SG_ 837 PCS_SteerIconInd 1;
BA_ "GenSigSendType" SG_ 837 PCS_SteerWheelTurnDirInd 1;
BA_ "GenSigSendType" SG_ 837 PCS_GuidOverlaySt 1;
BA_ "GenSigSendType" SG_ 837 PCS_DriveDirInd 1;
BA_ "GenSigSendType" SG_ 837 PCS_SystemType 1;
BA_ "GenSigSendType" SG_ 837 PCS_VoiceReq 1;
BA_ "GenSigSendType" SG_ 837 PCS_SingleViewInd 1;
BA_ "GenSigSendType" SG_ 837 PCS_HMIIndex 1;
BA_ "GenSigSendType" SG_ 837 PCS_EventRecordSt 1;
BA_ "GenSigSendType" SG_ 837 PCS_CalibrateSt 1;
BA_ "GenSigSendType" SG_ 837 PCS_VRSwitchFailSt 1;
BA_ "GenSigSendType" SG_ 837 PCS_SystemSt 1;
BA_ "GenSigSendType" SG_ 898 BMS_BattSOE 1;
BA_ "GenSigSendType" SG_ 1126 VMM_NMDataField 1;
BA_ "GenSigSendType" SG_ 1126 VMM_NMWakeupOrignin 1;
BA_ "GenSigSendType" SG_ 1126 VMM_NMSleepAck 1;
BA_ "GenSigSendType" SG_ 1126 VMM_NMSleepInd 1;
BA_ "GenSigSendType" SG_ 1126 VMM_NMLimpHome 1;
BA_ "GenSigSendType" SG_ 1126 VMM_NMRing 1;
BA_ "GenSigSendType" SG_ 1126 VMM_NMAlive 1;
BA_ "GenSigSendType" SG_ 1126 VMM_NMDestAddress 1;
BA_ "EventCommandSignal" SG_ 34 VMM_FailtureReasonSt 1;
BA_ "GenSigSendType" SG_ 869 VMM_Crash_Flg 1;
BA_ "GenSigSendType" SG_ 869 VMM_SysCfgst 1;
BA_ "GenSigSendType" SG_ 869 VMM_WarningTpyCfgst 1;
BA_ "GenSigSendType" SG_ 869 VMM_SnsCfgSt 1;
BA_ "GenSigSendType" SG_ 869 VMM_WarningType 1;
BA_ "GenSigSendType" SG_ 1081 FAPA_NMWakeupOrigin 1;
BA_ "GenSigSendType" SG_ 1081 FAPA_NMSleepAck 1;
BA_ "GenSigSendType" SG_ 1081 FAPA_NMSleepInd 1;
BA_ "GenSigSendType" SG_ 1081 FAPA_NMLimpHome 1;
BA_ "GenSigSendType" SG_ 1081 FAPA_NMRing 1;
BA_ "GenSigSendType" SG_ 1081 FAPA_NMAlive 1;
BA_ "GenSigSendType" SG_ 1081 FAPA_NMDestAddress 1;
BA_ "GenSigSendType" SG_ 1105 IMR_NMWakeupOrigin 1;
BA_ "GenSigSendType" SG_ 1105 IMR_NMSleepAck 1;
BA_ "GenSigSendType" SG_ 1105 IMR_NMSleepInd 1;
BA_ "GenSigSendType" SG_ 1105 IMR_NMLimpHome 1;
BA_ "GenSigSendType" SG_ 1105 IMR_NMRing 1;
BA_ "GenSigSendType" SG_ 1105 IMR_NMAlive 1;
BA_ "GenSigSendType" SG_ 1105 IMR_NMDestAddress 1;
BA_ "GenSigSendType" SG_ 648 BCS_BrakeFluid_Warning 1;
BA_ "GenSigSendType" SG_ 648 BCS_CST_Status 1;
BA_ "GenSigSendType" SG_ 648 BCS_TwoFoot_DriveWarning 1;
BA_ "GenSigSendType" SG_ 648 BCS_System_Status 1;
BA_ "GenSigSendType" SG_ 648 BCS_FWA_warning 1;
BA_ "GenSigSendType" SG_ 1617 ICM_TC_Reverse1 1;
BA_ "GenSigSendType" SG_ 1617 ICM_DTERAFE 1;
BA_ "GenSigSendType" SG_ 1617 ICM_bLowFuelTTState 1;
BA_ "GenSigSendType" SG_ 1617 ICM_VolStopSave 1;
BA_ "GenSigSendType" SG_ 1617 ICM_VolStopDisplaySave 1;
BA_ "GenSigSendType" SG_ 1617 ICM_FuelLineType 1;
BA_ "GenSigSendType" SG_ 1617 ICM_bSensorPortCOpenload 1;
BA_ "GenSigSendType" SG_ 1617 ICM_bSensorPortAOpenload 1;
BA_ "GenSigSendType" SG_ 1617 ICM_bSensorErrStuck 1;
BA_ "GenSigSendType" SG_ 1617 ICM_bSensorErrLeak 1;
BA_ "GenSigSendType" SG_ 1617 ICM_bRunningModeEvent 1;
BA_ "GenSigSendType" SG_ 1616 ICM_VehicleState 1;
BA_ "GenSigSendType" SG_ 1616 ICM_RsampValue_1st 1;
BA_ "GenSigSendType" SG_ 1616 ICM_RrfcValue 1;
BA_ "GenSigSendType" SG_ 1616 ICM_RavgValue 1;
BA_ "GenSigSendType" SG_ 1616 ICM_FuelState 1;
BA_ "GenSigSendType" SG_ 1616 ICM_DampingType 1;
BA_ "GenSigSendType" SG_ 1616 ICM_bRefillingEventC 1;
BA_ "GenSigSendType" SG_ 1616 ICM_bRefillingEventB 1;
BA_ "GenSigSendType" SG_ 1616 ICM_bRefillingEventA 1;
BA_ "GenSigSendType" SG_ 1733 ICM_DTECalVal 1;
BA_ "GenSigSendType" SG_ 1733 ICM_VolOfDisplay 1;
BA_ "GenSigSendType" SG_ 1733 ICM_VolOfCycleResult 1;
BA_ "GenSigSendType" SG_ 1733 ICM_VolOfAvgResult 1;
BA_ "GenSigSendType" SG_ 1734 ICM_TC_Reverse2 1;
BA_ "GenSigSendType" SG_ 1734 ICM_FuelPulse 1;
BA_ "GenSigSendType" SG_ 1734 ICM_DTEDispVal 1;
BA_ "GenSigSendType" SG_ 1005 not_used 1;
BA_ "GenSigSendType" SG_ 1005 TEL_BookChrgStartRemainingMin 1;
BA_ "GenSigInvalidValue" SG_ 1005 TEL_BookChrgStartRemainingMin 60;
BA_ "GenSigSendType" SG_ 1005 TEL_BookChrgStartRemainingHour 1;
BA_ "GenSigInvalidValue" SG_ 1005 TEL_BookChrgStartRemainingHour 24;
BA_ "GenSigSendType" SG_ 1005 TEL_BookChrgStartRemainingDay 1;
BA_ "GenSigInvalidValue" SG_ 1005 TEL_BookChrgStartRemainingDay 7;
BA_ "GenSigSendType" SG_ 1004 TBOX_ACU_BookChrgStopYear 1;
BA_ "GenSigSendType" SG_ 1004 TBOX_ACU_BookChrgStartYear 1;
BA_ "GenSigSendType" SG_ 1004 TBOX_ACU_RepeatBookChrgDay7 1;
BA_ "GenSigSendType" SG_ 1004 TBOX_ACU_RepeatBookChrgDay6 1;
BA_ "GenSigSendType" SG_ 1004 TBOX_ACU_RepeatBookChrgDay5 1;
BA_ "GenSigSendType" SG_ 1004 TBOX_ACU_RepeatBookChrgDay4 1;
BA_ "GenSigSendType" SG_ 1004 TBOX_ACU_RepeatBookChrgDay3 1;
BA_ "GenSigSendType" SG_ 1004 TBOX_ACU_RepeatBookChrgDay2 1;
BA_ "GenSigSendType" SG_ 1004 TBOX_ACU_RepeatBookChrgDay1 1;
BA_ "GenSigSendType" SG_ 1004 TBOX_ACU_BookChrgMode 1;
BA_ "GenSigSendType" SG_ 1004 TBOX_ACU_BookChrgStopMin 1;
BA_ "GenSigSendType" SG_ 1004 TBOX_ACU_BookChrgStopHour 1;
BA_ "GenSigSendType" SG_ 1004 TBOX_ACU_BookChrgStopDay 1;
BA_ "GenSigSendType" SG_ 1004 TBOX_ACU_BookChrgStopMon 1;
BA_ "GenSigSendType" SG_ 1004 TBOX_ACU_BookChrgStartMin 1;
BA_ "GenSigSendType" SG_ 1004 TBOX_ACU_BookChrgStartHour 1;
BA_ "GenSigSendType" SG_ 1004 TBOX_ACU_BookChrgStartDay 1;
BA_ "GenSigSendType" SG_ 1004 TBOX_ACU_BookChrgStartMon 1;
BA_ "GenSigInvalidValue" SG_ 74 ACU_TBOX_BookChrgStoptMin 60;
BA_ "GenSigInvalidValue" SG_ 74 ACU_TBOX_BookChrgStartHour 24;
BA_ "GenSigInvalidValue" SG_ 74 ACU_TBOX_BookChrgStopHour 24;
BA_ "GenSigInvalidValue" SG_ 74 ACU_TBOX_BookChrgStartMin 60;
BA_ "GenSigSendType" SG_ 832 EMS_GasPedalActPstVD 1;
BA_ "GenSigSendType" SG_ 832 EMS_GasPedalActPst 1;
BA_ "GenSigSendType" SG_ 832 EMS_FuleCapAjarSt 1;
BA_ "GenSigSendType" SG_ 832 EMS_FuelPressureReleaseStDis 1;
BA_ "GenSigInvalidValue" SG_ 927 VCU_VehElcConspAvg 511;
BA_ "GenSigStartValue" SG_ 927 VCU_VehElcConspAvg 255;
BA_ "GenSigTimeoutValue" SG_ 927 VCU_VehElcConspAvg 511;
BA_ "GenSigSendType" SG_ 927 VCU_VehElcConspAvg 1;
BA_ "GenSigSendType" SG_ 927 VCU_WarmTimeCfgResp 1;
BA_ "GenSigSendType" SG_ 927 VCU_WarmSt 1;
BA_ "GatewayedSignals" SG_ 927 VCU_VehPwr 1;
BA_ "GenSigTimeoutValue" SG_ 927 VCU_VehPwr 100;
BA_ "GenSigStartValue" SG_ 927 VCU_VehPwr 100;
BA_ "GenSigInvalidValue" SG_ 927 VCU_VehPwr 255;
BA_ "GenSigSendType" SG_ 927 VCU_VehPwr 1;
BA_ "GatewayedSignals" SG_ 927 VCU_EVRngUndrWarn 1;
BA_ "GenSigSendType" SG_ 927 VCU_EVRngUndrWarn 1;
BA_ "GatewayedSignals" SG_ 927 VCU_BattSocUndrWarn 1;
BA_ "GenSigSendType" SG_ 927 VCU_BattSocUndrWarn 1;
BA_ "GatewayedSignals" SG_ 927 VCU_EVRng 1;
BA_ "GenSigSendType" SG_ 927 VCU_EVRng 1;
BA_ "GenSigStartValue" SG_ 927 VCU_EVRng 510;
BA_ "GenSigInvalidValue" SG_ 927 VCU_EVRng 511;
BA_ "GatewayedSignals" SG_ 927 VCU_HVACPwrLimitAct 1;
BA_ "GenSigSendType" SG_ 927 VCU_HVACPwrLimitAct 1;
BA_ "GatewayedSignals" SG_ 927 VCU_RecpLevelstResp 1;
BA_ "GenSigSendType" SG_ 927 VCU_RecpLevelstResp 1;
BA_ "GatewayedSignals" SG_ 927 VCU_HVACPwrLimit 1;
BA_ "GenSigInvalidValue" SG_ 927 VCU_HVACPwrLimit 63;
BA_ "GenSigSendType" SG_ 927 VCU_HVACPwrLimit 1;
BA_ "GenSigSendType" SG_ 912 VCU_VehDrvModNew 1;
BA_ "GenSigSendType" SG_ 912 VCU_PedalMapSt 1;
BA_ "GenSigSendType" SG_ 912 VCU_ICM_ClntFillingFault 1;
BA_ "GenSigSendType" SG_ 912 VCU_DrvChgDchgDsp 1;
BA_ "GenSigSendType" SG_ 779 VCU_DerateFault 1;
BA_ "GenSigSendType" SG_ 779 VCU_SysFault 1;
BA_ "GenSigSendType" SG_ 995 BMS_LvPwrSysMsgWarn 1;
BA_ "GenSigSendType" SG_ 995 BMS_ThermalRunawayErr 1;
BA_ "GenSigSendType" SG_ 995 BMS_TempUndInd 1;
BA_ "GenSigSendType" SG_ 995 BMS_TempOvrInd 1;
BA_ "GenSigSendType" SG_ 995 GCU_FaultLampInd 1;
BA_ "GenSigSendType" SG_ 995 GCU_SysTempOvrInd 1;
BA_ "GenSigSendType" SG_ 995 DCU_FaultLampInd 1;
BA_ "GenSigSendType" SG_ 995 DCU_SysTempOvrInd 1;
BA_ "GenSigSendType" SG_ 995 BMS_ChgComplRemMinute 1;
BA_ "GenSigSendType" SG_ 995 IPS_DCDCFaultLampInd 1;
BA_ "GenSigSendType" SG_ 995 IPS_OBCFaultLampInd 1;
BA_ "GenSigSendType" SG_ 995 BMS_FaultLampInd 1;
BA_ "GenSigSendType" SG_ 995 BMS_ChgComplRemHour 1;
BA_ "GenSigSendType" SG_ 811 VCU_DischgSetInfo 1;
BA_ "GatewayedSignals" SG_ 811 VCU_DischgSetInfo 1;
BA_ "GenSigSendType" SG_ 811 VCU_ChgSetInfo 1;
BA_ "GatewayedSignals" SG_ 811 VCU_ChgSetInfo 1;
BA_ "GenSigSendType" SG_ 811 VCU_VehChgDischgSt 1;
BA_ "GatewayedSignals" SG_ 811 VCU_VehChgDischgSt 1;
BA_ "GatewayedSignals" SG_ 907 VCU_EngSelfMaintDisp 1;
BA_ "GenSigSendType" SG_ 907 VCU_EngSelfMaintDisp 1;
BA_ "GatewayedSignals" SG_ 907 VCU_EngForbidDisp 1;
BA_ "GenSigSendType" SG_ 907 VCU_EngForbidDisp 1;
BA_ "GatewayedSignals" SG_ 907 VCU_GearLvlBlink 1;
BA_ "GenSigSendType" SG_ 907 VCU_GearLvlBlink 1;
BA_ "GatewayedSignals" SG_ 907 VCU_CCUFaultLampInd 1;
BA_ "GenSigSendType" SG_ 907 VCU_CCUFaultLampInd 1;
BA_ "GatewayedSignals" SG_ 907 VCU_OilPresUndrWarn 1;
BA_ "GenSigSendType" SG_ 907 VCU_OilPresUndrWarn 1;
BA_ "GatewayedSignals" SG_ 907 VCU_EngFuelLow 1;
BA_ "GenSigSendType" SG_ 907 VCU_EngFuelLow 1;
BA_ "GatewayedSignals" SG_ 907 VCU_Released 1;
BA_ "GenSigSendType" SG_ 907 VCU_Released 1;
BA_ "GatewayedSignals" SG_ 907 VCU_DriverNoticeDisp 1;
BA_ "GenSigSendType" SG_ 907 VCU_DriverNoticeDisp 1;
BA_ "GatewayedSignals" SG_ 907 VCU_GearLvlDisp 1;
BA_ "GenSigSendType" SG_ 907 VCU_GearLvlDisp 1;
BA_ "GatewayedSignals" SG_ 907 VCU_VehElcConspInst 1;
BA_ "GenSigTimeoutValue" SG_ 907 VCU_VehElcConspInst 511;
BA_ "GenSigInvalidValue" SG_ 907 VCU_VehElcConspInst 511;
BA_ "GenSigSendType" SG_ 907 VCU_VehElcConspInst 1;
BA_ "GatewayedSignals" SG_ 907 VCU_SysFaultLampInd 1;
BA_ "GenSigSendType" SG_ 907 VCU_SysFaultLampInd 1;
BA_ "GatewayedSignals" SG_ 907 VCU_VehCrusTgtSpd 1;
BA_ "GenSigInvalidValue" SG_ 907 VCU_VehCrusTgtSpd 255;
BA_ "GenSigSendType" SG_ 907 VCU_VehCrusTgtSpd 1;
BA_ "GenSigStartValue" SG_ 907 VCU_VehElcConspAccumAvg 255;
BA_ "GatewayedSignals" SG_ 907 VCU_VehElcConspAccumAvg 1;
BA_ "GenSigTimeoutValue" SG_ 907 VCU_VehElcConspAccumAvg 511;
BA_ "GenSigInvalidValue" SG_ 907 VCU_VehElcConspAccumAvg 511;
BA_ "GenSigSendType" SG_ 907 VCU_VehElcConspAccumAvg 1;
BA_ "GatewayedSignals" SG_ 907 VCU_VehElcConspAvg 1;
BA_ "GenSigTimeoutValue" SG_ 907 VCU_VehElcConspAvg 511;
BA_ "GenSigInvalidValue" SG_ 907 VCU_VehElcConspAvg 511;
BA_ "GenSigSendType" SG_ 907 VCU_VehElcConspAvg 1;
BA_ "GatewayedSignals" SG_ 907 VCU_WarmSt 1;
BA_ "GenSigSendType" SG_ 907 VCU_WarmSt 1;
BA_ "GatewayedSignals" SG_ 907 VCU_WarmTimeCfgResp 1;
BA_ "GenSigSendType" SG_ 907 VCU_WarmTimeCfgResp 1;
BA_ "GenSigSendType" SG_ 848 VCU_PrecResHotMsg 1;
BA_ "GenSigSendType" SG_ 848 VCU_ChgTimeDspType 1;
BA_ "GenSigSendType" SG_ 848 VCU_PlgConnSt 1;
BA_ "GenSigSendType" SG_ 848 VCU_EVPRepair 1;
BA_ "GenSigSendType" SG_ 848 VCU_ARBWarnNotice 1;
BA_ "GatewayedSignals" SG_ 848 VCU_EVButtonNoticeDisp 1;
BA_ "GenSigSendType" SG_ 848 VCU_EVButtonNoticeDisp 1;
BA_ "GatewayedSignals" SG_ 848 VCU_PGearErrNotice 1;
BA_ "GenSigSendType" SG_ 848 VCU_PGearErrNotice 1;
BA_ "GatewayedSignals" SG_ 848 VCU_BuzReq 1;
BA_ "GenSigSendType" SG_ 848 VCU_BuzReq 1;
BA_ "GenSigSendType" SG_ 848 VCU_DerateLampSt 1;
BA_ "GenSigTimeoutValue" SG_ 848 VCU_EVSt 1;
BA_ "GenSigSendType" SG_ 848 VCU_EVSt 1;
BA_ "GatewayedSignals" SG_ 848 VCU_VehAvailDriveStMsgWarn 1;
BA_ "GenSigSendType" SG_ 848 VCU_VehAvailDriveStMsgWarn 1;
BA_ "GatewayedSignals" SG_ 848 VCU_ThermalMsgWarn 1;
BA_ "GenSigSendType" SG_ 848 VCU_ThermalMsgWarn 1;
BA_ "GatewayedSignals" SG_ 848 VCU_VehRdySt_Rddy 1;
BA_ "GenSigTimeoutValue" SG_ 848 VCU_VehRdySt_Rddy 1;
BA_ "GenSigSendType" SG_ 848 VCU_VehRdySt_Rddy 1;
BA_ "GatewayedSignals" SG_ 848 VCU_VehRdySt 1;
BA_ "GenSigSendType" SG_ 848 VCU_VehRdySt 1;
BA_ "GatewayedSignals" SG_ 848 VCU_ElcVcuuPumpErr 1;
BA_ "GenSigSendType" SG_ 848 VCU_ElcVcuuPumpErr 1;
BA_ "GatewayedSignals" SG_ 848 VCU_FaultLampInd 1;
BA_ "GenSigSendType" SG_ 848 VCU_FaultLampInd 1;
BA_ "GenSigTimeoutValue" SG_ 848 VCU_FaultLampInd 1;
BA_ "GatewayedSignals" SG_ 848 VCU_VehCrusSt 1;
BA_ "GenSigSendType" SG_ 848 VCU_VehCrusSt 1;
BA_ "GatewayedSignals" SG_ 848 VCU_ElcSysFault 1;
BA_ "GenSigSendType" SG_ 848 VCU_ElcSysFault 1;
BA_ "GenSigSendType" SG_ 848 VCU_OperatingMode 1;
BA_ "GenSigInvalidValue" SG_ 848 VCU_BMS_BattSocDisp 255;
BA_ "GenSigSendType" SG_ 848 VCU_BMS_BattSocDisp 1;
BA_ "GatewayedSignals" SG_ 848 VCU_VehDrvMod 1;
BA_ "GenSigSendType" SG_ 848 VCU_VehDrvMod 1;
BA_ "GenSigSendType" SG_ 848 VCU_PwrFlowMode 1;
BA_ "GenSigSendType" SG_ 908 VCU_SmartCommutDriveStResp 1;
BA_ "GenSigSendType" SG_ 908 VCU_SmartNaviDriveStResp 1;
BA_ "GenSigSendType" SG_ 908 VCU_SmartNaviChrgHeatStResp 1;
BA_ "GatewayedSignals" SG_ 908 VCU_BookChgLampInd 1;
BA_ "GenSigSendType" SG_ 908 VCU_BookChgLampInd 1;
BA_ "GenSigSendType" SG_ 908 VCU_DspDischgCurr 1;
BA_ "GatewayedSignals" SG_ 908 VCU_DspDischgCurr 1;
BA_ "GenSigSendType" SG_ 908 VCU_AuthFailWarning 1;
BA_ "GatewayedSignals" SG_ 908 VCU_AuthFailWarning 1;
BA_ "GenSigSendType" SG_ 908 VCU_DspDischgVolt 1;
BA_ "GatewayedSignals" SG_ 908 VCU_DspDischgVolt 1;
BA_ "GenSigSendType" SG_ 908 VCU_DspChgCurr 1;
BA_ "GatewayedSignals" SG_ 908 VCU_DspChgCurr 1;
BA_ "GenSigSendType" SG_ 908 VCU_DspChgVolt 1;
BA_ "GatewayedSignals" SG_ 908 VCU_DspChgVolt 1;
BA_ "GenSigSendType" SG_ 908 VCU_SOCDynamicDspSt 1;
BA_ "GatewayedSignals" SG_ 908 VCU_SOCDynamicDspSt 1;
BA_ "GenSigSendType" SG_ 908 VCU_DspDischgSt 1;
BA_ "GatewayedSignals" SG_ 908 VCU_DspDischgSt 1;
BA_ "GenSigSendType" SG_ 908 VCU_DspChgSt 1;
BA_ "GatewayedSignals" SG_ 908 VCU_DspChgSt 1;
BA_ "GatewayedSignals" SG_ 908 VCU_DrvModeMemCfgSt 1;
BA_ "GenSigSendType" SG_ 908 VCU_DrvModeMemCfgSt 1;
BA_ "GatewayedSignals" SG_ 1541 ACU_VCU_CompanyLatitude 1;
BA_ "GenSigSendType" SG_ 1541 ACU_VCU_CompanyLatitude 1;
BA_ "GatewayedSignals" SG_ 1541 ACU_VCU_CompanyLongtitude 1;
BA_ "GenSigSendType" SG_ 1541 ACU_VCU_CompanyLongtitude 1;
BA_ "GatewayedSignals" SG_ 1541 ACU_VCU_HomeLatitude 1;
BA_ "GenSigSendType" SG_ 1541 ACU_VCU_HomeLatitude 1;
BA_ "GatewayedSignals" SG_ 1541 ACU_VCU_HomeLongtitude 1;
BA_ "GenSigSendType" SG_ 1541 ACU_VCU_HomeLongtitude 1;
BA_ "GatewayedSignals" SG_ 1541 ACU_VCU_Commute_state 1;
BA_ "GenSigSendType" SG_ 1541 ACU_VCU_Commute_state 1;
BA_ "GatewayedSignals" SG_ 1541 ACU_HomeCompanyDstc 1;
BA_ "GenSigSendType" SG_ 1541 ACU_HomeCompanyDstc 1;
BA_ "GatewayedSignals" SG_ 1541 ACU_SmartNaviChrgHeatSt 1;
BA_ "GenSigSendType" SG_ 1541 ACU_SmartNaviChrgHeatSt 1;
BA_ "GatewayedSignals" SG_ 1541 ACU_SmartNaviDriveSt 1;
BA_ "GenSigSendType" SG_ 1541 ACU_SmartNaviDriveSt 1;
BA_ "GatewayedSignals" SG_ 1541 ACU_SmartCommutDriveSt 1;
BA_ "GenSigSendType" SG_ 1541 ACU_SmartCommutDriveSt 1;
BA_ "GenSigSendType" SG_ 1540 ACU_FreeWayExitLength 1;
BA_ "GenSigSendType" SG_ 1540 ACU_FreeWayEntranceLength 1;
BA_ "GenSigSendType" SG_ 1540 ACU_DestChgPileSt 1;
BA_ "GenSigSendType" SG_ 1540 ACU_CurrentSegSpdLim 1;
BA_ "GenSigSendType" SG_ 1540 ACU_NaviRemainTime 1;
BA_ "GenSigSendType" SG_ 1540 ACU_NaviRemainLength 1;
BA_ "GenSigSendType" SG_ 1540 ACU_NaviTrafLength 1;
BA_ "GenSigSendType" SG_ 1539 ACU_LengthSeg20 1;
BA_ "GenSigSendType" SG_ 1539 ACU_LengthSeg19 1;
BA_ "GenSigSendType" SG_ 1539 ACU_LengthSeg18 1;
BA_ "GenSigSendType" SG_ 1539 ACU_LengthSeg17 1;
BA_ "GenSigSendType" SG_ 1539 ACU_LengthSeg16 1;
BA_ "GenSigSendType" SG_ 1539 ACU_LengthSeg15 1;
BA_ "GenSigSendType" SG_ 1539 ACU_LengthSeg14 1;
BA_ "GenSigSendType" SG_ 1539 ACU_LengthSeg13 1;
BA_ "GenSigSendType" SG_ 1539 ACU_LengthSeg12 1;
BA_ "GenSigSendType" SG_ 1539 ACU_LengthSeg11 1;
BA_ "GenSigSendType" SG_ 1542 ACU_LengthSeg10 1;
BA_ "GenSigSendType" SG_ 1542 ACU_LengthSeg9 1;
BA_ "GenSigSendType" SG_ 1542 ACU_LengthSeg8 1;
BA_ "GenSigSendType" SG_ 1542 ACU_LengthSeg7 1;
BA_ "GenSigSendType" SG_ 1542 ACU_LengthSeg6 1;
BA_ "GenSigSendType" SG_ 1542 ACU_LengthSeg5 1;
BA_ "GenSigSendType" SG_ 1542 ACU_LengthSeg4 1;
BA_ "GenSigSendType" SG_ 1542 ACU_LengthSeg3 1;
BA_ "GenSigSendType" SG_ 1542 ACU_LengthSeg2 1;
BA_ "GenSigSendType" SG_ 1542 ACU_LengthSeg1 1;
BA_ "GenSigSendType" SG_ 1537 ACU_TrafficSeg20 1;
BA_ "GenSigSendType" SG_ 1537 ACU_TrafficSeg19 1;
BA_ "GenSigSendType" SG_ 1537 ACU_TrafficSeg18 1;
BA_ "GenSigSendType" SG_ 1537 ACU_TrafficSeg17 1;
BA_ "GenSigSendType" SG_ 1537 ACU_TrafficSeg16 1;
BA_ "GenSigSendType" SG_ 1537 ACU_TrafficSeg15 1;
BA_ "GenSigSendType" SG_ 1537 ACU_TrafficSeg14 1;
BA_ "GenSigSendType" SG_ 1537 ACU_TrafficSeg13 1;
BA_ "GenSigSendType" SG_ 1537 ACU_TrafficSeg12 1;
BA_ "GenSigSendType" SG_ 1537 ACU_TrafficSeg11 1;
BA_ "GenSigSendType" SG_ 1537 ACU_TrafficSeg10 1;
BA_ "GenSigSendType" SG_ 1537 ACU_TrafficSeg9 1;
BA_ "GenSigSendType" SG_ 1537 ACU_TrafficSeg8 1;
BA_ "GenSigSendType" SG_ 1537 ACU_TrafficSeg7 1;
BA_ "GenSigSendType" SG_ 1537 ACU_TrafficSeg6 1;
BA_ "GenSigSendType" SG_ 1537 ACU_TrafficSeg5 1;
BA_ "GenSigSendType" SG_ 1537 ACU_TrafficSeg4 1;
BA_ "GenSigSendType" SG_ 1537 ACU_TrafficSeg3 1;
BA_ "GenSigSendType" SG_ 1537 ACU_TrafficSeg2 1;
BA_ "GenSigSendType" SG_ 1537 ACU_TrafficSeg1 1;
BA_ "Remark" SG_ 863 TEL_TelematicsRegisterSt "";
BA_ "GenSigSendType" SG_ 863 TEL_TelematicsRegisterSt 1;
BA_ "Remark" SG_ 863 TEL_BTManualMode "";
BA_ "GenSigSendType" SG_ 863 TEL_BTManualMode 1;
BA_ "Remark" SG_ 863 TEL_BTAvrcpSt "";
BA_ "GenSigSendType" SG_ 863 TEL_BTAvrcpSt 1;
BA_ "Remark" SG_ 863 TEL_BTAvrcpPlayMode "";
BA_ "GenSigSendType" SG_ 863 TEL_BTAvrcpPlayMode 1;
BA_ "GenSigStartValue" SG_ 863 TEL_BTAvrcpPlayMode 3;
BA_ "Remark" SG_ 863 TEL_BTHandfreeSt "";
BA_ "GenSigSendType" SG_ 863 TEL_BTHandfreeSt 1;
BA_ "Remark" SG_ 863 TEL_BTHisdel "";
BA_ "GenSigSendType" SG_ 863 TEL_BTHisdel 1;
BA_ "Remark" SG_ 863 TEL_BTAutoconectingSt "";
BA_ "GenSigSendType" SG_ 863 TEL_BTAutoconectingSt 1;
BA_ "Remark" SG_ 863 TEL_BTPowerSt "";
BA_ "GenSigSendType" SG_ 863 TEL_BTPowerSt 1;
BA_ "Remark" SG_ 863 TEL_TelematicsModeActSt "";
BA_ "GenSigSendType" SG_ 863 TEL_TelematicsModeActSt 1;
BA_ "GenSigSendType" SG_ 638 VCU_DrvTargetSOEResp 1;
BA_ "Remark" SG_ 638 VCU_ChgCurrCfgResp "新增";
BA_ "GenSigSendType" SG_ 638 VCU_ChgCurrCfgResp 1;
BA_ "GenSigStartValue" SG_ 638 VCU_ChgCurrCfgResp 16;
BA_ "Remark" SG_ 638 VCU_ChgActiveSt "新增";
BA_ "GenSigSendType" SG_ 638 VCU_ChgActiveSt 1;
BA_ "Remark" SG_ 638 VCU_PlugAutoUnlockCfgResp "新增";
BA_ "GenSigSendType" SG_ 638 VCU_PlugAutoUnlockCfgResp 1;
BA_ "Remark" SG_ 638 VCU_DischgTimeCount "新增";
BA_ "GenSigSendType" SG_ 638 VCU_DischgTimeCount 1;
BA_ "Remark" SG_ 638 VCU_DischgEngStartSocResp "新增";
BA_ "GenSigSendType" SG_ 638 VCU_DischgEngStartSocResp 1;
BA_ "Remark" SG_ 638 VCU_DischgEngStartPermit "新增";
BA_ "GenSigSendType" SG_ 638 VCU_DischgEngStartPermit 1;
BA_ "Remark" SG_ 638 VCU_DischgActiveSt "新增";
BA_ "GenSigSendType" SG_ 638 VCU_DischgActiveSt 1;
BA_ "Remark" SG_ 638 VCU_DischgEndVehRng "新增";
BA_ "GenSigSendType" SG_ 638 VCU_DischgEndVehRng 1;
BA_ "Remark" SG_ 638 VCU_DischgSocCfgResp "新增";
BA_ "GenSigSendType" SG_ 638 VCU_DischgSocCfgResp 1;
BA_ "Remark" SG_ 1075 HVSPRR_NMSleepAck "";
BA_ "GenSigSendType" SG_ 1075 HVSPRR_NMSleepAck 1;
BA_ "Remark" SG_ 1075 HVSPRR_NMSleepInd "";
BA_ "GenSigSendType" SG_ 1075 HVSPRR_NMSleepInd 1;
BA_ "Remark" SG_ 1075 HVSPRR_NMLimpHome "";
BA_ "GenSigSendType" SG_ 1075 HVSPRR_NMLimpHome 1;
BA_ "Remark" SG_ 1075 HVSPRR_NMRing "";
BA_ "GenSigSendType" SG_ 1075 HVSPRR_NMRing 1;
BA_ "Remark" SG_ 1075 HVSPRR_NMAlive "";
BA_ "GenSigSendType" SG_ 1075 HVSPRR_NMAlive 1;
BA_ "Remark" SG_ 1075 HVSPRR_NMDestAddress "";
BA_ "GenSigSendType" SG_ 1075 HVSPRR_NMDestAddress 1;
BA_ "Remark" SG_ 1074 HVSPRL_NMSleepAck "";
BA_ "GenSigSendType" SG_ 1074 HVSPRL_NMSleepAck 1;
BA_ "Remark" SG_ 1074 HVSPRL_NMSleepInd "";
BA_ "GenSigSendType" SG_ 1074 HVSPRL_NMSleepInd 1;
BA_ "Remark" SG_ 1074 HVSPRL_NMLimpHome "";
BA_ "GenSigSendType" SG_ 1074 HVSPRL_NMLimpHome 1;
BA_ "Remark" SG_ 1074 HVSPRL_NMRing "";
BA_ "GenSigSendType" SG_ 1074 HVSPRL_NMRing 1;
BA_ "Remark" SG_ 1074 HVSPRL_NMAlive "";
BA_ "GenSigSendType" SG_ 1074 HVSPRL_NMAlive 1;
BA_ "Remark" SG_ 1074 HVSPRL_NMDestAddress "";
BA_ "GenSigSendType" SG_ 1074 HVSPRL_NMDestAddress 1;
BA_ "Remark" SG_ 558 HVSPRR_RR_Freezepemissions_FuncC "";
BA_ "GenSigSendType" SG_ 558 HVSPRR_RR_Freezepemissions_FuncC 1;
BA_ "SystemSignalLongSymbol" SG_ 558 HVSPRR_RR_Freezepemissions_FuncC "HVSPRR_RR_Freezepemissions_FuncCfgSt";
BA_ "Remark" SG_ 558 HVSPRR_RRSPABUttonSt "";
BA_ "GenSigSendType" SG_ 558 HVSPRR_RRSPABUttonSt 1;
BA_ "Remark" SG_ 557 HVSPRL_RL_Freezepemissions_FuncC "";
BA_ "GenSigSendType" SG_ 557 HVSPRL_RL_Freezepemissions_FuncC 1;
BA_ "SystemSignalLongSymbol" SG_ 557 HVSPRL_RL_Freezepemissions_FuncC "HVSPRL_RL_Freezepemissions_FuncCfgSt";
BA_ "Remark" SG_ 557 HVSPRL_RLSPABUttonSt "";
BA_ "GenSigSendType" SG_ 557 HVSPRL_RLSPABUttonSt 1;
BA_ "Remark" SG_ 1123 MSM_NMDataField "";
BA_ "GenSigSendType" SG_ 1123 MSM_NMDataField 1;
BA_ "Remark" SG_ 1123 MSM_NMWakeupOrignin "";
BA_ "GenSigSendType" SG_ 1123 MSM_NMWakeupOrignin 1;
BA_ "Remark" SG_ 1123 MSM_NMSleepAck "";
BA_ "GenSigSendType" SG_ 1123 MSM_NMSleepAck 1;
BA_ "Remark" SG_ 1123 MSM_NMSleepInd "";
BA_ "GenSigSendType" SG_ 1123 MSM_NMSleepInd 1;
BA_ "Remark" SG_ 1123 MSM_NMLimpHome "";
BA_ "GenSigSendType" SG_ 1123 MSM_NMLimpHome 1;
BA_ "Remark" SG_ 1123 MSM_NMRing "";
BA_ "GenSigSendType" SG_ 1123 MSM_NMRing 1;
BA_ "Remark" SG_ 1123 MSM_NMAlive "";
BA_ "GenSigSendType" SG_ 1123 MSM_NMAlive 1;
BA_ "Remark" SG_ 1123 MSM_NMDestAddress "";
BA_ "GenSigSendType" SG_ 1123 MSM_NMDestAddress 1;
BA_ "GenSigSendType" SG_ 764 SCMRR_RemoteDiagCode 1;
BA_ "Remark" SG_ 764 MSM_RRSeatRecoveryModeSt "";
BA_ "GenSigSendType" SG_ 764 MSM_RRSeatRecoveryModeSt 1;
BA_ "Remark" SG_ 764 MSM_RRSeatSpaModeSt "";
BA_ "GenSigSendType" SG_ 764 MSM_RRSeatSpaModeSt 1;
BA_ "Remark" SG_ 764 MSM_RRSeatMemoryModeSt "";
BA_ "GenSigSendType" SG_ 764 MSM_RRSeatMemoryModeSt 1;
BA_ "Remark" SG_ 764 MSM_RRSeatVoiceCtrlResp "";
BA_ "GenSigSendType" SG_ 764 MSM_RRSeatVoiceCtrlResp 1;
BA_ "Remark" SG_ 764 MSM_RRSeatOperationSt "";
BA_ "GenSigSendType" SG_ 764 MSM_RRSeatOperationSt 1;
BA_ "Remark" SG_ 764 MSM_RRSeatShoulderCurrentPst "";
BA_ "GenSigSendType" SG_ 764 MSM_RRSeatShoulderCurrentPst 1;
BA_ "GenSigStartValue" SG_ 764 MSM_RRSeatShoulderCurrentPst 255;
BA_ "Remark" SG_ 764 MSM_RRSeatOttoman2CurrentPst "";
BA_ "GenSigSendType" SG_ 764 MSM_RRSeatOttoman2CurrentPst 1;
BA_ "GenSigStartValue" SG_ 764 MSM_RRSeatOttoman2CurrentPst 255;
BA_ "Remark" SG_ 764 MSM_RRSeatOttoman1CurrentPst "";
BA_ "GenSigSendType" SG_ 764 MSM_RRSeatOttoman1CurrentPst 1;
BA_ "GenSigStartValue" SG_ 764 MSM_RRSeatOttoman1CurrentPst 255;
BA_ "Remark" SG_ 764 MSM_RRSeatBackCurrentPst "";
BA_ "GenSigSendType" SG_ 764 MSM_RRSeatBackCurrentPst 1;
BA_ "GenSigStartValue" SG_ 764 MSM_RRSeatBackCurrentPst 255;
BA_ "Remark" SG_ 764 MSM_RRSeatSlideCurrentPst "";
BA_ "GenSigSendType" SG_ 764 MSM_RRSeatSlideCurrentPst 1;
BA_ "GenSigStartValue" SG_ 764 MSM_RRSeatSlideCurrentPst 255;
BA_ "Remark" SG_ 764 MSM_RRSeatSlidepositionSensorSig "";
BA_ "GenSigSendType" SG_ 764 MSM_RRSeatSlidepositionSensorSig 1;
BA_ "Remark" SG_ 764 MSM_RRSlideLockSwitch2Sig "";
BA_ "GenSigSendType" SG_ 764 MSM_RRSlideLockSwitch2Sig 1;
BA_ "Remark" SG_ 764 MSM_RRSlideLockSwitch1Sig "";
BA_ "GenSigSendType" SG_ 764 MSM_RRSlideLockSwitch1Sig 1;
BA_ "Remark" SG_ 764 MSM_RRSeatMemoryModePositionSt "";
BA_ "GenSigSendType" SG_ 764 MSM_RRSeatMemoryModePositionSt 1;
BA_ "Remark" SG_ 764 MSM_RRSeatWelcomeFuncCfgSt "";
BA_ "GenSigSendType" SG_ 764 MSM_RRSeatWelcomeFuncCfgSt 1;
BA_ "Remark" SG_ 1084 MSM_NMDataField "";
BA_ "GenSigSendType" SG_ 1084 MSM_NMDataField 1;
BA_ "Remark" SG_ 1084 MSM_NMWakeupOrignin "";
BA_ "GenSigSendType" SG_ 1084 MSM_NMWakeupOrignin 1;
BA_ "Remark" SG_ 1084 MSM_NMSleepAck "";
BA_ "GenSigSendType" SG_ 1084 MSM_NMSleepAck 1;
BA_ "Remark" SG_ 1084 MSM_NMSleepInd "";
BA_ "GenSigSendType" SG_ 1084 MSM_NMSleepInd 1;
BA_ "Remark" SG_ 1084 MSM_NMLimpHome "";
BA_ "GenSigSendType" SG_ 1084 MSM_NMLimpHome 1;
BA_ "Remark" SG_ 1084 MSM_NMRing "";
BA_ "GenSigSendType" SG_ 1084 MSM_NMRing 1;
BA_ "Remark" SG_ 1084 MSM_NMAlive "";
BA_ "GenSigSendType" SG_ 1084 MSM_NMAlive 1;
BA_ "Remark" SG_ 1084 MSM_NMDestAddress "";
BA_ "GenSigSendType" SG_ 1084 MSM_NMDestAddress 1;
BA_ "Remark" SG_ 767 Notused "";
BA_ "GenSigSendType" SG_ 767 Notused 1;
BA_ "Remark" SG_ 767 MSM_RLSeatRecoveryModeSt "";
BA_ "GenSigSendType" SG_ 767 MSM_RLSeatRecoveryModeSt 1;
BA_ "Remark" SG_ 767 MSM_RLSeatSpaModeSt "";
BA_ "GenSigSendType" SG_ 767 MSM_RLSeatSpaModeSt 1;
BA_ "Remark" SG_ 767 MSM_RLSeatMemoryModeSt "";
BA_ "GenSigSendType" SG_ 767 MSM_RLSeatMemoryModeSt 1;
BA_ "Remark" SG_ 767 MSM_RLSeatVoiceCtrlResp "";
BA_ "GenSigSendType" SG_ 767 MSM_RLSeatVoiceCtrlResp 1;
BA_ "Remark" SG_ 767 MSM_RLSeatOperationSt "";
BA_ "GenSigSendType" SG_ 767 MSM_RLSeatOperationSt 1;
BA_ "Remark" SG_ 767 MSM_RLSeatShoulderCurrentPst "";
BA_ "GenSigSendType" SG_ 767 MSM_RLSeatShoulderCurrentPst 1;
BA_ "GenSigStartValue" SG_ 767 MSM_RLSeatShoulderCurrentPst 255;
BA_ "Remark" SG_ 767 MSM_RLSeatOttoman2CurrentPst "";
BA_ "GenSigSendType" SG_ 767 MSM_RLSeatOttoman2CurrentPst 1;
BA_ "GenSigStartValue" SG_ 767 MSM_RLSeatOttoman2CurrentPst 255;
BA_ "Remark" SG_ 767 MSM_RLSeatOttoman1CurrentPst "";
BA_ "GenSigSendType" SG_ 767 MSM_RLSeatOttoman1CurrentPst 1;
BA_ "GenSigStartValue" SG_ 767 MSM_RLSeatOttoman1CurrentPst 255;
BA_ "Remark" SG_ 767 MSM_RLSeatBackCurrentPst "";
BA_ "GenSigSendType" SG_ 767 MSM_RLSeatBackCurrentPst 1;
BA_ "GenSigStartValue" SG_ 767 MSM_RLSeatBackCurrentPst 255;
BA_ "Remark" SG_ 767 MSM_RLSeatSlideCurrentPst "";
BA_ "GenSigSendType" SG_ 767 MSM_RLSeatSlideCurrentPst 1;
BA_ "GenSigStartValue" SG_ 767 MSM_RLSeatSlideCurrentPst 255;
BA_ "Remark" SG_ 767 MSM_RLSeatSlidepositionSensorSig "";
BA_ "GenSigSendType" SG_ 767 MSM_RLSeatSlidepositionSensorSig 1;
BA_ "Remark" SG_ 767 MSM_RLSlideLockSwitch2Sig "";
BA_ "GenSigSendType" SG_ 767 MSM_RLSlideLockSwitch2Sig 1;
BA_ "Remark" SG_ 767 MSM_RLSlideLockSwitch1Sig "";
BA_ "GenSigSendType" SG_ 767 MSM_RLSlideLockSwitch1Sig 1;
BA_ "Remark" SG_ 767 MSM_RLSeatMemoryModePositionSt "";
BA_ "GenSigSendType" SG_ 767 MSM_RLSeatMemoryModePositionSt 1;
BA_ "Remark" SG_ 767 MSM_RLSeatWelcomeFuncCfgSt "";
BA_ "GenSigSendType" SG_ 767 MSM_RLSeatWelcomeFuncCfgSt 1;
BA_ "Remark" SG_ 866 PSDR_BuzzerRequest "";
BA_ "GenSigSendType" SG_ 866 PSDR_BuzzerRequest 1;
BA_ "Remark" SG_ 866 PSDR_DoorSpdst "";
BA_ "GenSigSendType" SG_ 866 PSDR_DoorSpdst 1;
BA_ "Remark" SG_ 866 PSDR_FuelOpenSt "";
BA_ "GenSigSendType" SG_ 866 PSDR_FuelOpenSt 1;
BA_ "Remark" SG_ 866 PSDR_MainSWOffForbSt "";
BA_ "GenSigSendType" SG_ 866 PSDR_MainSWOffForbSt 1;
BA_ "Remark" SG_ 866 PSD_ModeSt "";
BA_ "GenSigSendType" SG_ 866 PSD_ModeSt 1;
BA_ "GenSigStartValue" SG_ 866 PSD_ModeSt 1;
BA_ "Remark" SG_ 866 PSDR_PinchDet "";
BA_ "GenSigSendType" SG_ 866 PSDR_PinchDet 1;
BA_ "Remark" SG_ 866 PSDR_OperationMode "";
BA_ "GenSigSendType" SG_ 866 PSDR_OperationMode 1;
BA_ "GenSigStartValue" SG_ 866 PSDR_OperationMode 1;
BA_ "Remark" SG_ 866 PSDR_DoorPst "";
BA_ "GenSigSendType" SG_ 866 PSDR_DoorPst 1;
BA_ "Remark" SG_ 865 PSDL_BuzzerRequest "";
BA_ "GenSigSendType" SG_ 865 PSDL_BuzzerRequest 1;
BA_ "Remark" SG_ 865 PSDL_DoorSpdst "";
BA_ "GenSigSendType" SG_ 865 PSDL_DoorSpdst 1;
BA_ "Remark" SG_ 865 PSDL_FuelOpenSt "";
BA_ "GenSigSendType" SG_ 865 PSDL_FuelOpenSt 1;
BA_ "Remark" SG_ 865 PSDL_MainSWOffForbSt "";
BA_ "GenSigSendType" SG_ 865 PSDL_MainSWOffForbSt 1;
BA_ "Remark" SG_ 865 PSDL_PinchDet "";
BA_ "GenSigSendType" SG_ 865 PSDL_PinchDet 1;
BA_ "Remark" SG_ 865 PSDL_OperationMode "";
BA_ "GenSigSendType" SG_ 865 PSDL_OperationMode 1;
BA_ "GenSigStartValue" SG_ 865 PSDL_OperationMode 1;
BA_ "Remark" SG_ 865 PSDL_DoorPst "";
BA_ "GenSigSendType" SG_ 865 PSDL_DoorPst 1;
BA_ "GenSigTimeoutValue" SG_ 1003 AVAS_ActivatedSt 1;
BA_ "Remark" SG_ 1003 AVAS_ActivatedSt "";
BA_ "GenSigSendType" SG_ 1003 AVAS_ActivatedSt 1;
BA_ "GenSigStartValue" SG_ 1003 AVAS_ActivatedSt 1;
BA_ "Remark" SG_ 118 TEL_ModuleResetSt "";
BA_ "EventCommandSignal" SG_ 118 TEL_ModuleResetSt 1;
BA_ "Remark" SG_ 118 TEL_ResetFailReason "";
BA_ "EventCommandSignal" SG_ 118 TEL_ResetFailReason 1;
BA_ "Remark" SG_ 860 TEL_MobileSignalSt "";
BA_ "GenSigSendType" SG_ 860 TEL_MobileSignalSt 1;
BA_ "Remark" SG_ 860 TEL_MobilePowerSt "";
BA_ "GenSigSendType" SG_ 860 TEL_MobilePowerSt 1;
BA_ "Remark" SG_ 860 TEL_AVRCPSupportSt "";
BA_ "GenSigSendType" SG_ 860 TEL_AVRCPSupportSt 1;
BA_ "Remark" SG_ 860 TEL_A2DPSupportSt "";
BA_ "GenSigSendType" SG_ 860 TEL_A2DPSupportSt 1;
BA_ "Remark" SG_ 860 TEL_PhoneCallSt "";
BA_ "GenSigSendType" SG_ 860 TEL_PhoneCallSt 1;
BA_ "Remark" SG_ 860 TEL_BTConnectingSt "";
BA_ "GenSigSendType" SG_ 860 TEL_BTConnectingSt 1;
BA_ "Remark" SG_ 860 TEL_BTConnectingAct "";
BA_ "GenSigSendType" SG_ 860 TEL_BTConnectingAct 1;
BA_ "Remark" SG_ 860 TEL_BTDisplayAct "";
BA_ "GenSigSendType" SG_ 860 TEL_BTDisplayAct 1;
BA_ "Remark" SG_ 860 TEL_PhoneNumber "";
BA_ "GenSigSendType" SG_ 860 TEL_PhoneNumber 1;
BA_ "Remark" SG_ 926 TEL_Time_Sec "";
BA_ "GenSigSendType" SG_ 926 TEL_Time_Sec 1;
BA_ "GenSigStartValue" SG_ 926 TEL_Time_Sec 1;
BA_ "Remark" SG_ 926 TEL_BookChrgSt "";
BA_ "GenSigSendType" SG_ 926 TEL_BookChrgSt 1;
BA_ "Remark" SG_ 926 TEL_TimeVD "";
BA_ "GenSigSendType" SG_ 926 TEL_TimeVD 1;
BA_ "Remark" SG_ 926 TEL_Time_Min "";
BA_ "GenSigSendType" SG_ 926 TEL_Time_Min 1;
BA_ "GenSigStartValue" SG_ 926 TEL_Time_Min 1;
BA_ "Remark" SG_ 926 TEL_Time_Day "";
BA_ "GenSigSendType" SG_ 926 TEL_Time_Day 1;
BA_ "GenSigStartValue" SG_ 926 TEL_Time_Day 1;
BA_ "Remark" SG_ 926 TEL_Time_Hour "";
BA_ "GenSigSendType" SG_ 926 TEL_Time_Hour 1;
BA_ "GenSigStartValue" SG_ 926 TEL_Time_Hour 1;
BA_ "Remark" SG_ 926 TEL_Time_Month "";
BA_ "GenSigSendType" SG_ 926 TEL_Time_Month 1;
BA_ "GenSigStartValue" SG_ 926 TEL_Time_Month 1;
BA_ "Remark" SG_ 926 TEL_Time_Year "";
BA_ "GenSigSendType" SG_ 926 TEL_Time_Year 1;
BA_ "GenSigStartValue" SG_ 926 TEL_Time_Year -1985;
BA_ "Remark" SG_ 160 TEL_PCS_EventRecordCtrlReq "";
BA_ "GenSigSendType" SG_ 160 TEL_PCS_EventRecordCtrlReq 1;
BA_ "Remark" SG_ 160 TEL_PCS_CtrlReq "";
BA_ "GenSigSendType" SG_ 160 TEL_PCS_CtrlReq 1;
BA_ "Remark" SG_ 1103 GWM_NMDataField "";
BA_ "GenSigSendType" SG_ 1103 GWM_NMDataField 1;
BA_ "Remark" SG_ 1103 GWM_NMWakeupOrignin "";
BA_ "GenSigSendType" SG_ 1103 GWM_NMWakeupOrignin 1;
BA_ "Remark" SG_ 1103 GWM_NMSleepAck "";
BA_ "GenSigSendType" SG_ 1103 GWM_NMSleepAck 1;
BA_ "Remark" SG_ 1103 GWM_NMSleepInd "";
BA_ "GenSigSendType" SG_ 1103 GWM_NMSleepInd 1;
BA_ "Remark" SG_ 1103 GWM_NMLimpHome "";
BA_ "GenSigSendType" SG_ 1103 GWM_NMLimpHome 1;
BA_ "Remark" SG_ 1103 GWM_NMRing "";
BA_ "GenSigSendType" SG_ 1103 GWM_NMRing 1;
BA_ "Remark" SG_ 1103 GWM_NMAlive "";
BA_ "GenSigSendType" SG_ 1103 GWM_NMAlive 1;
BA_ "Remark" SG_ 1103 GWM_NMDestAddress "";
BA_ "GenSigSendType" SG_ 1103 GWM_NMDestAddress 1;
BA_ "Remark" SG_ 802 GW_VehicleModeBroadcast "";
BA_ "Remark" SG_ 968 GW_TransportationMode "";
BA_ "GenSigSendType" SG_ 968 GW_TransportationMode 1;
BA_ "GenSigInvalidValue" SG_ 968 GW_TransportationMode 1;
BA_ "Remark" SG_ 968 GW_LowBatPreWarning "";
BA_ "GenSigSendType" SG_ 968 GW_LowBatPreWarning 1;
BA_ "Remark" SG_ 854 GSM_WarnInfo "";
BA_ "GenSigSendType" SG_ 854 GSM_WarnInfo 1;
BA_ "Remark" SG_ 854 GSM_GearShiftLeverPstReq "";
BA_ "GenSigSendType" SG_ 854 GSM_GearShiftLeverPstReq 1;
BA_ "Remark" SG_ 854 GSM_DriveModeRespFail "";
BA_ "GenSigSendType" SG_ 854 GSM_DriveModeRespFail 1;
BA_ "Remark" SG_ 786 ADAS_AcceComfUpperValue "";
BA_ "GenSigSendType" SG_ 786 ADAS_AcceComfUpperValue 1;
BA_ "Remark" SG_ 786 MRR_PEBSObjType "";
BA_ "GenSigSendType" SG_ 786 MRR_PEBSObjType 1;
BA_ "Remark" SG_ 786 MRR_ACCQuitSound "";
BA_ "GenSigSendType" SG_ 786 MRR_ACCQuitSound 1;
BA_ "Remark" SG_ 786 MRR_ISLACC_St "";
BA_ "GenSigSendType" SG_ 786 MRR_ISLACC_St 1;
BA_ "Remark" SG_ 786 MRR_FCWWarnDistance "";
BA_ "GenSigSendType" SG_ 786 MRR_FCWWarnDistance 1;
BA_ "Remark" SG_ 786 MRR_AEBInterventionSt "";
BA_ "GenSigSendType" SG_ 786 MRR_AEBInterventionSt 1;
BA_ "GenSigTimeoutValue" SG_ 786 MRR_AEBOffSt 1;
BA_ "Remark" SG_ 786 MRR_AEBOffSt "";
BA_ "GenSigSendType" SG_ 786 MRR_AEBOffSt 1;
BA_ "GenSigTimeoutValue" SG_ 786 MRR_AEBFaultSt 1;
BA_ "Remark" SG_ 786 MRR_AEBFaultSt "";
BA_ "GenSigSendType" SG_ 786 MRR_AEBFaultSt 1;
BA_ "GenSigTimeoutValue" SG_ 786 MRR_AEB_PEDPFaultSt 1;
BA_ "Remark" SG_ 786 MRR_AEB_PEDPFaultSt "";
BA_ "GenSigSendType" SG_ 786 MRR_AEB_PEDPFaultSt 1;
BA_ "Remark" SG_ 786 MRR_FCWLatentWarn "";
BA_ "GenSigSendType" SG_ 786 MRR_FCWLatentWarn 1;
BA_ "Remark" SG_ 786 MRR_FCWPreWarn "";
BA_ "GenSigSendType" SG_ 786 MRR_FCWPreWarn 1;
BA_ "Remark" SG_ 786 MRR_FCWInterventionSt "";
BA_ "GenSigSendType" SG_ 786 MRR_FCWInterventionSt 1;
BA_ "GenSigTimeoutValue" SG_ 786 MRR_FCWFaultSt 1;
BA_ "Remark" SG_ 786 MRR_FCWFaultSt "";
BA_ "GenSigSendType" SG_ 786 MRR_FCWFaultSt 1;
BA_ "GenSigTimeoutValue" SG_ 786 MRR_FCWOffSt 1;
BA_ "Remark" SG_ 786 MRR_FCWOffSt "";
BA_ "GenSigSendType" SG_ 786 MRR_FCWOffSt 1;
BA_ "Remark" SG_ 786 MRR_TargetSpd "";
BA_ "GenSigSendType" SG_ 786 MRR_TargetSpd 1;
BA_ "Remark" SG_ 786 MRR_TauGapSet "";
BA_ "GenSigSendType" SG_ 786 MRR_TauGapSet 1;
BA_ "Remark" SG_ 786 MRR_TargetDistanceSt "";
BA_ "GenSigSendType" SG_ 786 MRR_TargetDistanceSt 1;
BA_ "Remark" SG_ 786 MRR_ObjectCapturedSt "";
BA_ "GenSigSendType" SG_ 786 MRR_ObjectCapturedSt 1;
BA_ "Remark" SG_ 786 MRR_ACCTakeOverReq "";
BA_ "GenSigSendType" SG_ 786 MRR_ACCTakeOverReq 1;
BA_ "Remark" SG_ 786 MRR_ACCFuncCancel "";
BA_ "GenSigSendType" SG_ 786 MRR_ACCFuncCancel 1;
BA_ "Remark" SG_ 786 MRR_ACCGoNotifier "";
BA_ "GenSigSendType" SG_ 786 MRR_ACCGoNotifier 1;
BA_ "Remark" SG_ 786 MRR_ACCActiveSt "";
BA_ "GenSigSendType" SG_ 786 MRR_ACCActiveSt 1;
BA_ "GenSigTimeoutValue" SG_ 786 MRR_ACCFaultSt 1;
BA_ "Remark" SG_ 786 MRR_ACCFaultSt "";
BA_ "GenSigSendType" SG_ 786 MRR_ACCFaultSt 1;
BA_ "GenSigTimeoutValue" SG_ 786 MRR_ACCTextInfo 6;
BA_ "Remark" SG_ 786 MRR_ACCTextInfo "";
BA_ "GenSigSendType" SG_ 786 MRR_ACCTextInfo 1;
BA_ "GenSigTimeoutValue" SG_ 786 MRR_ACCMode 7;
BA_ "Remark" SG_ 786 MRR_ACCMode "";
BA_ "GenSigSendType" SG_ 786 MRR_ACCMode 1;
BA_ "Remark" SG_ 861 TMM_ThermalWarning "";
BA_ "GenSigSendType" SG_ 861 TMM_ThermalWarning 1;
BA_ "Remark" SG_ 861 TMM_CouplingThermalFailSafe "";
BA_ "GenSigSendType" SG_ 861 TMM_CouplingThermalFailSafe 1;
BA_ "GenSigTimeoutValue" SG_ 861 TMM_DiagnosticLampReq 1;
BA_ "Remark" SG_ 861 TMM_DiagnosticLampReq "";
BA_ "GenSigSendType" SG_ 861 TMM_DiagnosticLampReq 1;
BA_ "GenSigTimeoutValue" SG_ 861 TMM_SysOperatingMode 1;
BA_ "Remark" SG_ 861 TMM_SysOperatingMode "";
BA_ "GenSigSendType" SG_ 861 TMM_SysOperatingMode 1;
BA_ "Remark" SG_ 840 EPS_FunctionStyleSt "";
BA_ "GenSigSendType" SG_ 840 EPS_FunctionStyleSt 1;
BA_ "GenSigTimeoutValue" SG_ 840 EPS_WarnLamp 1;
BA_ "Remark" SG_ 840 EPS_WarnLamp "";
BA_ "GenSigSendType" SG_ 840 EPS_WarnLamp 1;
BA_ "Remark" SG_ 775 EPB_StpOnBrkToRelParkBrkIndOn "";
BA_ "GenSigSendType" SG_ 775 EPB_StpOnBrkToRelParkBrkIndOn 1;
BA_ "GenSigTimeoutValue" SG_ 775 EPB_SysDispMsgReq 3;
BA_ "Remark" SG_ 775 EPB_SysDispMsgReq "";
BA_ "GenSigSendType" SG_ 775 EPB_SysDispMsgReq 1;
BA_ "GenSigTimeoutValue" SG_ 775 EPB_FailSt 1;
BA_ "Remark" SG_ 775 EPB_FailSt "";
BA_ "GenSigSendType" SG_ 775 EPB_FailSt 1;
BA_ "GenSigTimeoutValue" SG_ 775 EPB_SysStIndReq 2;
BA_ "Remark" SG_ 775 EPB_SysStIndReq "";
BA_ "GenSigSendType" SG_ 775 EPB_SysStIndReq 1;
BA_ "Remark" SG_ 775 EPB_SysAudWarnReq "";
BA_ "GenSigSendType" SG_ 775 EPB_SysAudWarnReq 1;
BA_ "GenSigTimeoutValue" SG_ 775 EPB_SysSt 3;
BA_ "Remark" SG_ 775 EPB_SysSt "";
BA_ "GenSigSendType" SG_ 775 EPB_SysSt 1;
BA_ "GenSigTimeoutValue" SG_ 775 EPB_SysWarnIndReq 1;
BA_ "Remark" SG_ 775 EPB_SysWarnIndReq "";
BA_ "GenSigSendType" SG_ 775 EPB_SysWarnIndReq 1;
BA_ "GenSigTimeoutValue" SG_ 816 SRS_Row2MiddleSeatBeltSt 3;
BA_ "Remark" SG_ 816 SRS_Row2MiddleSeatBeltSt "";
BA_ "GenSigSendType" SG_ 816 SRS_Row2MiddleSeatBeltSt 1;
BA_ "GenSigInvalidValue" SG_ 816 SRS_Row2MiddleSeatBeltSt 3;
BA_ "GenSigTimeoutValue" SG_ 816 SRS_Row2RightSeatBeltSt 3;
BA_ "Remark" SG_ 816 SRS_Row2RightSeatBeltSt "";
BA_ "GenSigSendType" SG_ 816 SRS_Row2RightSeatBeltSt 1;
BA_ "GenSigInvalidValue" SG_ 816 SRS_Row2RightSeatBeltSt 3;
BA_ "GenSigTimeoutValue" SG_ 816 SRS_AirbagFaultSt 1;
BA_ "Remark" SG_ 816 SRS_AirbagFaultSt "";
BA_ "GenSigSendType" SG_ 816 SRS_AirbagFaultSt 1;
BA_ "GenSigTimeoutValue" SG_ 816 SRS_Row2LeftSeatBeltSt 3;
BA_ "Remark" SG_ 816 SRS_Row2LeftSeatBeltSt "";
BA_ "GenSigSendType" SG_ 816 SRS_Row2LeftSeatBeltSt 1;
BA_ "GenSigInvalidValue" SG_ 816 SRS_Row2LeftSeatBeltSt 3;
BA_ "Remark" SG_ 816 SRS_DriverSeatBeltSt "";
BA_ "GenSigSendType" SG_ 816 SRS_DriverSeatBeltSt 1;
BA_ "GenSigInvalidValue" SG_ 816 SRS_DriverSeatBeltSt 3;
BA_ "Remark" SG_ 816 SRS_PsngrSeatBeltSt "";
BA_ "GenSigSendType" SG_ 816 SRS_PsngrSeatBeltSt 1;
BA_ "GenSigInvalidValue" SG_ 816 SRS_PsngrSeatBeltSt 3;
BA_ "GenSigSendType" SG_ 430 SRS_NearCrashOutputSt 1;
BA_ "GenSigSendType" SG_ 430 SRS_Rear_CrashOutputSt 1;
BA_ "GenSigSendType" SG_ 430 SRS_RightSide_CrashOutputSt 1;
BA_ "GenSigSendType" SG_ 430 SRS_LeftSide_CrashOutputSt 1;
BA_ "GenSigSendType" SG_ 430 SRS_Front_CrashOutputSt 1;
BA_ "Remark" SG_ 430 SRS_CrashOutputSt "";
BA_ "GenSigSendType" SG_ 430 SRS_CrashOutputSt 1;
BA_ "GenSigTimeoutValue" SG_ 829 SAS_SteeringAngle 7800;
BA_ "Remark" SG_ 829 SAS_SteeringAngle "the signal position will change after PT0";
BA_ "GenSigSendType" SG_ 829 SAS_SteeringAngle 1;
BA_ "Remark" SG_ 829 SAS_SteeringAngleSpd "the signal position will change after PT0";
BA_ "GenSigSendType" SG_ 829 SAS_SteeringAngleSpd 1;
BA_ "GenSigInvalidValue" SG_ 829 SAS_SteeringAngleSpd 255;
BA_ "Remark" SG_ 829 SAS_TrimmingStatus "the signal position will change after PT0";
BA_ "GenSigSendType" SG_ 829 SAS_TrimmingStatus 1;
BA_ "Remark" SG_ 829 SAS_CalibratedSt "the signal position will change after PT0";
BA_ "GenSigSendType" SG_ 829 SAS_CalibratedSt 1;
BA_ "Remark" SG_ 829 SAS_SteeringAngleVD "the signal position will change after PT0";
BA_ "GenSigSendType" SG_ 829 SAS_SteeringAngleVD 1;
BA_ "Remark" SG_ 667 BCS_RRWheelRotatedDirection "";
BA_ "GenSigSendType" SG_ 667 BCS_RRWheelRotatedDirection 1;
BA_ "Remark" SG_ 667 BCS_RRWheelRotatedDirectionVD "";
BA_ "GenSigSendType" SG_ 667 BCS_RRWheelRotatedDirectionVD 1;
BA_ "Remark" SG_ 667 BCS_RLWheelRotatedDirectionVD "";
BA_ "GenSigSendType" SG_ 667 BCS_RLWheelRotatedDirectionVD 1;
BA_ "Remark" SG_ 667 BCS_RLWheelRotatedDirection "";
BA_ "GenSigSendType" SG_ 667 BCS_RLWheelRotatedDirection 1;
BA_ "Remark" SG_ 667 BCS_FRWheelRotatedDirection "";
BA_ "GenSigSendType" SG_ 667 BCS_FRWheelRotatedDirection 1;
BA_ "Remark" SG_ 667 BCS_FRWheelRotatedDirectionVD "";
BA_ "GenSigSendType" SG_ 667 BCS_FRWheelRotatedDirectionVD 1;
BA_ "Remark" SG_ 667 BCS_FLWheelRotatedDirectionVD "";
BA_ "GenSigSendType" SG_ 667 BCS_FLWheelRotatedDirectionVD 1;
BA_ "Remark" SG_ 667 BCS_FLWheelRotatedDirection "";
BA_ "GenSigSendType" SG_ 667 BCS_FLWheelRotatedDirection 1;
BA_ "Remark" SG_ 667 BCS_RRWheelSpd "";
BA_ "GenSigSendType" SG_ 667 BCS_RRWheelSpd 1;
BA_ "Remark" SG_ 667 BCS_RRWheelSpdVD "";
BA_ "GenSigSendType" SG_ 667 BCS_RRWheelSpdVD 1;
BA_ "Remark" SG_ 667 BCS_RLWheelSpd "";
BA_ "GenSigSendType" SG_ 667 BCS_RLWheelSpd 1;
BA_ "Remark" SG_ 667 BCS_RLWheelSpdVD "";
BA_ "GenSigSendType" SG_ 667 BCS_RLWheelSpdVD 1;
BA_ "Remark" SG_ 667 BCS_FRWheelSpd "";
BA_ "GenSigSendType" SG_ 667 BCS_FRWheelSpd 1;
BA_ "Remark" SG_ 667 BCS_FRWheelSpdVD "";
BA_ "GenSigSendType" SG_ 667 BCS_FRWheelSpdVD 1;
BA_ "Remark" SG_ 667 BCS_FLWheelSpd "";
BA_ "GenSigSendType" SG_ 667 BCS_FLWheelSpd 1;
BA_ "Remark" SG_ 667 BCS_FLWheelSpdVD "";
BA_ "GenSigSendType" SG_ 667 BCS_FLWheelSpdVD 1;
BA_ "GenSigTimeoutValue" SG_ 838 BCS_HBBSt 3;
BA_ "Remark" SG_ 838 BCS_HBBSt "";
BA_ "GenSigSendType" SG_ 838 BCS_HBBSt 1;
BA_ "Remark" SG_ 838 BCS_CDDAvailable "";
BA_ "GenSigSendType" SG_ 838 BCS_CDDAvailable 1;
BA_ "Remark" SG_ 838 BCS_CDDActive "";
BA_ "GenSigSendType" SG_ 838 BCS_CDDActive 1;
BA_ "Remark" SG_ 838 BCS_AWBAvailable "";
BA_ "GenSigSendType" SG_ 838 BCS_AWBAvailable 1;
BA_ "Remark" SG_ 838 BCS_AWBActive "";
BA_ "GenSigSendType" SG_ 838 BCS_AWBActive 1;
BA_ "Remark" SG_ 838 BCS_AEBAvailable "";
BA_ "GenSigSendType" SG_ 838 BCS_AEBAvailable 1;
BA_ "Remark" SG_ 838 BCS_AEBActive "";
BA_ "GenSigSendType" SG_ 838 BCS_AEBActive 1;
BA_ "Remark" SG_ 838 BCS_ABPAvailable "";
BA_ "GenSigSendType" SG_ 838 BCS_ABPAvailable 1;
BA_ "Remark" SG_ 838 BCS_ABPActive "";
BA_ "GenSigSendType" SG_ 838 BCS_ABPActive 1;
BA_ "Remark" SG_ 838 BCS_AVHAvailable "";
BA_ "GenSigSendType" SG_ 838 BCS_AVHAvailable 1;
BA_ "Remark" SG_ 838 BCS_AVHStandby "";
BA_ "GenSigSendType" SG_ 838 BCS_AVHStandby 1;
BA_ "Remark" SG_ 838 BCS_AVHSt "";
BA_ "GenSigSendType" SG_ 838 BCS_AVHSt 1;
BA_ "GenSigTimeoutValue" SG_ 838 BCS_HDCErrSt 1;
BA_ "Remark" SG_ 838 BCS_HDCErrSt "";
BA_ "GenSigSendType" SG_ 838 BCS_HDCErrSt 1;
BA_ "GenSigTimeoutValue" SG_ 838 BCS_HHCErrSt 1;
BA_ "Remark" SG_ 838 BCS_HHCErrSt "";
BA_ "GenSigSendType" SG_ 838 BCS_HHCErrSt 1;
BA_ "Remark" SG_ 838 BCS_ABAavailable "";
BA_ "GenSigSendType" SG_ 838 BCS_ABAavailable 1;
BA_ "Remark" SG_ 838 BCS_ABAactive "";
BA_ "GenSigSendType" SG_ 838 BCS_ABAactive 1;
BA_ "GenSigTimeoutValue" SG_ 838 BCS_HDCCtrlSt 1;
BA_ "Remark" SG_ 838 BCS_HDCCtrlSt "";
BA_ "GenSigSendType" SG_ 838 BCS_HDCCtrlSt 1;
BA_ "Remark" SG_ 838 BCS_VDCOff "";
BA_ "GenSigSendType" SG_ 838 BCS_VDCOff 1;
BA_ "Remark" SG_ 838 BCS_TCSOff "";
BA_ "GenSigSendType" SG_ 838 BCS_TCSOff 1;
BA_ "Remark" SG_ 838 BCS_BrakeOverHeat "";
BA_ "GenSigSendType" SG_ 838 BCS_BrakeOverHeat 1;
BA_ "Remark" SG_ 608 BCS_VDCActiveSt "";
BA_ "GenSigSendType" SG_ 608 BCS_VDCActiveSt 1;
BA_ "Remark" SG_ 608 BCS_VehSpd "";
BA_ "GenSigSendType" SG_ 608 BCS_VehSpd 1;
BA_ "Remark" SG_ 608 BCS_VehSpdVD "";
BA_ "GenSigSendType" SG_ 608 BCS_VehSpdVD 1;
BA_ "GenSigStartValue" SG_ 608 BCS_VehSpdVD 1;
BA_ "GenSigTimeoutValue" SG_ 608 BCS_VDCFaultSt 1;
BA_ "Remark" SG_ 608 BCS_VDCFaultSt "";
BA_ "GenSigSendType" SG_ 608 BCS_VDCFaultSt 1;
BA_ "Remark" SG_ 608 BCS_TCSActiveSt "";
BA_ "GenSigSendType" SG_ 608 BCS_TCSActiveSt 1;
BA_ "GenSigTimeoutValue" SG_ 608 BCS_TCSFaultSt 1;
BA_ "Remark" SG_ 608 BCS_TCSFaultSt "";
BA_ "GenSigSendType" SG_ 608 BCS_TCSFaultSt 1;
BA_ "Remark" SG_ 608 BCS_EBDActiveSt "";
BA_ "GenSigSendType" SG_ 608 BCS_EBDActiveSt 1;
BA_ "GenSigTimeoutValue" SG_ 608 BCS_EBDFaultSt 1;
BA_ "Remark" SG_ 608 BCS_EBDFaultSt "";
BA_ "GenSigSendType" SG_ 608 BCS_EBDFaultSt 1;
BA_ "GenSigTimeoutValue" SG_ 608 BCS_ABSFaultSt 1;
BA_ "Remark" SG_ 608 BCS_ABSFaultSt "";
BA_ "GenSigSendType" SG_ 608 BCS_ABSFaultSt 1;
BA_ "Remark" SG_ 608 BCS_ABSActiveSt "";
BA_ "GenSigSendType" SG_ 608 BCS_ABSActiveSt 1;
BA_ "Remark" SG_ 823 BCS_RRWheelSpdEdgesSumVD "";
BA_ "GenSigSendType" SG_ 823 BCS_RRWheelSpdEdgesSumVD 1;
BA_ "Remark" SG_ 823 BCS_RLWheelSpdEdgesSumVD "";
BA_ "GenSigSendType" SG_ 823 BCS_RLWheelSpdEdgesSumVD 1;
BA_ "Remark" SG_ 823 BCS_FRWheelSpdEdgesSumVD "";
BA_ "GenSigSendType" SG_ 823 BCS_FRWheelSpdEdgesSumVD 1;
BA_ "Remark" SG_ 823 BCS_FLWheelSpdEdgesSumVD "";
BA_ "GenSigSendType" SG_ 823 BCS_FLWheelSpdEdgesSumVD 1;
BA_ "Remark" SG_ 823 BCS_RRWheelSpdEdgesSum "";
BA_ "GenSigSendType" SG_ 823 BCS_RRWheelSpdEdgesSum 1;
BA_ "Remark" SG_ 823 BCS_RLWheelSpdEdgesSum "";
BA_ "GenSigSendType" SG_ 823 BCS_RLWheelSpdEdgesSum 1;
BA_ "Remark" SG_ 823 BCS_FRWheelSpdEdgesSum "";
BA_ "GenSigSendType" SG_ 823 BCS_FRWheelSpdEdgesSum 1;
BA_ "Remark" SG_ 823 BCS_FLWheelSpdEdgesSum "";
BA_ "GenSigSendType" SG_ 823 BCS_FLWheelSpdEdgesSum 1;
BA_ "GenSigSendType" SG_ 822 EMS_EngineStartStopSt 1;
BA_ "Remark" SG_ 822 EMS_FuelPulse "";
BA_ "GenSigSendType" SG_ 822 EMS_FuelPulse 1;
BA_ "Remark" SG_ 822 EMS_EngSpd "";
BA_ "GenSigSendType" SG_ 822 EMS_EngSpd 1;
BA_ "Remark" SG_ 822 EMS_EngSpdVD "";
BA_ "GenSigSendType" SG_ 822 EMS_EngSpdVD 1;
BA_ "GenSigStartValue" SG_ 822 EMS_EngSpdVD 1;
BA_ "Remark" SG_ 822 EMS_EngWaterTempVD "";
BA_ "GenSigSendType" SG_ 822 EMS_EngWaterTempVD 1;
BA_ "Remark" SG_ 822 EMS_EngSt "";
BA_ "GenSigSendType" SG_ 822 EMS_EngSt 1;
BA_ "GenSigTimeoutValue" SG_ 822 EMS_EPCSt 1;
BA_ "Remark" SG_ 822 EMS_EPCSt "";
BA_ "GenSigSendType" SG_ 822 EMS_EPCSt 1;
BA_ "GenSigTimeoutValue" SG_ 822 EMS_MilSt 1;
BA_ "Remark" SG_ 822 EMS_MilSt "";
BA_ "GenSigSendType" SG_ 822 EMS_MilSt 1;
BA_ "GenSigTimeoutValue" SG_ 822 EMS_EngWaterTemp 60;
BA_ "Remark" SG_ 822 EMS_EngWaterTemp "";
BA_ "GenSigSendType" SG_ 822 EMS_EngWaterTemp 1;
BA_ "GenSigInvalidValue" SG_ 822 EMS_EngWaterTemp 255;
BA_ "GenSigStartValue" SG_ 822 EMS_EngWaterTemp 60;
BA_ "GenSigSendType" SG_ 785 RRR_RCWWarnType 1;
BA_ "Remark" SG_ 785 RLR_AudioWarnRL "";
BA_ "GenSigSendType" SG_ 785 RLR_AudioWarnRL 1;
BA_ "Remark" SG_ 785 RLR_AudioWarnFL "";
BA_ "GenSigSendType" SG_ 785 RLR_AudioWarnFL 1;
BA_ "Remark" SG_ 785 RRR_RCTAAssistType "";
BA_ "GenSigSendType" SG_ 785 RRR_RCTAAssistType 1;
BA_ "Remark" SG_ 785 RLR_RCTAWarnLeft "";
BA_ "GenSigSendType" SG_ 785 RLR_RCTAWarnLeft 1;
BA_ "Remark" SG_ 785 RLR_LCAWarnLeft "";
BA_ "GenSigSendType" SG_ 785 RLR_LCAWarnLeft 1;
BA_ "Remark" SG_ 785 RRR_AudioWarnRR "";
BA_ "GenSigSendType" SG_ 785 RRR_AudioWarnRR 1;
BA_ "Remark" SG_ 785 RRR_AudioWarnFR "";
BA_ "GenSigSendType" SG_ 785 RRR_AudioWarnFR 1;
BA_ "Remark" SG_ 785 RRR_RCWWarn "";
BA_ "GenSigSendType" SG_ 785 RRR_RCWWarn 1;
BA_ "GenSigTimeoutValue" SG_ 785 RRR_RCWSt 3;
BA_ "Remark" SG_ 785 RRR_RCWSt "";
BA_ "GenSigSendType" SG_ 785 RRR_RCWSt 1;
BA_ "Remark" SG_ 785 RRR_RCTAWarnRight "";
BA_ "GenSigSendType" SG_ 785 RRR_RCTAWarnRight 1;
BA_ "Remark" SG_ 785 RRR_LCAWarnRight "";
BA_ "GenSigSendType" SG_ 785 RRR_LCAWarnRight 1;
BA_ "Remark" SG_ 785 RLR_VibrWarnL "";
BA_ "GenSigSendType" SG_ 785 RLR_VibrWarnL 1;
BA_ "GenSigTimeoutValue" SG_ 785 RRR_LCASt 3;
BA_ "Remark" SG_ 785 RRR_LCASt "";
BA_ "GenSigSendType" SG_ 785 RRR_LCASt 1;
BA_ "Remark" SG_ 785 RRR_RCTASt "";
BA_ "GenSigSendType" SG_ 785 RRR_RCTASt 1;
BA_ "Remark" SG_ 785 RRR_DOWSt "";
BA_ "GenSigSendType" SG_ 785 RRR_DOWSt 1;
BA_ "Remark" SG_ 785 RLR_ExMirLedWarnL "";
BA_ "GenSigSendType" SG_ 785 RLR_ExMirLedWarnL 1;
BA_ "Remark" SG_ 785 RLR_IALWarnRL "";
BA_ "GenSigSendType" SG_ 785 RLR_IALWarnRL 1;
BA_ "Remark" SG_ 785 RLR_IALWarnFL "";
BA_ "GenSigSendType" SG_ 785 RLR_IALWarnFL 1;
BA_ "Remark" SG_ 785 RRR_ExMirLedWarnR "";
BA_ "GenSigSendType" SG_ 785 RRR_ExMirLedWarnR 1;
BA_ "Remark" SG_ 785 RRR_VibrWarnR "";
BA_ "GenSigSendType" SG_ 785 RRR_VibrWarnR 1;
BA_ "Remark" SG_ 785 RRR_IALWarnRR "";
BA_ "GenSigSendType" SG_ 785 RRR_IALWarnRR 1;
BA_ "Remark" SG_ 785 RRR_IALWarnFR "";
BA_ "GenSigSendType" SG_ 785 RRR_IALWarnFR 1;
BA_ "GenSigTimeoutValue" SG_ 785 RRR_MRRSt 2;
BA_ "Remark" SG_ 785 RRR_MRRSt "";
BA_ "GenSigSendType" SG_ 785 RRR_MRRSt 1;
BA_ "GenSigTimeoutValue" SG_ 785 RRR_ClusterLamp 1;
BA_ "Remark" SG_ 785 RRR_ClusterLamp "";
BA_ "GenSigSendType" SG_ 785 RRR_ClusterLamp 1;
BA_ "Remark" SG_ 439 PCU_RejectHeatProtectINH_OH "";
BA_ "GenSigSendType" SG_ 439 PCU_RejectHeatProtectINH_OH 1;
BA_ "Remark" SG_ 439 PCU_UnlockFault "";
BA_ "GenSigSendType" SG_ 439 PCU_UnlockFault 1;
BA_ "Remark" SG_ 439 PCU_LockFault "";
BA_ "GenSigSendType" SG_ 439 PCU_LockFault 1;
BA_ "Remark" SG_ 439 PCU_LampRequest "";
BA_ "GenSigSendType" SG_ 439 PCU_LampRequest 1;
BA_ "Remark" SG_ 762 HOD_HeatingTempOutSt "";
BA_ "GenSigSendType" SG_ 762 HOD_HeatingTempOutSt 1;
BA_ "Remark" SG_ 762 HOD_HeatingThermSt "";
BA_ "GenSigSendType" SG_ 762 HOD_HeatingThermSt 1;
BA_ "Remark" SG_ 762 HOD_HeatingOverUnderCurrentSt "";
BA_ "GenSigSendType" SG_ 762 HOD_HeatingOverUnderCurrentSt 1;
BA_ "Remark" SG_ 762 HOD_HeatingOtherFaultSt "";
BA_ "GenSigSendType" SG_ 762 HOD_HeatingOtherFaultSt 1;
BA_ "Remark" SG_ 762 HOD_VBattOORFault "";
BA_ "GenSigSendType" SG_ 762 HOD_VBattOORFault 1;
BA_ "Remark" SG_ 762 HOD_FaultSt "";
BA_ "GenSigSendType" SG_ 762 HOD_FaultSt 1;
BA_ "Remark" SG_ 762 HOD_LINComFault "";
BA_ "GenSigSendType" SG_ 762 HOD_LINComFault 1;
BA_ "Remark" SG_ 762 HOD_CalibrationSt "";
BA_ "GenSigSendType" SG_ 762 HOD_CalibrationSt 1;
BA_ "Remark" SG_ 762 HOD_ApRestSt "";
BA_ "GenSigSendType" SG_ 762 HOD_ApRestSt 1;
BA_ "Remark" SG_ 762 HOD_HeatingSt "";
BA_ "GenSigSendType" SG_ 762 HOD_HeatingSt 1;
BA_ "Remark" SG_ 762 HOD_TouchZone3 "";
BA_ "GenSigSendType" SG_ 762 HOD_TouchZone3 1;
BA_ "Remark" SG_ 762 HOD_TouchZone2 "";
BA_ "GenSigSendType" SG_ 762 HOD_TouchZone2 1;
BA_ "Remark" SG_ 762 HOD_TouchZone1 "";
BA_ "GenSigSendType" SG_ 762 HOD_TouchZone1 1;
BA_ "Remark" SG_ 728 CDC_ProhibitChangingMode "";
BA_ "GatewayedSignals" SG_ 728 CDC_ProhibitChangingMode 1;
BA_ "GenSigSendType" SG_ 728 CDC_ProhibitChangingMode 1;
BA_ "GenSigTimeoutValue" SG_ 728 CDC_WarningLampReq 1;
BA_ "Remark" SG_ 728 CDC_WarningLampReq "";
BA_ "GatewayedSignals" SG_ 728 CDC_WarningLampReq 1;
BA_ "GenSigSendType" SG_ 728 CDC_WarningLampReq 1;
BA_ "GenSigTimeoutValue" SG_ 728 CDC_CurrentDamperMode 4;
BA_ "Remark" SG_ 728 CDC_CurrentDamperMode "";
BA_ "GatewayedSignals" SG_ 728 CDC_CurrentDamperMode 1;
BA_ "GenSigSendType" SG_ 728 CDC_CurrentDamperMode 1;
BA_ "Remark" SG_ 1055 SBM_NMDataField "";
BA_ "GenSigSendType" SG_ 1055 SBM_NMDataField 1;
BA_ "Remark" SG_ 1055 SBM_NMWakeupOrignin "";
BA_ "GenSigSendType" SG_ 1055 SBM_NMWakeupOrignin 1;
BA_ "Remark" SG_ 1055 SBM_NMSleepAck "";
BA_ "GenSigSendType" SG_ 1055 SBM_NMSleepAck 1;
BA_ "Remark" SG_ 1055 SBM_NMSleepInd "";
BA_ "GenSigSendType" SG_ 1055 SBM_NMSleepInd 1;
BA_ "Remark" SG_ 1055 SBM_NMLimpHome "";
BA_ "GenSigSendType" SG_ 1055 SBM_NMLimpHome 1;
BA_ "Remark" SG_ 1055 SBM_NMRing "";
BA_ "GenSigSendType" SG_ 1055 SBM_NMRing 1;
BA_ "Remark" SG_ 1055 SBM_NMAlive "";
BA_ "GenSigSendType" SG_ 1055 SBM_NMAlive 1;
BA_ "Remark" SG_ 1055 SBM_NMDestAddress "";
BA_ "GenSigSendType" SG_ 1055 SBM_NMDestAddress 1;
BA_ "Remark" SG_ 781 SBM_WelcomeToken4 "";
BA_ "Remark" SG_ 781 SBM_WelcomeToken3 "";
BA_ "Remark" SG_ 781 SBM_WelcomeToken2 "";
BA_ "Remark" SG_ 781 SBM_WelcomeToken1 "";
BA_ "Remark" SG_ 1013 SBM_OpIndicationWarning "";
BA_ "GenSigSendType" SG_ 1013 SBM_OpIndicationWarning 1;
BA_ "Remark" SG_ 1013 SBM_phone_Number11 "";
BA_ "GenSigSendType" SG_ 1013 SBM_phone_Number11 1;
BA_ "Remark" SG_ 1013 SBM_phone_Number10 "";
BA_ "GenSigSendType" SG_ 1013 SBM_phone_Number10 1;
BA_ "Remark" SG_ 1013 SBM_phone_Number9 "";
BA_ "GenSigSendType" SG_ 1013 SBM_phone_Number9 1;
BA_ "Remark" SG_ 1013 SBM_phone_Number8 "";
BA_ "GenSigSendType" SG_ 1013 SBM_phone_Number8 1;
BA_ "Remark" SG_ 1013 SBM_phone_Number7 "";
BA_ "GenSigSendType" SG_ 1013 SBM_phone_Number7 1;
BA_ "Remark" SG_ 1013 SBM_phone_Number6 "";
BA_ "GenSigSendType" SG_ 1013 SBM_phone_Number6 1;
BA_ "Remark" SG_ 1013 SBM_phone_Number5 "";
BA_ "GenSigSendType" SG_ 1013 SBM_phone_Number5 1;
BA_ "Remark" SG_ 1013 SBM_phone_Number4 "";
BA_ "GenSigSendType" SG_ 1013 SBM_phone_Number4 1;
BA_ "Remark" SG_ 1013 SBM_phone_Number3 "";
BA_ "GenSigSendType" SG_ 1013 SBM_phone_Number3 1;
BA_ "Remark" SG_ 1013 SBM_phone_Number2 "";
BA_ "GenSigSendType" SG_ 1013 SBM_phone_Number2 1;
BA_ "Remark" SG_ 1013 SBM_phone_Number1 "";
BA_ "GenSigSendType" SG_ 1013 SBM_phone_Number1 1;
BA_ "Remark" SG_ 1013 SBM_Phone_Connectingst "";
BA_ "GenSigSendType" SG_ 1013 SBM_Phone_Connectingst 1;
BA_ "Remark" SG_ 1001 SBM_fatigueDringWarning "";
BA_ "GenSigSendType" SG_ 1001 SBM_fatigueDringWarning 1;
VAL_ 3221225472 ACU_FCWSeatbeltPretensionWarnCfg 3 "Not used" 2 "Active" 1 "Not active" 0 "No command" ;
VAL_ 3221225472 ACU_FCWSeatVibrationWarnCfg 3 "Not used" 2 "Active" 1 "Not active" 0 "No command" ;
VAL_ 3221225472 ACU_FCWAcousticWarnCfg 3 "Not used" 2 "Active" 1 "Not active" 0 "No command" ;
VAL_ 3221225472 ACU_ACCStyleCfg 3 "Sport" 2 "Comfortable" 1 "Standard" 0 "No command" ;
VAL_ 3221225472 ACU_BCMHornCfg 3 "Not used" 2 "Active" 1 "Not active" 0 "No command" ;
VAL_ 3221225472 ACU_BCMDTRLFuncCfg 3 "Not used" 2 "Active" 1 "Not active" 0 "No command" ;
VAL_ 3221225472 ACU_BCMRGearEnableRearWipeCfg 3 "Not used" 2 "Active" 1 "Not active" 0 "No command" ;
VAL_ 3221225472 ACU_BCMAutoLightSnsCfg 7 "Not used" 6 "Not used" 5 "Not used" 4 "Not used" 3 "Low sensitivity" 2 "Medium sensitivity" 1 "High sensitivity" 0 "No command" ;
VAL_ 3221225472 ACU_BCMFollowMeHomeCfg 3 "Low beam and rear fog lamp" 2 "Only low beam" 1 "Not active" 0 "No command" ;
VAL_ 3221225472 ACU_BCMAutoUnlockCfg 3 "Not used" 2 "Active" 1 "Not active" 0 "No command" ;
VAL_ 3221225472 ACU_BCMRemoteUnlockCfg 3 "Not used" 2 "Only driver door" 1 "All doors" 0 "No command" ;
VAL_ 3221225472 ACU_BCMFogLampTurnCfg 3 "Not used" 2 "Active" 1 "Not active" 0 "No command" ;
VAL_ 3221225472 ACU_BCMRemoteCtrlFDMRMCfg 3 "Not used" 2 "Active" 1 "Not active" 0 "No command" ;
VAL_ 3221225472 ACU_KickSnsCfg 3 "Not used" 2 "Active" 1 "Not active" 0 "No command" ;
VAL_ 3221225472 ACU_MaxTeleEngTimerCfg 63 "No command" 62 "Reserved" 61 "Reserved" 60 "Reserved" 59 "Reserved" 58 "Reserved" 57 "Reserved" 56 "Reserved" 55 "Reserved" 54 "Reserved" 53 "Reserved" 52 "Reserved" 51 "Reserved" 50 "Reserved" 49 "Reserved" 48 "Reserved" 47 "Reserved" 46 "Reserved" 45 "Reserved" 44 "Reserved" 43 "Reserved" 42 "Reserved" 41 "Reserved" 40 "Reserved" 39 "Reserved" 38 "Reserved" 37 "Reserved" 36 "Reserved" 35 "Reserved" 34 "Reserved" 33 "Reserved" 32 "Reserved" 31 "Reserved" ;
VAL_ 3221225472 ACU_PEPSOffCfg 3 "Not used" 2 "Active" 1 "Not active" 0 "No command" ;
VAL_ 3221225472 ACU_MaxTeleIGNOnTimerCfg 63 "No command" 62 "Reserved" 61 "Reserved" 60 "Reserved" 59 "Reserved" 58 "Reserved" 57 "Reserved" 56 "Reserved" 55 "Reserved" 54 "Reserved" 53 "Reserved" 52 "Reserved" 51 "Reserved" 50 "Reserved" 49 "Reserved" 48 "Reserved" 47 "Reserved" 46 "Reserved" 45 "Reserved" 44 "Reserved" 43 "Reserved" 42 "Reserved" 41 "Reserved" 40 "Reserved" 39 "Reserved" 38 "Reserved" 37 "Reserved" 36 "Reserved" 35 "Reserved" 34 "Reserved" 33 "Reserved" 32 "Reserved" 31 "Reserved" ;
VAL_ 3221225472 ACU_PEPSAPUCfg 3 "Not used" 2 "Active" 1 "Not active" 0 "No command" ;
VAL_ 3221225472 ACU_PEPSWALCfg 3 "Not used" 2 "Active" 1 "Not active" 0 "No command" ;
VAL_ 3221225472 ACU_ICMLanguageCfg 3 "Not used" 2 "English" 1 "Chinese" 0 "No command" ;
VAL_ 3221225472 ACU_ICMTimeModeCfg 3 "Not used" 2 "12h mode" 1 "24h mode" 0 "No command" ;
VAL_ 3221225472 ACU_ICMWarnSoundVolCfg 3 "High" 2 "Middle" 1 "Low" 0 "No command" ;
VAL_ 3221225472 ACU_ICMSpdWarnCfg 31 "No command" 30 "Reserved" 29 "Reserved" 28 "Reserved" 27 "Reserved" 26 "Reserved" 25 "Reserved" 24 "Reserved" 23 "Reserved" 22 "Reserved" 21 "Reserved" ;
VAL_ 3221225472 ACU_PEPSSATOCfg 3 "SATO function  and sound reminder active" 2 "SATO function Active" 1 "Not active" 0 "No command" ;
VAL_ 3221225472 ACU_PEPSWELCfg 3 "Not used" 2 "Active" 1 "Not active" 0 "No command" ;
VAL_ 3221225472 ACU_BCMOSRMAutoFoldCfg 3 "Not used" 2 "Active" 1 "Not active" 0 "No command" ;
VAL_ 3221225472 ACU_MSMKeyRecognitionCfg 3 "Not used" 2 "Active" 1 "Not active" 0 "No command" ;
VAL_ 3221225472 ACU_MSMWelcomeFuncCfg 3 "Not used" 2 "Active" 1 "Not active" 0 "No command" ;
VAL_ 3221225472 ACU_HVACFComfortCfg 3 "Fast" 2 "Normal" 1 "Soft" 0 "No command" ;
VAL_ 3221225472 ACU_HVACFAirCirCfg 3 "Not used" 2 "Manual air circulation" 1 "Auto air circulation" 0 "No command" ;
VAL_ 3221225472 ACU_HVACFACCfg 3 "Not used" 2 "A/C auto on turn off" 1 "A/C auto on turn on" 0 "No command" ;
VAL_ 3221225472 ACU_LDW_WarnSnsCfg 3 "Delay" 2 "Self-adaption" 1 "Early" 0 "No command" ;
VAL_ 3221225472 TEL_BTAvrcpPlayMode 7 "Not used" 6 "Not used" 5 "REW" 4 "FFW" 3 "Stop" 2 "Pause" 1 "Playing" 0 "Not active" ;
VAL_ 3221225472 TEL_BTAutoconectingSt 1 "Connecting" 0 "No connecting" ;
VAL_ 3221225472 TEL_BTPowerSt 1 "Power on" 0 "Power off" ;
VAL_ 3221225472 TEL_BTManualMode 3 "Not used" 2 "Manual out" 1 "Manual in" 0 "No operate" ;
VAL_ 3221225472 TEL_BTHisdel 1 "Delete" 0 "Not delete" ;
VAL_ 3221225472 TEL_BTHandfreeSt 1 "Handfree" 0 "Private" ;
VAL_ 3221225472 TEL_BTAvrcpSt 1 "AVRCP active" 0 "AVRCP inactive" ;
VAL_ 3221225472 TEL_TelematicsModeActSt 7 "Not used" 6 "Not used" 5 "Not used" 4 "Ecall Mode" 3 "Bcall Mode" 2 "Bluetooth mode" 1 "TBOX mode" 0 "Not active" ;
VAL_ 3221225472 ACU_EVSwRq 3 "Reserved" 2 "On" 1 "OFF" 0 "No command" ;
VAL_ 3221225472 PAS_Mode 7 "Invalid" 6 "Not used" 5 "System Failure" 4 "Rear Active" 3 "Front Active" 2 "Front Rear Active " 1 "Standby" 0 "Off" ;
VAL_ 3221225472 ACU_IFC_ZoneCode 7 "Not sued" 6 "Not sued" 5 "Not sued" 4 "Not sued" 3 "Not sued" 2 "Not sued" 1 "China" 0 "No command" ;
VAL_ 3221225472 ACU_IFC_SpeedLimitUnit 3 "Not used" 2 "Miles/h" 1 "Km/h" 0 "No command" ;
VAL_ 3221225472 ACU_IFC_RoadType 15 "Not used" 14 "Not used" 13 "Village road" 12 "County road" 11 "Fairway" 10 "Planned road" 9 "Path #2" 8 "Path #1" 7 "Normal urban road" 6 "Secondary urban road" 5 "Major urban road" 4 "Provincial road" 3 "City express way" 2 "National road" 1 "High way" 0 "No command" ;
VAL_ 3221225472 ICM_TripBVD 1 "Valid" 0 "Not valid" ;
VAL_ 3221225472 ICM_TripAVD 1 "Valid" 0 "Not valid" ;
VAL_ 886 BCS_ESPFuncResp 3 "ESP failure" 2 "ESP OFF " 1 "TCS Off" 0 "ESP on" ;
VAL_ 832 EMS_FuleCapAjarSt 1 "open" 0 "Closed" ;
VAL_ 832 EMS_FuelPressureReleaseStDis 7 "Reserved" 6 "Reserved" 5 "Reserved" 4 "Reserved" 3 "Failed" 2 "Complete" 1 "Releasing" 0 "Not request" ;
VAL_ 350 IMR_Error 1 "System Error" 0 "System No Error" ;
VAL_ 912 VCU_VehDrvModNew 6 "reserved;" 5 "SPORT Mode;" 4 "Individual mode;" 3 "Comfort Mode;" 2 "ECO Mode;" 1 "reserved;" 0 "Invalid;" ;
VAL_ 811 VCU_VehChgDischgSt 37 "Reserved" 36 "FuelLvlLowDischargeUnavailable" 35 "BattSOCLowDischargeUnavailable" 34 "SOC is low, EngineisGoingtoStart" 33 "DischFailed,PlsRstDischgSOC" 32 "VoltHigh,PlsChgtoAnotherDC" 31 "VoltHigh,PlsChgtoACorAnother" 30 "AttentionPls,PlugLockFailed" 29 "PlugLockFailed,PwrReductionChg" 28 "ExternalEquipOverload" 27 "WaitForChgAppointmnt" 26 "ChgDischgSysFault" 25 "RemoveConnectorBeforeShiftGears" 24 "Operating mistake, PlsReoperate" 23 "UnlockSucceedPlsRemoveConnct" 22 "PlugUnlockFailed,PlsUnlockAgain" 21 "FuncStrtFail,PlsReoperate" 20 "Pls Check connector" 19 "CnnctOverTemp, plsChangeChrgPort" 18 "Pls connenct load" 17 "Move shift to P before charge" 16 "Remove connector before start" 15 "SOC low,PlsPoweroffBeforePlug-in" 14 "Battery heating" 13 "low power,attention pls" 12 "Facility fault，pls change" 11 "LowPowerPlsWait" 10 "Discharging System fault" 9 "Stop Discharging" 8 "Discharging" 7 "PowerEquipmStopWorking" 6 "Charge system fault" 5 "facilities voltage low" 4 "charge end" 3 "Fully charged" 2 "Charging" 1 "Preparing" 0 "No message" ;
VAL_ 848 VCU_PrecResHotMsg 3 "Reserved" 2 "Allow re-powered up" 1 "FrequentOperation,tryAgainLater" 0 "No Fault" ;
VAL_ 848 VCU_ChgTimeDspType 3 "Invalid time" 2 "Charging" 1 "Book charge" 0 "Null" ;
VAL_ 848 VCU_PlgConnSt 1 "Plus connector connected" 0 "Not Connected" ;
VAL_ 848 VCU_EVButtonNoticeDisp 1 "Displayed(EV mode is unavailable)" 0 "Not Displayed" ;
VAL_ 848 VCU_DerateLampSt 3 "Not used" 2 "Lamp Blink" 1 "Lamp on" 0 "Lamp off" ;
VAL_ 848 VCU_EVSt 1 "ON" 0 "OFF" ;
VAL_ 848 VCU_VehAvailDriveStMsgWarn 1 "Available drive state warn" 0 "No request" ;
VAL_ 848 VCU_OperatingMode 7 "Not used" 6 "Not used" 5 "Not used" 4 "Not used" 3 "electicity conservation " 2 "electicity drive first" 1 "Intelligent hybrid" 0 "Normal mode" ;
VAL_ 848 VCU_VehDrvMod 6 "I-pedal Mode(reserved" 5 "SPORT Mode" 4 "Driving Mode(reserved)" 3 "Comfort Mode" 2 "ECO Mode" 1 "ECO+ Mode(reserved)" 0 "reserved" ;
VAL_ 908 VCU_BookChgLampInd 3 "Reserved" 2 "White lamp" 1 "Green lamp" 0 "Lamp off" ;
VAL_ 863 TEL_BTManualMode 3 "Not used" 2 "Manual out" 1 "Manual in" 0 "No operate" ;
VAL_ 863 TEL_BTAvrcpSt 1 "AVRCP active" 0 "AVRCP inactive" ;
VAL_ 863 TEL_BTAvrcpPlayMode 7 "Not used" 6 "Not used" 5 "REW" 4 "FFW" 3 "Stop" 2 "Pause" 1 "Playing" 0 "Not active" ;
VAL_ 863 TEL_BTHandfreeSt 1 "Handfree" 0 "Private" ;
VAL_ 863 TEL_BTHisdel 1 "Delete" 0 "Not delete" ;
VAL_ 863 TEL_BTAutoconectingSt 1 "Connecting" 0 "No connecting" ;
VAL_ 863 TEL_BTPowerSt 1 "Power on" 0 "Power off" ;
VAL_ 863 TEL_TelematicsModeActSt 7 "Not used" 6 "Not used" 5 "Not used" 4 "Ecall Mode" 3 "Bcall Mode" 2 "Bluetooth mode" 1 "TBOX mode" 0 "Not active" ;
VAL_ 638 VCU_ChgActiveSt 1 "charging" 0 "not charging" ;
VAL_ 638 VCU_PlugAutoUnlockCfgResp 1 " auto unlock" 0 " not auto unlock" ;
VAL_ 638 VCU_DischgEngStartPermit 1 "Enable" 0 " Disable" ;
VAL_ 638 VCU_DischgActiveSt 1 "Discharge active" 0 "Discharge inactive" ;
VAL_ 1075 HVSPRR_NMSleepAck 1 "Active" 0 "Not active" ;
VAL_ 1075 HVSPRR_NMSleepInd 1 "Active" 0 "Not active" ;
VAL_ 1075 HVSPRR_NMLimpHome 1 "Active" 0 "Not active" ;
VAL_ 1075 HVSPRR_NMRing 1 "Active" 0 "Not active" ;
VAL_ 1075 HVSPRR_NMAlive 1 "Active" 0 "Not active" ;
VAL_ 1074 HVSPRL_NMSleepAck 1 "Active" 0 "Not active" ;
VAL_ 1074 HVSPRL_NMSleepInd 1 "Active" 0 "Not active" ;
VAL_ 1074 HVSPRL_NMLimpHome 1 "Active" 0 "Not active" ;
VAL_ 1074 HVSPRL_NMRing 1 "Active" 0 "Not active" ;
VAL_ 1074 HVSPRL_NMAlive 1 "Active" 0 "Not active" ;
VAL_ 558 HVSPRR_RR_Freezepemissions_FuncC 3 "not used" 2 "not used" 1 "lock" 0 "unlock" ;
VAL_ 558 HVSPRR_RRSPABUttonSt 3 "not used" 2 "not used" 1 "ON" 0 "OFF" ;
VAL_ 557 HVSPRL_RL_Freezepemissions_FuncC 3 "not used" 2 "not used" 1 "lock" 0 "unlock" ;
VAL_ 557 HVSPRL_RLSPABUttonSt 3 "not used" 2 "not used" 1 "ON" 0 "OFF" ;
VAL_ 1123 MSM_NMWakeupOrignin 255 "Reserved" 254 "Reserved" 253 "Reserved" 252 "Reserved" 251 "Reserved" 250 "Reserved" 249 "Reserved" 248 "Reserved" 247 "Reserved" 246 "Reserved" 245 "Reserved" 244 "Reserved" 243 "Reserved" 242 "Reserved" 241 "Reserved" 240 "Reserved" 239 "Reserved" 238 "Reserved" 237 "Reserved" 236 "Reserved" 235 "Reserved" 234 "Reserved" 233 "Reserved" 232 "Reserved" 231 "Reserved" 230 "Reserved" 229 "Reserved" 228 "Reserved" 227 "Reserved" 226 "Reserved" 225 "Reserved" 224 "Reserved" 223 "Reserved" 222 "Reserved" 221 "Reserved" 220 "Reserved" 219 "Reserved" 218 "Reserved" 217 "Reserved" 216 "Reserved" 215 "Reserved" 214 "Reserved" 213 "Reserved" 212 "Reserved" 211 "Reserved" 210 "Reserved" 209 "Reserved" 208 "Reserved" 207 "Reserved" 206 "Reserved" 205 "Reserved" 204 "Reserved" 203 "Reserved" 202 "Reserved" 201 "Reserved" 200 "Reserved" 199 "Reserved" 198 "Reserved" 197 "Reserved" 196 "Reserved" 195 "Reserved" 194 "Reserved" 193 "Reserved" 192 "Reserved" 191 "Reserved" 190 "Reserved" 189 "Reserved" 188 "Reserved" 187 "Reserved" 186 "Reserved" 185 "Reserved" 184 "Reserved" 183 "Reserved" 182 "Reserved" 181 "Reserved" 180 "Reserved" 179 "Reserved" 178 "Reserved" 177 "Reserved" 176 "Reserved" 175 "Reserved" 174 "Reserved" 173 "Reserved" 172 "Reserved" 171 "Reserved" 170 "Reserved" 169 "Reserved" 168 "Reserved" 167 "Reserved" 166 "Reserved" 165 "Reserved" 164 "Reserved" 163 "Reserved" 162 "Reserved" 161 "Reserved" 160 "Reserved" 159 "Reserved" 158 "Reserved" 157 "Reserved" 156 "Reserved" 155 "Reserved" 154 "Reserved" 153 "Reserved" 152 "Reserved" 151 "Reserved" 150 "Reserved" 149 "Reserved" 148 "Reserved" 147 "Reserved" 146 "Reserved" 145 "Reserved" 144 "Reserved" 143 "Reserved" 142 "Reserved" 141 "Reserved" 140 "Reserved" 139 "Reserved" 138 "Reserved" 137 "Reserved" 136 "Reserved" 135 "Reserved" 134 "Reserved" 133 "Reserved" 132 "Reserved" 131 "Reserved" 130 "Reserved" 129 "Reserved" 128 "Reserved" 127 "Reserved" 126 "Reserved" 125 "Reserved" 124 "Reserved" 123 "Reserved" 122 "Reserved" 121 "Reserved" 120 "Reserved" 119 "Reserved" 118 "Reserved" 117 "Reserved" 116 "Reserved" 115 "Reserved" 114 "Reserved" 113 "Reserved" 112 "Reserved" 111 "Reserved" 110 "Reserved" 109 "Reserved" 108 "Reserved" 107 "Reserved" 106 "Reserved" 105 "Reserved" 104 "Reserved" 103 "Reserved" 102 "Reserved" 101 "Reserved" 100 "Reserved" 99 "Reserved" 98 "Reserved" 97 "Reserved" 96 "Reserved" 95 "Reserved" 94 "Reserved" 93 "Reserved" 92 "Reserved" 91 "Reserved" 90 "Reserved" 89 "Reserved" 88 "Reserved" 87 "Reserved" 86 "Reserved" 85 "Reserved" 84 "Seat sdjust switch" 83 "Rear view mirror adjust switch" 82 "Not used" 81 "Not used" 80 "Not used" 79 "Not used" 78 "Not used" 77 "Not used" 76 "Not used" 75 "Not used" 74 "Not used" 73 "Not used" 72 "Not used" 71 "Not used" 70 "Not used" 69 "Not used" 68 "Not used" 67 "Not used" 66 "Not used" 65 "Not used" 64 "Not used" 63 "Not used" 62 "Not used" 61 "Not used" 60 "Not used" 59 "Not used" 58 "Not used" 57 "Not used" 56 "Not used" 55 "Not used" 54 "Not used" 53 "Not used" 52 "Not used" 51 "Not used" 50 "Not used" 49 "Not used" 48 "Not used" 47 "Not used" 46 "Not used" 45 "Not used" 44 "Not used" 43 "Not used" 42 "Not used" 41 "Not used" 40 "Not used" 39 "Not used" 38 "Not used" 37 "Not used" 36 "Not used" 35 "Not used" 34 "Not used" 33 "Not used" 32 "Not used" 31 "Not used" 30 "Not used" 29 "Not used" 28 "Not used" 27 "Not used" 26 "Not used" 25 "Not used" 24 "Not used" 23 "Not used" 22 "Not used" 21 "Not used" 20 "Not used" 19 "Not used" 18 "IGN ON" 17 "Not used" 16 "Not used" 15 "Not used" 14 "Not used" 13 "Not used" 12 "Not used" 11 "Not used" 10 "Not used" 9 "Not used" 8 "Not used" 7 "Not used" 6 "Not used" 5 "Not used" 4 "Not used" 3 "Not used" 2 "Not used" 1 "Message wake up" ;
VAL_ 1123 MSM_NMSleepAck 1 "Active" 0 "Not active" ;
VAL_ 1123 MSM_NMSleepInd 1 "Active" 0 "Not active" ;
VAL_ 1123 MSM_NMLimpHome 1 "Active" 0 "Not active" ;
VAL_ 1123 MSM_NMRing 1 "Active" 0 "Not active" ;
VAL_ 1123 MSM_NMAlive 1 "Active" 0 "Not active" ;
VAL_ 764 MSM_RRSeatRecoveryModeSt 3 "Not used" 2 "Recovery Mode" 1 "Recovery Setting Mode" 0 "Not in Recoverymode" ;
VAL_ 764 MSM_RRSeatSpaModeSt 3 "Not used" 2 "Spa Mode" 1 "Spa Setting Mode" 0 "Not in Spamode" ;
VAL_ 764 MSM_RRSeatMemoryModeSt 3 "Not used" 2 "Memory Mode" 1 "Memory Setting Mode" 0 "Not in Memorymode" ;
VAL_ 764 MSM_RRSeatVoiceCtrlResp 15 "Not used" 14 "Not used" 13 "Stop" 12 "Shoulder backward" 11 "Shoulder forward" 10 "Ottoman1 backward" 9 "Ottoman1 forward" 8 "Ottoman1 backward" 7 "Ottoman1 forward" 6 "Lift down" 5 "Lift up" 4 "Back backward" 3 "Back forward" 2 "Slide backward" 1 "Slide forward" 0 "No response" ;
VAL_ 764 MSM_RRSeatOperationSt 15 "Not used" 14 "Not used" 13 "Not used" 12 "Not used" 11 "Not used" 10 "Study Failed" 9 "Study Completed" 8 "Studying" 7 "Initialization Completed" 6 "Recall Completed" 5 "Recall Interrupted" 4 "Recalling" 3 "Save Failed" 2 "Save Completed" 1 "Manual Operating" 0 "No Operation" ;
VAL_ 764 MSM_RRSeatSlidepositionSensorSig 3 "Open circuit Fault" 2 "Short circuit fault" 1 "ON" 0 "OFF" ;
VAL_ 764 MSM_RRSlideLockSwitch2Sig 3 "Open circuit Fault" 2 "Short circuit fault" 1 "Lock SW" 0 "Unlock SW" ;
VAL_ 764 MSM_RRSlideLockSwitch1Sig 3 "Open circuit Fault" 2 "Short circuit fault" 1 "Lock SW" 0 "Unlock SW" ;
VAL_ 764 MSM_RRSeatMemoryModePositionSt 1 "Stored" 0 "No stored" ;
VAL_ 764 MSM_RRSeatWelcomeFuncCfgSt 1 "Active" 0 "Not active" ;
VAL_ 1084 MSM_NMWakeupOrignin 255 "Reserved" 254 "Reserved" 253 "Reserved" 252 "Reserved" 251 "Reserved" 250 "Reserved" 249 "Reserved" 248 "Reserved" 247 "Reserved" 246 "Reserved" 245 "Reserved" 244 "Reserved" 243 "Reserved" 242 "Reserved" 241 "Reserved" 240 "Reserved" 239 "Reserved" 238 "Reserved" 237 "Reserved" 236 "Reserved" 235 "Reserved" 234 "Reserved" 233 "Reserved" 232 "Reserved" 231 "Reserved" 230 "Reserved" 229 "Reserved" 228 "Reserved" 227 "Reserved" 226 "Reserved" 225 "Reserved" 224 "Reserved" 223 "Reserved" 222 "Reserved" 221 "Reserved" 220 "Reserved" 219 "Reserved" 218 "Reserved" 217 "Reserved" 216 "Reserved" 215 "Reserved" 214 "Reserved" 213 "Reserved" 212 "Reserved" 211 "Reserved" 210 "Reserved" 209 "Reserved" 208 "Reserved" 207 "Reserved" 206 "Reserved" 205 "Reserved" 204 "Reserved" 203 "Reserved" 202 "Reserved" 201 "Reserved" 200 "Reserved" 199 "Reserved" 198 "Reserved" 197 "Reserved" 196 "Reserved" 195 "Reserved" 194 "Reserved" 193 "Reserved" 192 "Reserved" 191 "Reserved" 190 "Reserved" 189 "Reserved" 188 "Reserved" 187 "Reserved" 186 "Reserved" 185 "Reserved" 184 "Reserved" 183 "Reserved" 182 "Reserved" 181 "Reserved" 180 "Reserved" 179 "Reserved" 178 "Reserved" 177 "Reserved" 176 "Reserved" 175 "Reserved" 174 "Reserved" 173 "Reserved" 172 "Reserved" 171 "Reserved" 170 "Reserved" 169 "Reserved" 168 "Reserved" 167 "Reserved" 166 "Reserved" 165 "Reserved" 164 "Reserved" 163 "Reserved" 162 "Reserved" 161 "Reserved" 160 "Reserved" 159 "Reserved" 158 "Reserved" 157 "Reserved" 156 "Reserved" 155 "Reserved" 154 "Reserved" 153 "Reserved" 152 "Reserved" 151 "Reserved" 150 "Reserved" 149 "Reserved" 148 "Reserved" 147 "Reserved" 146 "Reserved" 145 "Reserved" 144 "Reserved" 143 "Reserved" 142 "Reserved" 141 "Reserved" 140 "Reserved" 139 "Reserved" 138 "Reserved" 137 "Reserved" 136 "Reserved" 135 "Reserved" 134 "Reserved" 133 "Reserved" 132 "Reserved" 131 "Reserved" 130 "Reserved" 129 "Reserved" 128 "Reserved" 127 "Reserved" 126 "Reserved" 125 "Reserved" 124 "Reserved" 123 "Reserved" 122 "Reserved" 121 "Reserved" 120 "Reserved" 119 "Reserved" 118 "Reserved" 117 "Reserved" 116 "Reserved" 115 "Reserved" 114 "Reserved" 113 "Reserved" 112 "Reserved" 111 "Reserved" 110 "Reserved" 109 "Reserved" 108 "Reserved" 107 "Reserved" 106 "Reserved" 105 "Reserved" 104 "Reserved" 103 "Reserved" 102 "Reserved" 101 "Reserved" 100 "Reserved" 99 "Reserved" 98 "Reserved" 97 "Reserved" 96 "Reserved" 95 "Reserved" 94 "Reserved" 93 "Reserved" 92 "Reserved" 91 "Reserved" 90 "Reserved" 89 "Reserved" 88 "Reserved" 87 "Reserved" 86 "Reserved" 85 "Reserved" 84 "Seat sdjust switch" 83 "Rear view mirror adjust switch" 82 "Not used" 81 "Not used" 80 "Not used" 79 "Not used" 78 "Not used" 77 "Not used" 76 "Not used" 75 "Not used" 74 "Not used" 73 "Not used" 72 "Not used" 71 "Not used" 70 "Not used" 69 "Not used" 68 "Not used" 67 "Not used" 66 "Not used" 65 "Not used" 64 "Not used" 63 "Not used" 62 "Not used" 61 "Not used" 60 "Not used" 59 "Not used" 58 "Not used" 57 "Not used" 56 "Not used" 55 "Not used" 54 "Not used" 53 "Not used" 52 "Not used" 51 "Not used" 50 "Not used" 49 "Not used" 48 "Not used" 47 "Not used" 46 "Not used" 45 "Not used" 44 "Not used" 43 "Not used" 42 "Not used" 41 "Not used" 40 "Not used" 39 "Not used" 38 "Not used" 37 "Not used" 36 "Not used" 35 "Not used" 34 "Not used" 33 "Not used" 32 "Not used" 31 "Not used" 30 "Not used" 29 "Not used" 28 "Not used" 27 "Not used" 26 "Not used" 25 "Not used" 24 "Not used" 23 "Not used" 22 "Not used" 21 "Not used" 20 "Not used" 19 "Not used" 18 "IGN ON" 17 "Not used" 16 "Not used" 15 "Not used" 14 "Not used" 13 "Not used" 12 "Not used" 11 "Not used" 10 "Not used" 9 "Not used" 8 "Not used" 7 "Not used" 6 "Not used" 5 "Not used" 4 "Not used" 3 "Not used" 2 "Not used" 1 "Message wake up" ;
VAL_ 1084 MSM_NMSleepAck 1 "Active" 0 "Not active" ;
VAL_ 1084 MSM_NMSleepInd 1 "Active" 0 "Not active" ;
VAL_ 1084 MSM_NMLimpHome 1 "Active" 0 "Not active" ;
VAL_ 1084 MSM_NMRing 1 "Active" 0 "Not active" ;
VAL_ 1084 MSM_NMAlive 1 "Active" 0 "Not active" ;
VAL_ 767 MSM_RLSeatRecoveryModeSt 3 "Not used" 2 "Recovery Mode" 1 "Recovery Setting Mode" 0 "Not in Recoverymode" ;
VAL_ 767 MSM_RLSeatSpaModeSt 3 "Not used" 2 "Spa Mode" 1 "Spa Setting Mode" 0 "Not in Spamode" ;
VAL_ 767 MSM_RLSeatMemoryModeSt 3 "Not used" 2 "Memory Mode" 1 "Memory Setting Mode" 0 "Not in Memorymode" ;
VAL_ 767 MSM_RLSeatVoiceCtrlResp 15 "Not used" 14 "Not used" 13 "Stop" 12 "Shoulder backward" 11 "Shoulder forward" 10 "Ottoman1 backward" 9 "Ottoman1 forward" 8 "Ottoman1 backward" 7 "Ottoman1 forward" 6 "Lift down" 5 "Lift up" 4 "Back backward" 3 "Back forward" 2 "Slide backward" 1 "Slide forward" 0 "No response" ;
VAL_ 767 MSM_RLSeatOperationSt 15 "Not used" 14 "Not used" 13 "Not used" 12 "Not used" 11 "Not used" 10 "Study Failed" 9 "Study Completed" 8 "Studying" 7 "Initialization Completed" 6 "Recall Completed" 5 "Recall Interrupted" 4 "Recalling" 3 "Save Failed" 2 "Save Completed" 1 "Manual Operating" 0 "No Operation" ;
VAL_ 767 MSM_RLSeatSlidepositionSensorSig 3 "Open circuit Fault" 2 "Short circuit fault" 1 "ON" 0 "OFF" ;
VAL_ 767 MSM_RLSlideLockSwitch2Sig 3 "Open circuit Fault" 2 "Short circuit fault" 1 "Lock SW" 0 "Unlock SW" ;
VAL_ 767 MSM_RLSlideLockSwitch1Sig 3 "Open circuit Fault" 2 "Short circuit fault" 1 "Lock SW" 0 "Unlock SW" ;
VAL_ 767 MSM_RLSeatMemoryModePositionSt 1 "Stored" 0 "No stored" ;
VAL_ 767 MSM_RLSeatWelcomeFuncCfgSt 1 "Active" 0 "Not active" ;
VAL_ 866 PSDR_BuzzerRequest 15 "Not used;" 14 "Not used;" 13 "Not used;" 12 "Not used;" 11 "Not used;" 10 "Not used;" 9 "Not used;" 8 "Not used;" 7 "Not used;" 6 "Not used;" 5 "故障buzzer(Type7)" 4 "行驶buzzer(Type7)" 3 "強制停止(Type2) ※2" 2 "防夹buzzer(Type1) ※2" 1 "起动buzzer(Type1) ※2" 0 "Terminate(停止)" ;
VAL_ 866 PSDR_DoorSpdst 3 "not used;" 2 "high speed;" 1 "low speed;" 0 "not value;" ;
VAL_ 866 PSDR_FuelOpenSt 1 "Forbidden" 0 "Premission" ;
VAL_ 866 PSDR_MainSWOffForbSt 1 "Forbidden" 0 "Premission" ;
VAL_ 866 PSD_ModeSt 3 "not used" 2 "not used" 1 "power slide door" 0 "Manual slide door" ;
VAL_ 866 PSDR_PinchDet 1 "pinch detected" 0 "not detected" ;
VAL_ 866 PSDR_OperationMode 7 "Not used;" 6 "Not used;" 5 "Not used;" 4 "Not used;" 3 "Closing;" 2 "Openning;" 1 "Stop；" 0 "Initial Mode;" ;
VAL_ 866 PSDR_DoorPst 7 "Not used;" 6 "Not used;" 5 "Not used;" 4 "Not used;" 3 "Not used;" 2 "Latch Open;" 1 "Half Latch;" 0 "Full Latch;" ;
VAL_ 865 PSDL_BuzzerRequest 15 "Not used;" 14 "Not used;" 13 "Not used;" 12 "Not used;" 11 "Not used;" 10 "Not used;" 9 "Not used;" 8 "Not used;" 7 "Not used;" 6 "Not used;" 5 "故障buzzer(Type7)" 4 "行驶buzzer(Type7)" 3 "強制停止(Type2) ※2" 2 "防夹buzzer(Type1) ※2" 1 "起动buzzer(Type1) ※2" 0 "Terminate(停止)" ;
VAL_ 865 PSDL_DoorSpdst 3 "not used;" 2 "high speed;" 1 "low speed;" 0 "not value;" ;
VAL_ 865 PSDL_FuelOpenSt 1 "Forbidden" 0 "Premission" ;
VAL_ 865 PSDL_MainSWOffForbSt 1 "Forbidden" 0 "Premission" ;
VAL_ 865 PSDL_PinchDet 1 "pinch detected" 0 "not detected" ;
VAL_ 865 PSDL_OperationMode 7 "Not used;" 6 "Not used;" 5 "Not used;" 4 "Not used;" 3 "Closing;" 2 "Openning;" 1 "Stop；" 0 "Initial Mode;" ;
VAL_ 865 PSDL_DoorPst 7 "Not used;" 6 "Not used;" 5 "Not used;" 4 "Not used;" 3 "Not used;" 2 "Latch Open;" 1 "Half Latch;" 0 "Full Latch;" ;
VAL_ 1003 AVAS_ActivatedSt 1 "ON" 0 "OFF" ;
VAL_ 118 TEL_ModuleResetSt 3 "Not used" 2 "Pass" 1 "Fail" 0 "Default" ;
VAL_ 860 TEL_AVRCPSupportSt 1 "Support" 0 "Not support" ;
VAL_ 860 TEL_A2DPSupportSt 1 "Support" 0 "Not support" ;
VAL_ 860 TEL_PhoneCallSt 7 "Not used" 6 "Calls over" 5 "Hang up" 4 "On the phone" 3 "Answer calls" 2 "Connecting" 1 "Incoming telegram" 0 "Not active" ;
VAL_ 860 TEL_BTConnectingSt 1 "Success" 0 "Fail" ;
VAL_ 860 TEL_BTConnectingAct 1 "Active" 0 "Not active" ;
VAL_ 860 TEL_BTDisplayAct 1 "Active" 0 "Not active" ;
VAL_ 926 TEL_TimeVD 1 "Valid" 0 "Not valid" ;
VAL_ 160 TEL_PCS_EventRecordCtrlReq 3 "Not used" 2 "On" 1 "Off" 0 "No command" ;
VAL_ 160 TEL_PCS_CtrlReq 3 "Not used" 2 "On" 1 "Off" 0 "No command" ;
VAL_ 1103 GWM_NMSleepAck 1 "Active" 0 "Not active" ;
VAL_ 1103 GWM_NMSleepInd 1 "Active" 0 "Not active" ;
VAL_ 1103 GWM_NMLimpHome 1 "Active" 0 "Not active" ;
VAL_ 1103 GWM_NMRing 1 "Active" 0 "Not active" ;
VAL_ 1103 GWM_NMAlive 1 "Active" 0 "Not active" ;
VAL_ 802 GW_VehicleModeBroadcast 15 "Reserved" 14 "Reserved" 13 "Reserved" 12 "Reserved" 11 "Reserved" 10 "Reserved" 9 "Reserved" 8 "Reserved" 7 "Reserved" 6 "Reserved" 5 "Reserved" 4 "Reserved" 3 "Reserved" 2 "Reserved" 1 "OTA Mode" 0 "Normal Mode" ;
VAL_ 968 GW_TransportationMode 1 "Enable" 0 "Disable" ;
VAL_ 968 GW_LowBatPreWarning 7 "not used" 6 "not used" 5 "level 5" 4 "level 4" 3 "level 3" 2 "level 2" 1 "level 1" 0 "off" ;
VAL_ 854 GSM_WarnInfo 15 "reserved" 14 "reserved" 13 "reserved" 12 "reserved" 11 "reserved" 10 "reserved" 9 "reserved" 8 "reserved" 7 "Engine start if want shift;" 6 "ACM failure;" 5 "fasten seat belt if want shift;" 4 "close door if want shift;" 3 "please check shifter;" 2 "vehcile speed too high;" 1 "press brake if want shift;" 0 "no warn;" ;
VAL_ 854 GSM_GearShiftLeverPstReq 15 "Not used" 14 "Not used" 13 "Not used" 12 "Not used" 11 "Not used" 10 "M-" 9 "M+" 8 "M" 7 "S" 6 "D-" 5 "D+" 4 "D" 3 "N" 2 "R" 1 "P" 0 "Invalid" ;
VAL_ 854 GSM_DriveModeRespFail 15 "Not used" 14 "Not used" 13 "Not used" 12 "Not used" 11 "Not used" 10 "Not used" 9 "Not used" 8 "Not used" 7 "Not used" 6 "ATS not allow mode change" 5 "Manual mode response fail" 4 "Winter mode response fail" 3 "Sport mode response fail" 2 "ECO mode response fail" 1 "Normal mode repsones fail" 0 "Not fail" ;
VAL_ 786 MRR_PEBSObjType 15 "Not used" 14 "Not used" 13 "Not used" 12 "Not used" 11 "Not used" 10 "Not used" 9 "Not used" 8 "Not used" 7 "Not used" 6 "Not used" 5 "Unknown" 4 "Trunk" 3 "Cyclist" 2 "Pedestrian" 1 "Car " 0 "No display" ;
VAL_ 786 MRR_ACCQuitSound 1 "sound remind" 0 "No remind" ;
VAL_ 786 MRR_ISLACC_St 1 "on" 0 "off" ;
VAL_ 786 MRR_FCWWarnDistance 3 "Not used" 2 "Far" 1 "Close" 0 "Normal" ;
VAL_ 786 MRR_AEBInterventionSt 1 "Intervention" 0 "No intervention" ;
VAL_ 786 MRR_AEBOffSt 1 "Off" 0 "On" ;
VAL_ 786 MRR_AEBFaultSt 1 "Fault" 0 "Not fault" ;
VAL_ 786 MRR_AEB_PEDPFaultSt 1 "Fault" 0 "Not fault" ;
VAL_ 786 MRR_FCWLatentWarn 3 "Not used" 2 "Not used" 1 "Warning" 0 "No warning" ;
VAL_ 786 MRR_FCWPreWarn 3 "Not used" 2 "Not used" 1 "Warning" 0 "No warning" ;
VAL_ 786 MRR_FCWInterventionSt 1 "Intervention" 0 "No intervention" ;
VAL_ 786 MRR_FCWFaultSt 1 "Fault" 0 "Not fault" ;
VAL_ 786 MRR_FCWOffSt 1 "Off" 0 "On" ;
VAL_ 786 MRR_TauGapSet 7 "Not used" 6 "Not used" 5 "Not used" 4 "TauGap 4" 3 "TauGap3" 2 "TauGap 2" 1 "TauGap 1" 0 "TauGap 0" ;
VAL_ 786 MRR_TargetDistanceSt 7 "Not used" 6 "Not used" 5 "Not used" 4 "Distance 4" 3 "Distance 3" 2 "Distance 2" 1 "Distance 1" 0 "Distance 0" ;
VAL_ 786 MRR_ObjectCapturedSt 1 "Object captured" 0 "No object captured" ;
VAL_ 786 MRR_ACCTakeOverReq 1 "Driver takeover request" 0 "No request" ;
VAL_ 786 MRR_ACCFuncCancel 3 "Not used" 2 "ACC condition dissatisfy" 1 "ACC function cancel" 0 "Not active" ;
VAL_ 786 MRR_ACCGoNotifier 1 "Go notifier alert" 0 "No alert" ;
VAL_ 786 MRR_ACCActiveSt 1 "Active" 0 "Not active" ;
VAL_ 786 MRR_ACCFaultSt 3 "Not used" 2 "Not used" 1 "Fault" 0 "Not fault" ;
VAL_ 786 MRR_ACCMode 7 "Failure mode" 6 "Standstill" 5 "Override" 4 "Brake only mode" 3 "Active control mode" 2 "Standby mode" 1 "passive mode" 0 "Off mode" ;
VAL_ 861 TMM_ThermalWarning 1 "True" 0 "False" ;
VAL_ 861 TMM_CouplingThermalFailSafe 1 "True" 0 "False" ;
VAL_ 861 TMM_DiagnosticLampReq 1 "Fault" 0 "Not fault" ;
VAL_ 861 TMM_SysOperatingMode 15 "Not used" 14 "Not used" 13 "Not used" 12 "Not used" 11 "Not used" 10 "Not used" 9 "Not used" 8 "ECO mode" 7 "Sport mode (Active)" 6 "Mode 4WD Low Range" 5 "Mode neutral" 4 "Mode active (Auto)" 3 "Mode 4WD (Lock)" 2 "Mode 2WD(Eco)" 1 "System fault" 0 "Mode unknown" ;
VAL_ 840 EPS_FunctionStyleSt 3 "Sport" 2 "Light" 1 "Comfort" 0 "Unknow" ;
VAL_ 840 EPS_WarnLamp 1 "Fail present" 0 "Fail not present" ;
VAL_ 775 EPB_SysDispMsgReq 15 "Not used" 14 "Not used" 13 "Not used" 12 "Not used" 11 "Not used" 10 "Not used" 9 "Not used" 8 "Please switch to non P gear to release park brake" 7 "Clampforce not enough" 6 "Park brake testing" 5 "Park brake released" 4 "Park brake set" 3 "Check park brake at low gradient" 2 "Release park brake switch " 1 "Fasten seatbelt" 0 "Off" ;
VAL_ 775 EPB_FailSt 1 "Error" 0 "No error" ;
VAL_ 775 EPB_SysAudWarnReq 7 "Not used        " 6 "Not used" 5 "Not used" 4 "Not used" 3 "Not used" 2 "Waming#2" 1 "Waming #1" 0 "Off" ;
VAL_ 775 EPB_SysSt 7 "Fault(not sure position)" 6 "Not used" 5 "Not used" 4 "Disengaged" 3 "Applying" 2 "Releasing" 1 "Apply (fully applied)" 0 "Release (fully released)" ;
VAL_ 816 SRS_Row2MiddleSeatBeltSt 3 "Invalid" 2 "Not used" 1 "Unfastened" 0 "Fastened" ;
VAL_ 816 SRS_Row2RightSeatBeltSt 3 "Invalid" 2 "Not used" 1 "Unfastened" 0 "Fastened" ;
VAL_ 816 SRS_AirbagFaultSt 1 "Fault" 0 "Not fault" ;
VAL_ 816 SRS_Row2LeftSeatBeltSt 3 "Invalid" 2 "Not used" 1 "Unfastened" 0 "Fastened" ;
VAL_ 816 SRS_DriverSeatBeltSt 3 "Not available/default" 2 "Failed" 1 "Unfastened" 0 "Fastened " ;
VAL_ 816 SRS_PsngrSeatBeltSt 3 "Not available/default" 2 "Failed" 1 "Unfastened" 0 "Fastened " ;
VAL_ 829 SAS_TrimmingStatus 1 "Sensor trimmed" 0 "Sensor not trimmed" ;
VAL_ 829 SAS_CalibratedSt 1 "Calibrated" 0 "Not calibrated" ;
VAL_ 829 SAS_SteeringAngleVD 1 "Valid" 0 "Not valid" ;
VAL_ 667 BCS_RRWheelRotatedDirection 1 "Backward" 0 "Forward" ;
VAL_ 667 BCS_RRWheelRotatedDirectionVD 1 "Valid" 0 "Not valid" ;
VAL_ 667 BCS_RLWheelRotatedDirectionVD 1 "Valid" 0 "Not valid" ;
VAL_ 667 BCS_RLWheelRotatedDirection 1 "Backward" 0 "Forward" ;
VAL_ 667 BCS_FRWheelRotatedDirection 1 "Backward" 0 "Forward" ;
VAL_ 667 BCS_FRWheelRotatedDirectionVD 1 "Valid" 0 "Not valid" ;
VAL_ 667 BCS_FLWheelRotatedDirectionVD 1 "Valid" 0 "Not valid" ;
VAL_ 667 BCS_FLWheelRotatedDirection 1 "Backward" 0 "Forward" ;
VAL_ 667 BCS_RRWheelSpdVD 1 "Valid" 0 "Not valid" ;
VAL_ 667 BCS_RLWheelSpdVD 1 "Valid" 0 "Not valid" ;
VAL_ 667 BCS_FRWheelSpdVD 1 "Valid" 0 "Not valid" ;
VAL_ 667 BCS_FLWheelSpdVD 1 "Valid" 0 "Not valid" ;
VAL_ 838 BCS_HBBSt 3 "HBB Disabled" 2 "HBB Failed Boost Backup" 1 "HBB_FailedBoost" 0 "HBB Normal mode" ;
VAL_ 838 BCS_CDDAvailable 1 "Available" 0 "Not available" ;
VAL_ 838 BCS_CDDActive 1 "Active" 0 "Not active" ;
VAL_ 838 BCS_AWBAvailable 1 "Available" 0 "Not available" ;
VAL_ 838 BCS_AWBActive 1 "Active" 0 "Not active" ;
VAL_ 838 BCS_AEBAvailable 1 "Available" 0 "Not available" ;
VAL_ 838 BCS_AEBActive 1 "Active" 0 "Not active" ;
VAL_ 838 BCS_ABPAvailable 1 "Available" 0 "Not available" ;
VAL_ 838 BCS_ABPActive 1 "Active" 0 "Not active" ;
VAL_ 838 BCS_AVHAvailable 1 "Available" 0 "Not available" ;
VAL_ 838 BCS_AVHStandby 1 "Standby" 0 "Not standby" ;
VAL_ 838 BCS_AVHSt 1 "Active" 0 "Not active" ;
VAL_ 838 BCS_HDCErrSt 1 "Error" 0 "No error" ;
VAL_ 838 BCS_HHCErrSt 1 "Error" 0 "No error" ;
VAL_ 838 BCS_ABAavailable 1 "Available" 0 "Not available" ;
VAL_ 838 BCS_ABAactive 1 "Active" 0 "Not active" ;
VAL_ 838 BCS_HDCCtrlSt 3 "Not used" 2 "On not active braking" 1 "On active braking" 0 "Off" ;
VAL_ 838 BCS_VDCOff 1 "Off" 0 "On" ;
VAL_ 838 BCS_TCSOff 1 "Off" 0 "On" ;
VAL_ 838 BCS_BrakeOverHeat 1 "Temp too high" 0 "Not high" ;
VAL_ 608 BCS_VDCActiveSt 1 "Active" 0 "Not active" ;
VAL_ 608 BCS_VehSpdVD 1 "Valid" 0 "Not Valid" ;
VAL_ 608 BCS_VDCFaultSt 1 "Fault" 0 "Not fault" ;
VAL_ 608 BCS_TCSActiveSt 1 "Active" 0 "Not active" ;
VAL_ 608 BCS_TCSFaultSt 1 "Fault" 0 "Not fault" ;
VAL_ 608 BCS_EBDActiveSt 1 "Active" 0 "Not active" ;
VAL_ 608 BCS_EBDFaultSt 1 "Fault" 0 "Not fault" ;
VAL_ 608 BCS_ABSFaultSt 1 "Fault" 0 "Not fault" ;
VAL_ 608 BCS_ABSActiveSt 1 "Active" 0 "Not active" ;
VAL_ 823 BCS_RRWheelSpdEdgesSumVD 1 "Valid" 0 "Not valid" ;
VAL_ 823 BCS_RLWheelSpdEdgesSumVD 1 "Valid" 0 "Not valid" ;
VAL_ 823 BCS_FRWheelSpdEdgesSumVD 1 "Valid" 0 "Not valid" ;
VAL_ 823 BCS_FLWheelSpdEdgesSumVD 1 "Valid" 0 "Not valid" ;
VAL_ 822 EMS_EngSpdVD 1 "Valid" 0 "Not valid" ;
VAL_ 822 EMS_EngWaterTempVD 1 "Valid" 0 "Not valid" ;
VAL_ 822 EMS_EngSt 1 "Run " 0 "Not run" ;
VAL_ 822 EMS_EPCSt 1 "ON" 0 "OFF" ;
VAL_ 822 EMS_MilSt 1 "Fault" 0 "Not fault" ;
VAL_ 785 RLR_AudioWarnRL 3 "Reserved" 2 "Reserved" 1 "Warning " 0 "No Warning" ;
VAL_ 785 RLR_AudioWarnFL 3 "Reserved" 2 "Reserved" 1 "Warning " 0 "No Warning" ;
VAL_ 785 RRR_RCTAAssistType 3 "brake and Warning" 2 "Warning" 1 "brake" 0 "No Selected" ;
VAL_ 785 RLR_RCTAWarnLeft 3 "Not used" 2 "Warming level 2" 1 "Warning level 1" 0 "No warning" ;
VAL_ 785 RLR_LCAWarnLeft 3 "Not used" 2 "Warning level 2" 1 "Warning level 1" 0 "No warning" ;
VAL_ 785 RRR_AudioWarnFR 3 "Reserved" 2 "Reserved" 1 "Warning " 0 "No Warning" ;
VAL_ 785 RRR_RCWWarn 3 "Not used" 2 "Warning level 2" 1 "Warning level 1" 0 "No warning" ;
VAL_ 785 RRR_RCWSt 3 "Failure" 2 "Active" 1 "Passive/On/Inactive" 0 "Off" ;
VAL_ 785 RRR_RCTAWarnRight 3 "Not used" 2 "Warming level 2" 1 "Warning level 1" 0 "No warning" ;
VAL_ 785 RRR_LCAWarnRight 3 "Not used" 2 "Warning level 2" 1 "Warning level 1" 0 "No warning" ;
VAL_ 785 RLR_VibrWarnL 1 " Warning" 0 " No Warning" ;
VAL_ 785 RRR_LCASt 3 " Failure" 2 " Active" 1 " Passive" 0 " OFF" ;
VAL_ 785 RRR_RCTASt 3 " Failure" 2 " Active" 1 " Passive" 0 " OFF" ;
VAL_ 785 RRR_DOWSt 3 " Failure" 2 " Active" 1 " Passive" 0 " OFF" ;
VAL_ 785 RLR_ExMirLedWarnL 3 " Reserved" 2 " Flashing（Warning level 2）" 1 " Continue ON（Warning level 1）" 0 " OFF" ;
VAL_ 785 RLR_IALWarnRL 3 " Reserved" 2 " Warning level 2" 1 " Warning level 1" 0 " No Warning" ;
VAL_ 785 RLR_IALWarnFL 3 " Reserved" 2 " Warning level 2" 1 " Warning level 1" 0 " No Warning" ;
VAL_ 785 RRR_ExMirLedWarnR 3 " Reserved" 2 " Flashing（Warning level 2）" 1 " Continue ON（Warning level 1）" 0 " OFF" ;
VAL_ 785 RRR_VibrWarnR 1 " Warning" 0 " No Warning" ;
VAL_ 785 RRR_IALWarnRR 3 " Reserved" 2 " Warning level 2" 1 " Warning level 1" 0 " No Warning" ;
VAL_ 785 RRR_IALWarnFR 3 " Reserved" 2 " Warning level 2" 1 " Warning level 1" 0 " No Warning" ;
VAL_ 785 RRR_MRRSt 7 "Reserved" 6 "Reserved" 5 "Reserved" 4 " initializing" 3 " Temporary Error" 2 " System Error" 1 " Sensor Covered" 0 " ON" ;
VAL_ 785 RRR_ClusterLamp 7 "Reserved" 6 "Reserved" 5 "Reserved" 4 "Reserved" 3 "Reserved" 2 " Continue ON(Green)" 1 " Continue ON(Yellow)" 0 " OFF" ;
VAL_ 439 PCU_RejectHeatProtectINH_OH 1 "Failure" 0 "Normal" ;
VAL_ 439 PCU_UnlockFault 1 "Fault detected" 0 "No fault detected" ;
VAL_ 439 PCU_LockFault 1 "Fault detected" 0 "No fault detected" ;
VAL_ 439 PCU_LampRequest 1 "ON" 0 "OFF" ;
VAL_ 762 HOD_VBattOORFault 1 "Fault" 0 "Not Fault" ;
VAL_ 762 HOD_FaultSt 1 "Fault" 0 "Not Fault" ;
VAL_ 762 HOD_LINComFault 1 "Fault" 0 "Not Fault" ;
VAL_ 762 HOD_CalibrationSt 1 "Calibrated" 0 "Not Calibrated" ;
VAL_ 762 HOD_ApRestSt 1 "Application reset" 0 "No Application reset" ;
VAL_ 762 HOD_HeatingSt 3 "Reserved" 2 "Preservation" 1 "heating" 0 "off" ;
VAL_ 762 HOD_TouchZone3 1 "True" 0 "False" ;
VAL_ 762 HOD_TouchZone2 1 "True" 0 "False" ;
VAL_ 762 HOD_TouchZone1 1 "True" 0 "False" ;
VAL_ 728 CDC_ProhibitChangingMode 1 "Prohibit" 0 "No prohibit" ;
VAL_ 728 CDC_WarningLampReq 1 "Lamp on" 0 "Lamp off" ;
VAL_ 728 CDC_CurrentDamperMode 7 "Not used" 6 "Not used" 5 "Not used" 4 "Not used" 3 "Sport" 2 "Normal" 1 "Comfort" 0 "No Command" ;
VAL_ 1055 SBM_NMWakeupOrignin 255 "Reserved" 254 "Reserved" 253 "Reserved" 252 "Reserved" 251 "Reserved" 250 "Reserved" 249 "Reserved" 248 "Reserved" 247 "Reserved" 246 "Reserved" 245 "Reserved" 244 "Reserved" 243 "Reserved" 242 "Reserved" 241 "Reserved" 240 "Reserved" 239 "Reserved" 238 "Reserved" 237 "Reserved" 236 "Reserved" 235 "Reserved" 234 "Reserved" 233 "Reserved" 232 "Reserved" 231 "Reserved" 230 "Reserved" 229 "Reserved" 228 "Reserved" 227 "Reserved" 226 "Reserved" 225 "Reserved" 224 "Reserved" 223 "Reserved" 222 "Reserved" 221 "Reserved" 220 "Reserved" 219 "Reserved" 218 "Reserved" 217 "Reserved" 216 "Reserved" 215 "Reserved" 214 "Reserved" 213 "Reserved" 212 "Reserved" 211 "Reserved" 210 "Reserved" 209 "Reserved" 208 "Reserved" 207 "Reserved" 206 "Reserved" 205 "Reserved" 204 "Reserved" 203 "Reserved" 202 "Reserved" 201 "Reserved" 200 "Reserved" 199 "Reserved" 198 "Reserved" 197 "Reserved" 196 "Reserved" 195 "Reserved" 194 "Reserved" 193 "Reserved" 192 "Reserved" 191 "Reserved" 190 "Reserved" 189 "Reserved" 188 "Reserved" 187 "Reserved" 186 "Reserved" 185 "Reserved" 184 "Reserved" 183 "Reserved" 182 "Reserved" 181 "Reserved" 180 "Reserved" 179 "Reserved" 178 "Reserved" 177 "Reserved" 176 "Reserved" 175 "Reserved" 174 "Reserved" 173 "Reserved" 172 "Reserved" 171 "Reserved" 170 "Reserved" 169 "Reserved" 168 "Reserved" 167 "Reserved" 166 "Reserved" 165 "Reserved" 164 "Reserved" 163 "Reserved" 162 "Reserved" 161 "Reserved" 160 "Reserved" 159 "Reserved" 158 "Reserved" 157 "Reserved" 156 "Reserved" 155 "Reserved" 154 "Reserved" 153 "Reserved" 152 "Reserved" 151 "Reserved" 150 "Reserved" 149 "Reserved" 148 "Reserved" 147 "Reserved" 146 "Reserved" 145 "Reserved" 144 "Reserved" 143 "Reserved" 142 "Reserved" 141 "Reserved" 140 "Reserved" 139 "Reserved" 138 "Reserved" 137 "Reserved" 136 "Reserved" 135 "Reserved" 134 "Reserved" 133 "Reserved" 132 "Reserved" 131 "Reserved" 130 "Reserved" 129 "Reserved" 128 "Reserved" 127 "Reserved" 126 "Reserved" 125 "Reserved" 124 "Reserved" 123 "Reserved" 122 "Reserved" 121 "Reserved" 120 "Reserved" 119 "Reserved" 118 "Reserved" 117 "Reserved" 116 "Reserved" 115 "Reserved" 114 "Reserved" 113 "Reserved" 112 "Reserved" 111 "Reserved" 110 "Reserved" 109 "Reserved" 108 "Reserved" 107 "Reserved" 106 "Reserved" 105 "Reserved" 104 "Reserved" 103 "Reserved" 102 "Reserved" 101 "Reserved" 100 "Reserved" 99 "Reserved" 98 "Reserved" 97 "Reserved" 96 "Reserved" 95 "Reserved" 94 "Reserved" 93 "Reserved" 92 "Reserved" 91 "Reserved" 90 "Reserved" 89 "Reserved" 88 "Reserved" 87 "Reserved" 86 "Reserved" 85 "Reserved" 84 "Reserved" 83 "Reserved" 82 "Reserved" 81 "Reserved" 80 "Reserved" 79 "Reserved" 78 "Reserved" 77 "Reserved" 76 "Reserved" 75 "Reserved" 74 "Reserved" 73 "Reserved" 72 "Reserved" 71 "Reserved" 70 "Reserved" 69 "Reserved" 68 "Reserved" 67 "Reserved" 66 "Reserved" 65 "Reserved" 64 "Reserved" 63 "Reserved" 62 "Reserved" 61 "Reserved" 60 "Reserved" 59 "Reserved" 58 "Reserved" 57 "Reserved" 56 "Reserved" 55 "Reserved" 54 "Reserved" 53 "Reserved" 52 "Reserved" 51 "Reserved" 50 "Reserved" 49 "Reserved" 48 "Reserved" 47 "Reserved" 46 "Reserved" 45 "Reserved" 44 "Reserved" 43 "Reserved" 42 "Reserved" 41 "Reserved" 40 "Reserved" 39 "Reserved" 38 "Reserved" 37 "Reserved" 36 "Reserved" 35 "Reserved" 34 "Reserved" 33 "Reserved" 32 "Reserved" 31 "Reserved" 30 "Reserved" 29 "Reserved" 28 "Reserved" 27 "Reserved" 26 "Reserved" 25 "Reserved" 24 "Reserved" 23 "Reserved" 22 "Reserved" 21 "Reserved" 20 "Reserved" 19 "Reserved" 18 "IGN ON" 17 " Not used" 16 " Not used" 15 " Not used" 14 " Not used" 13 " Not used" 12 " Not used" 11 " Not used" 10 " Not used" 9 " Not used" 8 " Not used" 7 " Not used" 6 " Not used" 5 " Not used" 4 " Not used" 3 " Not used" 2 " Not used" 1 "Message wake up" ;
VAL_ 1055 SBM_NMSleepAck 1 "Active" 0 "Not active" ;
VAL_ 1055 SBM_NMSleepInd 1 "Active" 0 "Not active" ;
VAL_ 1055 SBM_NMLimpHome 1 "Active" 0 "Not active" ;
VAL_ 1055 SBM_NMRing 1 "Active" 0 "Not active" ;
VAL_ 1055 SBM_NMAlive 1 "Active" 0 "Not active" ;
VAL_ 1013 SBM_OpIndicationWarning 15 "Reserved" 14 "Reserved" 13 "Reserved" 12 "Reserved" 11 "Reserved" 10 "Reserved" 9 "Reserved" 8 "wanrning 8 index" 7 "warning 7 index" 6 "warning 6 index" 5 "warning 5 index" 4 "warning 4 index" 3 "warning 3 index" 2 "warning 2 index" 1 "warning 1 index" 0 "Not used" ;
VAL_ 1013 SBM_Phone_Connectingst 3 "Pair and  auth " 2 "Pair Not  auth" 1 "disconnecting        " 0 "Default                                     " ;
VAL_ 1001 SBM_fatigueDringWarning 3 "not used" 2 "not used" 1 "warning(drving time  more than 4 hours)" 0 "not warning" ;
